VERSION ""

NS_ :

BS_:

BU_: BAU BCU

BO_ 3221225472 VECTOR__INDEPENDENT_SIG_MSG: 0 Vector__XXX
 SG_ VAR_SYS_PRECHRG_VOL : 0|16@1+ (0.1,0) [0|6553.5] "V" Vector__XXX
 SG_ CELL_INFO3 : 0|16@1- (1,0) [-32768|32767] "NAN" Vector__XXX
 SG_ CELL_INFO2 : 0|16@1- (1,0) [-32768|32767] "NAN" Vector__XXX
 SG_ CELL_INFO1 : 0|16@1- (1,0) [-32768|32767] "NAN" Vector__XXX
 SG_ INDEX : 0|10@1+ (1,0) [0|0] "" Vector__XXX
 SG_ SENT_INDEX : 0|2@1+ (1,0) [0|63] "" Vector__XXX
 SG_ SENT_TYPE : 0|4@1+ (1,0) [0|63] "" Vector__XXX
 SG_ VAR_SYS_PRECHRG_EEROR : 0|8@1+ (1,0) [0|255] "NAN" Vector__XXX

BO_ 2449731488 BCU1203EFA0: 64 BCU
 SG_ SINGLE_DISCHARGE_AH : 176|16@1+ (0.1,0) [0|6553.5] "AH" Vector__XXX
 SG_ SINGLE_DISCHARGE_EN : 160|16@1+ (0.1,0) [0|6553.5] "KWH" Vector__XXX
 SG_ SINGLE_CHARGE_AH : 144|16@1+ (0.1,0) [0|6553.5] "AH" Vector__XXX
 SG_ SINGLE_CHARGE_EN : 128|16@1+ (0.1,0) [0|6553.5] "KWH" Vector__XXX
 SG_ DAILY_DISCHARGE_AH : 112|16@1+ (0.1,0) [0|6553.5] "AH" Vector__XXX
 SG_ DAILY_DISCHARGE_EN : 96|16@1+ (0.1,0) [0|6553.5] "KWH" Vector__XXX
 SG_ DAILY_CHARGE_AH : 80|16@1+ (0.1,0) [0|6553.5] "AH" Vector__XXX
 SG_ DAILY_CHARGE_EN : 64|16@1+ (0.1,0) [0|6553.5] "KWH" Vector__XXX
 SG_ BCU_RUN_TIME : 32|32@1+ (1,0) [0|4294967295] "s" Vector__XXX
 SG_ BCU_ACC_RUN_TIME : 0|32@1+ (1,0) [0|4294967295] "min" Vector__XXX

BO_ 2462773152 BCU12CAEFA0: 64 BCU
 SG_ BALANCE_TEMP_ID_033 : 0|16@1- (0.1,0) [-3276.8|3276.7] "degC" Vector__XXX
 SG_ BALANCE_TEMP_ID_034 : 16|16@1- (0.1,0) [-3276.8|3276.7] "degC" Vector__XXX
 SG_ BALANCE_TEMP_ID_035 : 32|16@1- (0.1,0) [-3276.8|3276.7] "degC" Vector__XXX
 SG_ BALANCE_TEMP_ID_036 : 48|16@1- (0.1,0) [-3276.8|3276.7] "degC" Vector__XXX
 SG_ BALANCE_TEMP_ID_037 : 64|16@1- (0.1,0) [-3276.8|3276.7] "degC" Vector__XXX
 SG_ BALANCE_TEMP_ID_038 : 80|16@1- (0.1,0) [-3276.8|3276.7] "degC" Vector__XXX
 SG_ BALANCE_TEMP_ID_039 : 96|16@1- (0.1,0) [-3276.8|3276.7] "degC" Vector__XXX
 SG_ BALANCE_TEMP_ID_040 : 112|16@1- (0.1,0) [-3276.8|3276.7] "degC" Vector__XXX
 SG_ BALANCE_TEMP_ID_041 : 128|16@1- (0.1,0) [-3276.8|3276.7] "degC" Vector__XXX
 SG_ BALANCE_TEMP_ID_042 : 144|16@1- (0.1,0) [-3276.8|3276.7] "degC" Vector__XXX
 SG_ BALANCE_TEMP_ID_043 : 160|16@1- (0.1,0) [-3276.8|3276.7] "degC" Vector__XXX
 SG_ BALANCE_TEMP_ID_044 : 176|16@1- (0.1,0) [-3276.8|3276.7] "degC" Vector__XXX
 SG_ BALANCE_TEMP_ID_045 : 192|16@1- (0.1,0) [-3276.8|3276.7] "degC" Vector__XXX
 SG_ BALANCE_TEMP_ID_046 : 208|16@1- (0.1,0) [-3276.8|3276.7] "degC" Vector__XXX
 SG_ BALANCE_TEMP_ID_047 : 224|16@1- (0.1,0) [-3276.8|3276.7] "degC" Vector__XXX
 SG_ BALANCE_TEMP_ID_048 : 240|16@1- (0.1,0) [-3276.8|3276.7] "degC" Vector__XXX
 SG_ BALANCE_TEMP_ID_049 : 256|16@1- (0.1,0) [-3276.8|3276.7] "degC" Vector__XXX
 SG_ BALANCE_TEMP_ID_050 : 272|16@1- (0.1,0) [-3276.8|3276.7] "degC" Vector__XXX
 SG_ BALANCE_TEMP_ID_051 : 288|16@1- (0.1,0) [-3276.8|3276.7] "degC" Vector__XXX
 SG_ BALANCE_TEMP_ID_052 : 304|16@1- (0.1,0) [-3276.8|3276.7] "degC" Vector__XXX
 SG_ BALANCE_TEMP_ID_053 : 320|16@1- (0.1,0) [-3276.8|3276.7] "degC" Vector__XXX
 SG_ BALANCE_TEMP_ID_054 : 336|16@1- (0.1,0) [-3276.8|3276.7] "degC" Vector__XXX
 SG_ BALANCE_TEMP_ID_055 : 352|16@1- (0.1,0) [-3276.8|3276.7] "degC" Vector__XXX
 SG_ BALANCE_TEMP_ID_056 : 368|16@1- (0.1,0) [-3276.8|3276.7] "degC" Vector__XXX
 SG_ BALANCE_TEMP_ID_057 : 384|16@1- (0.1,0) [-3276.8|3276.7] "degC" Vector__XXX
 SG_ BALANCE_TEMP_ID_058 : 400|16@1- (0.1,0) [-3276.8|3276.7] "degC" Vector__XXX
 SG_ BALANCE_TEMP_ID_059 : 416|16@1- (0.1,0) [-3276.8|3276.7] "degC" Vector__XXX
 SG_ BALANCE_TEMP_ID_060 : 432|16@1- (0.1,0) [-3276.8|3276.7] "degC" Vector__XXX
 SG_ BALANCE_TEMP_ID_061 : 448|16@1- (0.1,0) [-3276.8|3276.7] "degC" Vector__XXX
 SG_ BALANCE_TEMP_ID_062 : 464|16@1- (0.1,0) [-3276.8|3276.7] "degC" Vector__XXX
 SG_ BALANCE_TEMP_ID_063 : 480|16@1- (0.1,0) [-3276.8|3276.7] "degC" Vector__XXX
 SG_ BALANCE_TEMP_ID_064 : 496|16@1- (0.1,0) [-3276.8|3276.7] "degC" Vector__XXX

BO_ 2462707616 BCU12C9EFA0: 64 BCU
 SG_ BALANCE_TEMP_ID_001 : 0|16@1- (0.1,0) [-3276.8|3276.7] "degC" Vector__XXX
 SG_ BALANCE_TEMP_ID_002 : 16|16@1- (0.1,0) [-3276.8|3276.7] "degC" Vector__XXX
 SG_ BALANCE_TEMP_ID_003 : 32|16@1- (0.1,0) [-3276.8|3276.7] "degC" Vector__XXX
 SG_ BALANCE_TEMP_ID_004 : 48|16@1- (0.1,0) [-3276.8|3276.7] "degC" Vector__XXX
 SG_ BALANCE_TEMP_ID_005 : 64|16@1- (0.1,0) [-3276.8|3276.7] "degC" Vector__XXX
 SG_ BALANCE_TEMP_ID_006 : 80|16@1- (0.1,0) [-3276.8|3276.7] "degC" Vector__XXX
 SG_ BALANCE_TEMP_ID_007 : 96|16@1- (0.1,0) [-3276.8|3276.7] "degC" Vector__XXX
 SG_ BALANCE_TEMP_ID_008 : 112|16@1- (0.1,0) [-3276.8|3276.7] "degC" Vector__XXX
 SG_ BALANCE_TEMP_ID_009 : 128|16@1- (0.1,0) [-3276.8|3276.7] "degC" Vector__XXX
 SG_ BALANCE_TEMP_ID_010 : 144|16@1- (0.1,0) [-3276.8|3276.7] "degC" Vector__XXX
 SG_ BALANCE_TEMP_ID_011 : 160|16@1- (0.1,0) [-3276.8|3276.7] "degC" Vector__XXX
 SG_ BALANCE_TEMP_ID_012 : 176|16@1- (0.1,0) [-3276.8|3276.7] "degC" Vector__XXX
 SG_ BALANCE_TEMP_ID_013 : 192|16@1- (0.1,0) [-3276.8|3276.7] "degC" Vector__XXX
 SG_ BALANCE_TEMP_ID_014 : 208|16@1- (0.1,0) [-3276.8|3276.7] "degC" Vector__XXX
 SG_ BALANCE_TEMP_ID_015 : 224|16@1- (0.1,0) [-3276.8|3276.7] "degC" Vector__XXX
 SG_ BALANCE_TEMP_ID_016 : 240|16@1- (0.1,0) [-3276.8|3276.7] "degC" Vector__XXX
 SG_ BALANCE_TEMP_ID_017 : 256|16@1- (0.1,0) [-3276.8|3276.7] "degC" Vector__XXX
 SG_ BALANCE_TEMP_ID_018 : 272|16@1- (0.1,0) [-3276.8|3276.7] "degC" Vector__XXX
 SG_ BALANCE_TEMP_ID_019 : 288|16@1- (0.1,0) [-3276.8|3276.7] "degC" Vector__XXX
 SG_ BALANCE_TEMP_ID_020 : 304|16@1- (0.1,0) [-3276.8|3276.7] "degC" Vector__XXX
 SG_ BALANCE_TEMP_ID_021 : 320|16@1- (0.1,0) [-3276.8|3276.7] "degC" Vector__XXX
 SG_ BALANCE_TEMP_ID_022 : 336|16@1- (0.1,0) [-3276.8|3276.7] "degC" Vector__XXX
 SG_ BALANCE_TEMP_ID_023 : 352|16@1- (0.1,0) [-3276.8|3276.7] "degC" Vector__XXX
 SG_ BALANCE_TEMP_ID_024 : 368|16@1- (0.1,0) [-3276.8|3276.7] "degC" Vector__XXX
 SG_ BALANCE_TEMP_ID_025 : 384|16@1- (0.1,0) [-3276.8|3276.7] "degC" Vector__XXX
 SG_ BALANCE_TEMP_ID_026 : 400|16@1- (0.1,0) [-3276.8|3276.7] "degC" Vector__XXX
 SG_ BALANCE_TEMP_ID_027 : 416|16@1- (0.1,0) [-3276.8|3276.7] "degC" Vector__XXX
 SG_ BALANCE_TEMP_ID_028 : 432|16@1- (0.1,0) [-3276.8|3276.7] "degC" Vector__XXX
 SG_ BALANCE_TEMP_ID_029 : 448|16@1- (0.1,0) [-3276.8|3276.7] "degC" Vector__XXX
 SG_ BALANCE_TEMP_ID_030 : 464|16@1- (0.1,0) [-3276.8|3276.7] "degC" Vector__XXX
 SG_ BALANCE_TEMP_ID_031 : 480|16@1- (0.1,0) [-3276.8|3276.7] "degC" Vector__XXX
 SG_ BALANCE_TEMP_ID_032 : 496|16@1- (0.1,0) [-3276.8|3276.7] "degC" Vector__XXX

BO_ 2462248864 BCU12C2EFA0: 64 BCU
 SG_ BCU_TERMINAL_TEMP_20_2 : 112|16@1- (0.1,0) [-3276.8|3276.7] "℃" Vector__XXX
 SG_ BCU_TERMINAL_TEMP_20_1 : 96|16@1- (0.1,0) [-3276.8|3276.7] "℃" Vector__XXX
 SG_ BCU_TERMINAL_TEMP_19_2 : 80|16@1- (0.1,0) [-3276.8|3276.7] "℃" Vector__XXX
 SG_ BCU_TERMINAL_TEMP_19_1 : 64|16@1- (0.1,0) [-3276.8|3276.7] "℃" Vector__XXX
 SG_ BCU_TERMINAL_TEMP_18_2 : 48|16@1- (0.1,0) [-3276.8|3276.7] "℃" Vector__XXX
 SG_ BCU_TERMINAL_TEMP_18_1 : 32|16@1- (0.1,0) [-3276.8|3276.7] "℃" Vector__XXX
 SG_ BCU_TERMINAL_TEMP_17_2 : 16|16@1- (0.1,0) [-3276.8|3276.7] "℃" Vector__XXX
 SG_ BCU_TERMINAL_TEMP_17_1 : 0|16@1- (0.1,0) [-3276.8|3276.7] "℃" Vector__XXX

BO_ 2462183328 BCU12C1EFA0: 64 BCU
 SG_ BCU_TERMINAL_TEMP_16_2 : 496|16@1- (0.1,0) [-3276.8|3276.7] "℃" Vector__XXX
 SG_ BCU_TERMINAL_TEMP_16_1 : 480|16@1- (0.1,0) [-3276.8|3276.7] "℃" Vector__XXX
 SG_ BCU_TERMINAL_TEMP_15_2 : 464|16@1- (0.1,0) [-3276.8|3276.7] "℃" Vector__XXX
 SG_ BCU_TERMINAL_TEMP_15_1 : 448|16@1- (0.1,0) [-3276.8|3276.7] "℃" Vector__XXX
 SG_ BCU_TERMINAL_TEMP_14_2 : 432|16@1- (0.1,0) [-3276.8|3276.7] "℃" Vector__XXX
 SG_ BCU_TERMINAL_TEMP_14_1 : 416|16@1- (0.1,0) [-3276.8|3276.7] "℃" Vector__XXX
 SG_ BCU_TERMINAL_TEMP_13_2 : 400|16@1- (0.1,0) [-3276.8|3276.7] "℃" Vector__XXX
 SG_ BCU_TERMINAL_TEMP_13_1 : 384|16@1- (0.1,0) [-3276.8|3276.7] "℃" Vector__XXX
 SG_ BCU_TERMINAL_TEMP_12_2 : 368|16@1- (0.1,0) [-3276.8|3276.7] "℃" Vector__XXX
 SG_ BCU_TERMINAL_TEMP_12_1 : 352|16@1- (0.1,0) [-3276.8|3276.7] "℃" Vector__XXX
 SG_ BCU_TERMINAL_TEMP_11_2 : 336|16@1- (0.1,0) [-3276.8|3276.7] "℃" Vector__XXX
 SG_ BCU_TERMINAL_TEMP_11_1 : 320|16@1- (0.1,0) [-3276.8|3276.7] "℃" Vector__XXX
 SG_ BCU_TERMINAL_TEMP_10_2 : 304|16@1- (0.1,0) [-3276.8|3276.7] "℃" Vector__XXX
 SG_ BCU_TERMINAL_TEMP_10_1 : 288|16@1- (0.1,0) [-3276.8|3276.7] "℃" Vector__XXX
 SG_ BCU_TERMINAL_TEMP_09_2 : 272|16@1- (0.1,0) [-3276.8|3276.7] "℃" Vector__XXX
 SG_ BCU_TERMINAL_TEMP_09_1 : 256|16@1- (0.1,0) [-3276.8|3276.7] "℃" Vector__XXX
 SG_ BCU_TERMINAL_TEMP_08_2 : 240|16@1- (0.1,0) [-3276.8|3276.7] "℃" Vector__XXX
 SG_ BCU_TERMINAL_TEMP_08_1 : 224|16@1- (0.1,0) [-3276.8|3276.7] "℃" Vector__XXX
 SG_ BCU_TERMINAL_TEMP_07_2 : 208|16@1- (0.1,0) [-3276.8|3276.7] "℃" Vector__XXX
 SG_ BCU_TERMINAL_TEMP_07_1 : 192|16@1- (0.1,0) [-3276.8|3276.7] "℃" Vector__XXX
 SG_ BCU_TERMINAL_TEMP_06_2 : 176|16@1- (0.1,0) [-3276.8|3276.7] "℃" Vector__XXX
 SG_ BCU_TERMINAL_TEMP_06_1 : 160|16@1- (0.1,0) [-3276.8|3276.7] "℃" Vector__XXX
 SG_ BCU_TERMINAL_TEMP_05_2 : 144|16@1- (0.1,0) [-3276.8|3276.7] "℃" Vector__XXX
 SG_ BCU_TERMINAL_TEMP_05_1 : 128|16@1- (0.1,0) [-3276.8|3276.7] "℃" Vector__XXX
 SG_ BCU_TERMINAL_TEMP_04_2 : 112|16@1- (0.1,0) [-3276.8|3276.7] "℃" Vector__XXX
 SG_ BCU_TERMINAL_TEMP_04_1 : 96|16@1- (0.1,0) [-3276.8|3276.7] "℃" Vector__XXX
 SG_ BCU_TERMINAL_TEMP_03_2 : 80|16@1- (0.1,0) [-3276.8|3276.7] "℃" Vector__XXX
 SG_ BCU_TERMINAL_TEMP_03_1 : 64|16@1- (0.1,0) [-3276.8|3276.7] "℃" Vector__XXX
 SG_ BCU_TERMINAL_TEMP_02_2 : 48|16@1- (0.1,0) [-3276.8|3276.7] "℃" Vector__XXX
 SG_ BCU_TERMINAL_TEMP_02_1 : 32|16@1- (0.1,0) [-3276.8|3276.7] "℃" Vector__XXX
 SG_ BCU_TERMINAL_TEMP_01_2 : 16|16@1- (0.1,0) [-3276.8|3276.7] "℃" Vector__XXX
 SG_ BCU_TERMINAL_TEMP_01_1 : 0|16@1- (0.1,0) [-3276.8|3276.7] "℃" Vector__XXX

BO_ 2462117792 BCU12C0EFA0: 64 BCU
 SG_ CELL_TEMP_ID_481 : 0|16@1- (0.1,0) [-3276.8|3276.7] "℃" Vector__XXX
 SG_ CELL_TEMP_ID_482 : 16|16@1- (0.1,0) [-3276.8|3276.7] "℃" Vector__XXX
 SG_ CELL_TEMP_ID_483 : 32|16@1- (0.1,0) [-3276.8|3276.7] "℃" Vector__XXX
 SG_ CELL_TEMP_ID_484 : 48|16@1- (0.1,0) [-3276.8|3276.7] "℃" Vector__XXX
 SG_ CELL_TEMP_ID_485 : 64|16@1- (0.1,0) [-3276.8|3276.7] "℃" Vector__XXX
 SG_ CELL_TEMP_ID_486 : 80|16@1- (0.1,0) [-3276.8|3276.7] "℃" Vector__XXX
 SG_ CELL_TEMP_ID_487 : 96|16@1- (0.1,0) [-3276.8|3276.7] "℃" Vector__XXX
 SG_ CELL_TEMP_ID_488 : 112|16@1- (0.1,0) [-3276.8|3276.7] "℃" Vector__XXX
 SG_ CELL_TEMP_ID_489 : 128|16@1- (0.1,0) [-3276.8|3276.7] "℃" Vector__XXX
 SG_ CELL_TEMP_ID_490 : 144|16@1- (0.1,0) [-3276.8|3276.7] "℃" Vector__XXX
 SG_ CELL_TEMP_ID_491 : 160|16@1- (0.1,0) [-3276.8|3276.7] "℃" Vector__XXX
 SG_ CELL_TEMP_ID_492 : 176|16@1- (0.1,0) [-3276.8|3276.7] "℃" Vector__XXX
 SG_ CELL_TEMP_ID_493 : 192|16@1- (0.1,0) [-3276.8|3276.7] "℃" Vector__XXX
 SG_ CELL_TEMP_ID_494 : 208|16@1- (0.1,0) [-3276.8|3276.7] "℃" Vector__XXX
 SG_ CELL_TEMP_ID_495 : 224|16@1- (0.1,0) [-3276.8|3276.7] "℃" Vector__XXX
 SG_ CELL_TEMP_ID_496 : 240|16@1- (0.1,0) [-3276.8|3276.7] "℃" Vector__XXX
 SG_ CELL_TEMP_ID_497 : 256|16@1- (0.1,0) [-3276.8|3276.7] "℃" Vector__XXX
 SG_ CELL_TEMP_ID_498 : 272|16@1- (0.1,0) [-3276.8|3276.7] "℃" Vector__XXX
 SG_ CELL_TEMP_ID_499 : 288|16@1- (0.1,0) [-3276.8|3276.7] "℃" Vector__XXX
 SG_ CELL_TEMP_ID_500 : 304|16@1- (0.1,0) [-3276.8|3276.7] "℃" Vector__XXX
 SG_ CELL_TEMP_ID_501 : 320|16@1- (0.1,0) [-3276.8|3276.7] "℃" Vector__XXX
 SG_ CELL_TEMP_ID_502 : 336|16@1- (0.1,0) [-3276.8|3276.7] "℃" Vector__XXX
 SG_ CELL_TEMP_ID_503 : 352|16@1- (0.1,0) [-3276.8|3276.7] "℃" Vector__XXX
 SG_ CELL_TEMP_ID_504 : 368|16@1- (0.1,0) [-3276.8|3276.7] "℃" Vector__XXX
 SG_ CELL_TEMP_ID_505 : 384|16@1- (0.1,0) [-3276.8|3276.7] "℃" Vector__XXX
 SG_ CELL_TEMP_ID_506 : 400|16@1- (0.1,0) [-3276.8|3276.7] "℃" Vector__XXX
 SG_ CELL_TEMP_ID_507 : 416|16@1- (0.1,0) [-3276.8|3276.7] "℃" Vector__XXX
 SG_ CELL_TEMP_ID_508 : 432|16@1- (0.1,0) [-3276.8|3276.7] "℃" Vector__XXX
 SG_ CELL_TEMP_ID_509 : 448|16@1- (0.1,0) [-3276.8|3276.7] "℃" Vector__XXX
 SG_ CELL_TEMP_ID_510 : 464|16@1- (0.1,0) [-3276.8|3276.7] "℃" Vector__XXX
 SG_ CELL_TEMP_ID_511 : 480|16@1- (0.1,0) [-3276.8|3276.7] "℃" Vector__XXX
 SG_ CELL_TEMP_ID_512 : 496|16@1- (0.1,0) [-3276.8|3276.7] "℃" Vector__XXX

BO_ 2462052256 BCU12BFEFA0: 64 BCU
 SG_ CELL_TEMP_ID_449 : 0|16@1- (0.1,0) [-3276.8|3276.7] "℃" Vector__XXX
 SG_ CELL_TEMP_ID_450 : 16|16@1- (0.1,0) [-3276.8|3276.7] "℃" Vector__XXX
 SG_ CELL_TEMP_ID_451 : 32|16@1- (0.1,0) [-3276.8|3276.7] "℃" Vector__XXX
 SG_ CELL_TEMP_ID_452 : 48|16@1- (0.1,0) [-3276.8|3276.7] "℃" Vector__XXX
 SG_ CELL_TEMP_ID_453 : 64|16@1- (0.1,0) [-3276.8|3276.7] "℃" Vector__XXX
 SG_ CELL_TEMP_ID_454 : 80|16@1- (0.1,0) [-3276.8|3276.7] "℃" Vector__XXX
 SG_ CELL_TEMP_ID_455 : 96|16@1- (0.1,0) [-3276.8|3276.7] "℃" Vector__XXX
 SG_ CELL_TEMP_ID_456 : 112|16@1- (0.1,0) [-3276.8|3276.7] "℃" Vector__XXX
 SG_ CELL_TEMP_ID_457 : 128|16@1- (0.1,0) [-3276.8|3276.7] "℃" Vector__XXX
 SG_ CELL_TEMP_ID_458 : 144|16@1- (0.1,0) [-3276.8|3276.7] "℃" Vector__XXX
 SG_ CELL_TEMP_ID_459 : 160|16@1- (0.1,0) [-3276.8|3276.7] "℃" Vector__XXX
 SG_ CELL_TEMP_ID_460 : 176|16@1- (0.1,0) [-3276.8|3276.7] "℃" Vector__XXX
 SG_ CELL_TEMP_ID_461 : 192|16@1- (0.1,0) [-3276.8|3276.7] "℃" Vector__XXX
 SG_ CELL_TEMP_ID_462 : 208|16@1- (0.1,0) [-3276.8|3276.7] "℃" Vector__XXX
 SG_ CELL_TEMP_ID_463 : 224|16@1- (0.1,0) [-3276.8|3276.7] "℃" Vector__XXX
 SG_ CELL_TEMP_ID_464 : 240|16@1- (0.1,0) [-3276.8|3276.7] "℃" Vector__XXX
 SG_ CELL_TEMP_ID_465 : 256|16@1- (0.1,0) [-3276.8|3276.7] "℃" Vector__XXX
 SG_ CELL_TEMP_ID_466 : 272|16@1- (0.1,0) [-3276.8|3276.7] "℃" Vector__XXX
 SG_ CELL_TEMP_ID_467 : 288|16@1- (0.1,0) [-3276.8|3276.7] "℃" Vector__XXX
 SG_ CELL_TEMP_ID_468 : 304|16@1- (0.1,0) [-3276.8|3276.7] "℃" Vector__XXX
 SG_ CELL_TEMP_ID_469 : 320|16@1- (0.1,0) [-3276.8|3276.7] "℃" Vector__XXX
 SG_ CELL_TEMP_ID_470 : 336|16@1- (0.1,0) [-3276.8|3276.7] "℃" Vector__XXX
 SG_ CELL_TEMP_ID_471 : 352|16@1- (0.1,0) [-3276.8|3276.7] "℃" Vector__XXX
 SG_ CELL_TEMP_ID_472 : 368|16@1- (0.1,0) [-3276.8|3276.7] "℃" Vector__XXX
 SG_ CELL_TEMP_ID_473 : 384|16@1- (0.1,0) [-3276.8|3276.7] "℃" Vector__XXX
 SG_ CELL_TEMP_ID_474 : 400|16@1- (0.1,0) [-3276.8|3276.7] "℃" Vector__XXX
 SG_ CELL_TEMP_ID_475 : 416|16@1- (0.1,0) [-3276.8|3276.7] "℃" Vector__XXX
 SG_ CELL_TEMP_ID_476 : 432|16@1- (0.1,0) [-3276.8|3276.7] "℃" Vector__XXX
 SG_ CELL_TEMP_ID_477 : 448|16@1- (0.1,0) [-3276.8|3276.7] "℃" Vector__XXX
 SG_ CELL_TEMP_ID_478 : 464|16@1- (0.1,0) [-3276.8|3276.7] "℃" Vector__XXX
 SG_ CELL_TEMP_ID_479 : 480|16@1- (0.1,0) [-3276.8|3276.7] "℃" Vector__XXX
 SG_ CELL_TEMP_ID_480 : 496|16@1- (0.1,0) [-3276.8|3276.7] "℃" Vector__XXX

BO_ 2461986720 BCU12BEEFA0: 64 BCU
 SG_ CELL_TEMP_ID_417 : 0|16@1- (0.1,0) [-3276.8|3276.7] "℃" Vector__XXX
 SG_ CELL_TEMP_ID_418 : 16|16@1- (0.1,0) [-3276.8|3276.7] "℃" Vector__XXX
 SG_ CELL_TEMP_ID_419 : 32|16@1- (0.1,0) [-3276.8|3276.7] "℃" Vector__XXX
 SG_ CELL_TEMP_ID_420 : 48|16@1- (0.1,0) [-3276.8|3276.7] "℃" Vector__XXX
 SG_ CELL_TEMP_ID_421 : 64|16@1- (0.1,0) [-3276.8|3276.7] "℃" Vector__XXX
 SG_ CELL_TEMP_ID_422 : 80|16@1- (0.1,0) [-3276.8|3276.7] "℃" Vector__XXX
 SG_ CELL_TEMP_ID_423 : 96|16@1- (0.1,0) [-3276.8|3276.7] "℃" Vector__XXX
 SG_ CELL_TEMP_ID_424 : 112|16@1- (0.1,0) [-3276.8|3276.7] "℃" Vector__XXX
 SG_ CELL_TEMP_ID_425 : 128|16@1- (0.1,0) [-3276.8|3276.7] "℃" Vector__XXX
 SG_ CELL_TEMP_ID_426 : 144|16@1- (0.1,0) [-3276.8|3276.7] "℃" Vector__XXX
 SG_ CELL_TEMP_ID_427 : 160|16@1- (0.1,0) [-3276.8|3276.7] "℃" Vector__XXX
 SG_ CELL_TEMP_ID_428 : 176|16@1- (0.1,0) [-3276.8|3276.7] "℃" Vector__XXX
 SG_ CELL_TEMP_ID_429 : 192|16@1- (0.1,0) [-3276.8|3276.7] "℃" Vector__XXX
 SG_ CELL_TEMP_ID_430 : 208|16@1- (0.1,0) [-3276.8|3276.7] "℃" Vector__XXX
 SG_ CELL_TEMP_ID_431 : 224|16@1- (0.1,0) [-3276.8|3276.7] "℃" Vector__XXX
 SG_ CELL_TEMP_ID_432 : 240|16@1- (0.1,0) [-3276.8|3276.7] "℃" Vector__XXX
 SG_ CELL_TEMP_ID_433 : 256|16@1- (0.1,0) [-3276.8|3276.7] "℃" Vector__XXX
 SG_ CELL_TEMP_ID_434 : 272|16@1- (0.1,0) [-3276.8|3276.7] "℃" Vector__XXX
 SG_ CELL_TEMP_ID_435 : 288|16@1- (0.1,0) [-3276.8|3276.7] "℃" Vector__XXX
 SG_ CELL_TEMP_ID_436 : 304|16@1- (0.1,0) [-3276.8|3276.7] "℃" Vector__XXX
 SG_ CELL_TEMP_ID_437 : 320|16@1- (0.1,0) [-3276.8|3276.7] "℃" Vector__XXX
 SG_ CELL_TEMP_ID_438 : 336|16@1- (0.1,0) [-3276.8|3276.7] "℃" Vector__XXX
 SG_ CELL_TEMP_ID_439 : 352|16@1- (0.1,0) [-3276.8|3276.7] "℃" Vector__XXX
 SG_ CELL_TEMP_ID_440 : 368|16@1- (0.1,0) [-3276.8|3276.7] "℃" Vector__XXX
 SG_ CELL_TEMP_ID_441 : 384|16@1- (0.1,0) [-3276.8|3276.7] "℃" Vector__XXX
 SG_ CELL_TEMP_ID_442 : 400|16@1- (0.1,0) [-3276.8|3276.7] "℃" Vector__XXX
 SG_ CELL_TEMP_ID_443 : 416|16@1- (0.1,0) [-3276.8|3276.7] "℃" Vector__XXX
 SG_ CELL_TEMP_ID_444 : 432|16@1- (0.1,0) [-3276.8|3276.7] "℃" Vector__XXX
 SG_ CELL_TEMP_ID_445 : 448|16@1- (0.1,0) [-3276.8|3276.7] "℃" Vector__XXX
 SG_ CELL_TEMP_ID_446 : 464|16@1- (0.1,0) [-3276.8|3276.7] "℃" Vector__XXX
 SG_ CELL_TEMP_ID_447 : 480|16@1- (0.1,0) [-3276.8|3276.7] "℃" Vector__XXX
 SG_ CELL_TEMP_ID_448 : 496|16@1- (0.1,0) [-3276.8|3276.7] "℃" Vector__XXX

BO_ 2461921184 BCU12BDEFA0: 64 BCU
 SG_ CELL_TEMP_ID_385 : 0|16@1- (0.1,0) [-3276.8|3276.7] "℃" Vector__XXX
 SG_ CELL_TEMP_ID_386 : 16|16@1- (0.1,0) [-3276.8|3276.7] "℃" Vector__XXX
 SG_ CELL_TEMP_ID_387 : 32|16@1- (0.1,0) [-3276.8|3276.7] "℃" Vector__XXX
 SG_ CELL_TEMP_ID_388 : 48|16@1- (0.1,0) [-3276.8|3276.7] "℃" Vector__XXX
 SG_ CELL_TEMP_ID_389 : 64|16@1- (0.1,0) [-3276.8|3276.7] "℃" Vector__XXX
 SG_ CELL_TEMP_ID_390 : 80|16@1- (0.1,0) [-3276.8|3276.7] "℃" Vector__XXX
 SG_ CELL_TEMP_ID_391 : 96|16@1- (0.1,0) [-3276.8|3276.7] "℃" Vector__XXX
 SG_ CELL_TEMP_ID_392 : 112|16@1- (0.1,0) [-3276.8|3276.7] "℃" Vector__XXX
 SG_ CELL_TEMP_ID_393 : 128|16@1- (0.1,0) [-3276.8|3276.7] "℃" Vector__XXX
 SG_ CELL_TEMP_ID_394 : 144|16@1- (0.1,0) [-3276.8|3276.7] "℃" Vector__XXX
 SG_ CELL_TEMP_ID_395 : 160|16@1- (0.1,0) [-3276.8|3276.7] "℃" Vector__XXX
 SG_ CELL_TEMP_ID_396 : 176|16@1- (0.1,0) [-3276.8|3276.7] "℃" Vector__XXX
 SG_ CELL_TEMP_ID_397 : 192|16@1- (0.1,0) [-3276.8|3276.7] "℃" Vector__XXX
 SG_ CELL_TEMP_ID_398 : 208|16@1- (0.1,0) [-3276.8|3276.7] "℃" Vector__XXX
 SG_ CELL_TEMP_ID_399 : 224|16@1- (0.1,0) [-3276.8|3276.7] "℃" Vector__XXX
 SG_ CELL_TEMP_ID_400 : 240|16@1- (0.1,0) [-3276.8|3276.7] "℃" Vector__XXX
 SG_ CELL_TEMP_ID_401 : 256|16@1- (0.1,0) [-3276.8|3276.7] "℃" Vector__XXX
 SG_ CELL_TEMP_ID_402 : 272|16@1- (0.1,0) [-3276.8|3276.7] "℃" Vector__XXX
 SG_ CELL_TEMP_ID_403 : 288|16@1- (0.1,0) [-3276.8|3276.7] "℃" Vector__XXX
 SG_ CELL_TEMP_ID_404 : 304|16@1- (0.1,0) [-3276.8|3276.7] "℃" Vector__XXX
 SG_ CELL_TEMP_ID_405 : 320|16@1- (0.1,0) [-3276.8|3276.7] "℃" Vector__XXX
 SG_ CELL_TEMP_ID_406 : 336|16@1- (0.1,0) [-3276.8|3276.7] "℃" Vector__XXX
 SG_ CELL_TEMP_ID_407 : 352|16@1- (0.1,0) [-3276.8|3276.7] "℃" Vector__XXX
 SG_ CELL_TEMP_ID_408 : 368|16@1- (0.1,0) [-3276.8|3276.7] "℃" Vector__XXX
 SG_ CELL_TEMP_ID_409 : 384|16@1- (0.1,0) [-3276.8|3276.7] "℃" Vector__XXX
 SG_ CELL_TEMP_ID_410 : 400|16@1- (0.1,0) [-3276.8|3276.7] "℃" Vector__XXX
 SG_ CELL_TEMP_ID_411 : 416|16@1- (0.1,0) [-3276.8|3276.7] "℃" Vector__XXX
 SG_ CELL_TEMP_ID_412 : 432|16@1- (0.1,0) [-3276.8|3276.7] "℃" Vector__XXX
 SG_ CELL_TEMP_ID_413 : 448|16@1- (0.1,0) [-3276.8|3276.7] "℃" Vector__XXX
 SG_ CELL_TEMP_ID_414 : 464|16@1- (0.1,0) [-3276.8|3276.7] "℃" Vector__XXX
 SG_ CELL_TEMP_ID_415 : 480|16@1- (0.1,0) [-3276.8|3276.7] "℃" Vector__XXX
 SG_ CELL_TEMP_ID_416 : 496|16@1- (0.1,0) [-3276.8|3276.7] "℃" Vector__XXX

BO_ 2461855648 BCU12BCEFA0: 64 BCU
 SG_ CELL_TEMP_ID_353 : 0|16@1- (0.1,0) [-3276.8|3276.7] "℃" Vector__XXX
 SG_ CELL_TEMP_ID_354 : 16|16@1- (0.1,0) [-3276.8|3276.7] "℃" Vector__XXX
 SG_ CELL_TEMP_ID_355 : 32|16@1- (0.1,0) [-3276.8|3276.7] "℃" Vector__XXX
 SG_ CELL_TEMP_ID_356 : 48|16@1- (0.1,0) [-3276.8|3276.7] "℃" Vector__XXX
 SG_ CELL_TEMP_ID_357 : 64|16@1- (0.1,0) [-3276.8|3276.7] "℃" Vector__XXX
 SG_ CELL_TEMP_ID_358 : 80|16@1- (0.1,0) [-3276.8|3276.7] "℃" Vector__XXX
 SG_ CELL_TEMP_ID_359 : 96|16@1- (0.1,0) [-3276.8|3276.7] "℃" Vector__XXX
 SG_ CELL_TEMP_ID_360 : 112|16@1- (0.1,0) [-3276.8|3276.7] "℃" Vector__XXX
 SG_ CELL_TEMP_ID_361 : 128|16@1- (0.1,0) [-3276.8|3276.7] "℃" Vector__XXX
 SG_ CELL_TEMP_ID_362 : 144|16@1- (0.1,0) [-3276.8|3276.7] "℃" Vector__XXX
 SG_ CELL_TEMP_ID_363 : 160|16@1- (0.1,0) [-3276.8|3276.7] "℃" Vector__XXX
 SG_ CELL_TEMP_ID_364 : 176|16@1- (0.1,0) [-3276.8|3276.7] "℃" Vector__XXX
 SG_ CELL_TEMP_ID_365 : 192|16@1- (0.1,0) [-3276.8|3276.7] "℃" Vector__XXX
 SG_ CELL_TEMP_ID_366 : 208|16@1- (0.1,0) [-3276.8|3276.7] "℃" Vector__XXX
 SG_ CELL_TEMP_ID_367 : 224|16@1- (0.1,0) [-3276.8|3276.7] "℃" Vector__XXX
 SG_ CELL_TEMP_ID_368 : 240|16@1- (0.1,0) [-3276.8|3276.7] "℃" Vector__XXX
 SG_ CELL_TEMP_ID_369 : 256|16@1- (0.1,0) [-3276.8|3276.7] "℃" Vector__XXX
 SG_ CELL_TEMP_ID_370 : 272|16@1- (0.1,0) [-3276.8|3276.7] "℃" Vector__XXX
 SG_ CELL_TEMP_ID_371 : 288|16@1- (0.1,0) [-3276.8|3276.7] "℃" Vector__XXX
 SG_ CELL_TEMP_ID_372 : 304|16@1- (0.1,0) [-3276.8|3276.7] "℃" Vector__XXX
 SG_ CELL_TEMP_ID_373 : 320|16@1- (0.1,0) [-3276.8|3276.7] "℃" Vector__XXX
 SG_ CELL_TEMP_ID_374 : 336|16@1- (0.1,0) [-3276.8|3276.7] "℃" Vector__XXX
 SG_ CELL_TEMP_ID_375 : 352|16@1- (0.1,0) [-3276.8|3276.7] "℃" Vector__XXX
 SG_ CELL_TEMP_ID_376 : 368|16@1- (0.1,0) [-3276.8|3276.7] "℃" Vector__XXX
 SG_ CELL_TEMP_ID_377 : 384|16@1- (0.1,0) [-3276.8|3276.7] "℃" Vector__XXX
 SG_ CELL_TEMP_ID_378 : 400|16@1- (0.1,0) [-3276.8|3276.7] "℃" Vector__XXX
 SG_ CELL_TEMP_ID_379 : 416|16@1- (0.1,0) [-3276.8|3276.7] "℃" Vector__XXX
 SG_ CELL_TEMP_ID_380 : 432|16@1- (0.1,0) [-3276.8|3276.7] "℃" Vector__XXX
 SG_ CELL_TEMP_ID_381 : 448|16@1- (0.1,0) [-3276.8|3276.7] "℃" Vector__XXX
 SG_ CELL_TEMP_ID_382 : 464|16@1- (0.1,0) [-3276.8|3276.7] "℃" Vector__XXX
 SG_ CELL_TEMP_ID_383 : 480|16@1- (0.1,0) [-3276.8|3276.7] "℃" Vector__XXX
 SG_ CELL_TEMP_ID_384 : 496|16@1- (0.1,0) [-3276.8|3276.7] "℃" Vector__XXX

BO_ 2461790112 BCU12BBEFA0: 64 BCU
 SG_ CELL_TEMP_ID_321 : 0|16@1- (0.1,0) [-3276.8|3276.7] "℃" Vector__XXX
 SG_ CELL_TEMP_ID_322 : 16|16@1- (0.1,0) [-3276.8|3276.7] "℃" Vector__XXX
 SG_ CELL_TEMP_ID_323 : 32|16@1- (0.1,0) [-3276.8|3276.7] "℃" Vector__XXX
 SG_ CELL_TEMP_ID_324 : 48|16@1- (0.1,0) [-3276.8|3276.7] "℃" Vector__XXX
 SG_ CELL_TEMP_ID_325 : 64|16@1- (0.1,0) [-3276.8|3276.7] "℃" Vector__XXX
 SG_ CELL_TEMP_ID_326 : 80|16@1- (0.1,0) [-3276.8|3276.7] "℃" Vector__XXX
 SG_ CELL_TEMP_ID_327 : 96|16@1- (0.1,0) [-3276.8|3276.7] "℃" Vector__XXX
 SG_ CELL_TEMP_ID_328 : 112|16@1- (0.1,0) [-3276.8|3276.7] "℃" Vector__XXX
 SG_ CELL_TEMP_ID_329 : 128|16@1- (0.1,0) [-3276.8|3276.7] "℃" Vector__XXX
 SG_ CELL_TEMP_ID_330 : 144|16@1- (0.1,0) [-3276.8|3276.7] "℃" Vector__XXX
 SG_ CELL_TEMP_ID_331 : 160|16@1- (0.1,0) [-3276.8|3276.7] "℃" Vector__XXX
 SG_ CELL_TEMP_ID_332 : 176|16@1- (0.1,0) [-3276.8|3276.7] "℃" Vector__XXX
 SG_ CELL_TEMP_ID_333 : 192|16@1- (0.1,0) [-3276.8|3276.7] "℃" Vector__XXX
 SG_ CELL_TEMP_ID_334 : 208|16@1- (0.1,0) [-3276.8|3276.7] "℃" Vector__XXX
 SG_ CELL_TEMP_ID_335 : 224|16@1- (0.1,0) [-3276.8|3276.7] "℃" Vector__XXX
 SG_ CELL_TEMP_ID_336 : 240|16@1- (0.1,0) [-3276.8|3276.7] "℃" Vector__XXX
 SG_ CELL_TEMP_ID_337 : 256|16@1- (0.1,0) [-3276.8|3276.7] "℃" Vector__XXX
 SG_ CELL_TEMP_ID_338 : 272|16@1- (0.1,0) [-3276.8|3276.7] "℃" Vector__XXX
 SG_ CELL_TEMP_ID_339 : 288|16@1- (0.1,0) [-3276.8|3276.7] "℃" Vector__XXX
 SG_ CELL_TEMP_ID_340 : 304|16@1- (0.1,0) [-3276.8|3276.7] "℃" Vector__XXX
 SG_ CELL_TEMP_ID_341 : 320|16@1- (0.1,0) [-3276.8|3276.7] "℃" Vector__XXX
 SG_ CELL_TEMP_ID_342 : 336|16@1- (0.1,0) [-3276.8|3276.7] "℃" Vector__XXX
 SG_ CELL_TEMP_ID_343 : 352|16@1- (0.1,0) [-3276.8|3276.7] "℃" Vector__XXX
 SG_ CELL_TEMP_ID_344 : 368|16@1- (0.1,0) [-3276.8|3276.7] "℃" Vector__XXX
 SG_ CELL_TEMP_ID_345 : 384|16@1- (0.1,0) [-3276.8|3276.7] "℃" Vector__XXX
 SG_ CELL_TEMP_ID_346 : 400|16@1- (0.1,0) [-3276.8|3276.7] "℃" Vector__XXX
 SG_ CELL_TEMP_ID_347 : 416|16@1- (0.1,0) [-3276.8|3276.7] "℃" Vector__XXX
 SG_ CELL_TEMP_ID_348 : 432|16@1- (0.1,0) [-3276.8|3276.7] "℃" Vector__XXX
 SG_ CELL_TEMP_ID_349 : 448|16@1- (0.1,0) [-3276.8|3276.7] "℃" Vector__XXX
 SG_ CELL_TEMP_ID_350 : 464|16@1- (0.1,0) [-3276.8|3276.7] "℃" Vector__XXX
 SG_ CELL_TEMP_ID_351 : 480|16@1- (0.1,0) [-3276.8|3276.7] "℃" Vector__XXX
 SG_ CELL_TEMP_ID_352 : 496|16@1- (0.1,0) [-3276.8|3276.7] "℃" Vector__XXX

BO_ 2461724576 BCU12BAEFA0: 64 BCU
 SG_ CELL_TEMP_ID_289 : 0|16@1- (0.1,0) [-3276.8|3276.7] "℃" Vector__XXX
 SG_ CELL_TEMP_ID_290 : 16|16@1- (0.1,0) [-3276.8|3276.7] "℃" Vector__XXX
 SG_ CELL_TEMP_ID_291 : 32|16@1- (0.1,0) [-3276.8|3276.7] "℃" Vector__XXX
 SG_ CELL_TEMP_ID_292 : 48|16@1- (0.1,0) [-3276.8|3276.7] "℃" Vector__XXX
 SG_ CELL_TEMP_ID_293 : 64|16@1- (0.1,0) [-3276.8|3276.7] "℃" Vector__XXX
 SG_ CELL_TEMP_ID_294 : 80|16@1- (0.1,0) [-3276.8|3276.7] "℃" Vector__XXX
 SG_ CELL_TEMP_ID_295 : 96|16@1- (0.1,0) [-3276.8|3276.7] "℃" Vector__XXX
 SG_ CELL_TEMP_ID_296 : 112|16@1- (0.1,0) [-3276.8|3276.7] "℃" Vector__XXX
 SG_ CELL_TEMP_ID_297 : 128|16@1- (0.1,0) [-3276.8|3276.7] "℃" Vector__XXX
 SG_ CELL_TEMP_ID_298 : 144|16@1- (0.1,0) [-3276.8|3276.7] "℃" Vector__XXX
 SG_ CELL_TEMP_ID_299 : 160|16@1- (0.1,0) [-3276.8|3276.7] "℃" Vector__XXX
 SG_ CELL_TEMP_ID_300 : 176|16@1- (0.1,0) [-3276.8|3276.7] "℃" Vector__XXX
 SG_ CELL_TEMP_ID_301 : 192|16@1- (0.1,0) [-3276.8|3276.7] "℃" Vector__XXX
 SG_ CELL_TEMP_ID_302 : 208|16@1- (0.1,0) [-3276.8|3276.7] "℃" Vector__XXX
 SG_ CELL_TEMP_ID_303 : 224|16@1- (0.1,0) [-3276.8|3276.7] "℃" Vector__XXX
 SG_ CELL_TEMP_ID_304 : 240|16@1- (0.1,0) [-3276.8|3276.7] "℃" Vector__XXX
 SG_ CELL_TEMP_ID_305 : 256|16@1- (0.1,0) [-3276.8|3276.7] "℃" Vector__XXX
 SG_ CELL_TEMP_ID_306 : 272|16@1- (0.1,0) [-3276.8|3276.7] "℃" Vector__XXX
 SG_ CELL_TEMP_ID_307 : 288|16@1- (0.1,0) [-3276.8|3276.7] "℃" Vector__XXX
 SG_ CELL_TEMP_ID_308 : 304|16@1- (0.1,0) [-3276.8|3276.7] "℃" Vector__XXX
 SG_ CELL_TEMP_ID_309 : 320|16@1- (0.1,0) [-3276.8|3276.7] "℃" Vector__XXX
 SG_ CELL_TEMP_ID_310 : 336|16@1- (0.1,0) [-3276.8|3276.7] "℃" Vector__XXX
 SG_ CELL_TEMP_ID_311 : 352|16@1- (0.1,0) [-3276.8|3276.7] "℃" Vector__XXX
 SG_ CELL_TEMP_ID_312 : 368|16@1- (0.1,0) [-3276.8|3276.7] "℃" Vector__XXX
 SG_ CELL_TEMP_ID_313 : 384|16@1- (0.1,0) [-3276.8|3276.7] "℃" Vector__XXX
 SG_ CELL_TEMP_ID_314 : 400|16@1- (0.1,0) [-3276.8|3276.7] "℃" Vector__XXX
 SG_ CELL_TEMP_ID_315 : 416|16@1- (0.1,0) [-3276.8|3276.7] "℃" Vector__XXX
 SG_ CELL_TEMP_ID_316 : 432|16@1- (0.1,0) [-3276.8|3276.7] "℃" Vector__XXX
 SG_ CELL_TEMP_ID_317 : 448|16@1- (0.1,0) [-3276.8|3276.7] "℃" Vector__XXX
 SG_ CELL_TEMP_ID_318 : 464|16@1- (0.1,0) [-3276.8|3276.7] "℃" Vector__XXX
 SG_ CELL_TEMP_ID_319 : 480|16@1- (0.1,0) [-3276.8|3276.7] "℃" Vector__XXX
 SG_ CELL_TEMP_ID_320 : 496|16@1- (0.1,0) [-3276.8|3276.7] "℃" Vector__XXX

BO_ 2461659040 BCU12B9EFA0: 64 BCU
 SG_ CELL_TEMP_ID_257 : 0|16@1- (0.1,0) [-3276.8|3276.7] "℃" Vector__XXX
 SG_ CELL_TEMP_ID_258 : 16|16@1- (0.1,0) [-3276.8|3276.7] "℃" Vector__XXX
 SG_ CELL_TEMP_ID_259 : 32|16@1- (0.1,0) [-3276.8|3276.7] "℃" Vector__XXX
 SG_ CELL_TEMP_ID_260 : 48|16@1- (0.1,0) [-3276.8|3276.7] "℃" Vector__XXX
 SG_ CELL_TEMP_ID_261 : 64|16@1- (0.1,0) [-3276.8|3276.7] "℃" Vector__XXX
 SG_ CELL_TEMP_ID_262 : 80|16@1- (0.1,0) [-3276.8|3276.7] "℃" Vector__XXX
 SG_ CELL_TEMP_ID_263 : 96|16@1- (0.1,0) [-3276.8|3276.7] "℃" Vector__XXX
 SG_ CELL_TEMP_ID_264 : 112|16@1- (0.1,0) [-3276.8|3276.7] "℃" Vector__XXX
 SG_ CELL_TEMP_ID_265 : 128|16@1- (0.1,0) [-3276.8|3276.7] "℃" Vector__XXX
 SG_ CELL_TEMP_ID_266 : 144|16@1- (0.1,0) [-3276.8|3276.7] "℃" Vector__XXX
 SG_ CELL_TEMP_ID_267 : 160|16@1- (0.1,0) [-3276.8|3276.7] "℃" Vector__XXX
 SG_ CELL_TEMP_ID_268 : 176|16@1- (0.1,0) [-3276.8|3276.7] "℃" Vector__XXX
 SG_ CELL_TEMP_ID_269 : 192|16@1- (0.1,0) [-3276.8|3276.7] "℃" Vector__XXX
 SG_ CELL_TEMP_ID_270 : 208|16@1- (0.1,0) [-3276.8|3276.7] "℃" Vector__XXX
 SG_ CELL_TEMP_ID_271 : 224|16@1- (0.1,0) [-3276.8|3276.7] "℃" Vector__XXX
 SG_ CELL_TEMP_ID_272 : 240|16@1- (0.1,0) [-3276.8|3276.7] "℃" Vector__XXX
 SG_ CELL_TEMP_ID_273 : 256|16@1- (0.1,0) [-3276.8|3276.7] "℃" Vector__XXX
 SG_ CELL_TEMP_ID_274 : 272|16@1- (0.1,0) [-3276.8|3276.7] "℃" Vector__XXX
 SG_ CELL_TEMP_ID_275 : 288|16@1- (0.1,0) [-3276.8|3276.7] "℃" Vector__XXX
 SG_ CELL_TEMP_ID_276 : 304|16@1- (0.1,0) [-3276.8|3276.7] "℃" Vector__XXX
 SG_ CELL_TEMP_ID_277 : 320|16@1- (0.1,0) [-3276.8|3276.7] "℃" Vector__XXX
 SG_ CELL_TEMP_ID_278 : 336|16@1- (0.1,0) [-3276.8|3276.7] "℃" Vector__XXX
 SG_ CELL_TEMP_ID_279 : 352|16@1- (0.1,0) [-3276.8|3276.7] "℃" Vector__XXX
 SG_ CELL_TEMP_ID_280 : 368|16@1- (0.1,0) [-3276.8|3276.7] "℃" Vector__XXX
 SG_ CELL_TEMP_ID_281 : 384|16@1- (0.1,0) [-3276.8|3276.7] "℃" Vector__XXX
 SG_ CELL_TEMP_ID_282 : 400|16@1- (0.1,0) [-3276.8|3276.7] "℃" Vector__XXX
 SG_ CELL_TEMP_ID_283 : 416|16@1- (0.1,0) [-3276.8|3276.7] "℃" Vector__XXX
 SG_ CELL_TEMP_ID_284 : 432|16@1- (0.1,0) [-3276.8|3276.7] "℃" Vector__XXX
 SG_ CELL_TEMP_ID_285 : 448|16@1- (0.1,0) [-3276.8|3276.7] "℃" Vector__XXX
 SG_ CELL_TEMP_ID_286 : 464|16@1- (0.1,0) [-3276.8|3276.7] "℃" Vector__XXX
 SG_ CELL_TEMP_ID_287 : 480|16@1- (0.1,0) [-3276.8|3276.7] "℃" Vector__XXX
 SG_ CELL_TEMP_ID_288 : 496|16@1- (0.1,0) [-3276.8|3276.7] "℃" Vector__XXX

BO_ 2461593504 BCU12B8EFA0: 64 BCU
 SG_ CELL_TEMP_ID_225 : 0|16@1- (0.1,0) [-3276.8|3276.7] "℃" Vector__XXX
 SG_ CELL_TEMP_ID_226 : 16|16@1- (0.1,0) [-3276.8|3276.7] "℃" Vector__XXX
 SG_ CELL_TEMP_ID_227 : 32|16@1- (0.1,0) [-3276.8|3276.7] "℃" Vector__XXX
 SG_ CELL_TEMP_ID_228 : 48|16@1- (0.1,0) [-3276.8|3276.7] "℃" Vector__XXX
 SG_ CELL_TEMP_ID_229 : 64|16@1- (0.1,0) [-3276.8|3276.7] "℃" Vector__XXX
 SG_ CELL_TEMP_ID_230 : 80|16@1- (0.1,0) [-3276.8|3276.7] "℃" Vector__XXX
 SG_ CELL_TEMP_ID_231 : 96|16@1- (0.1,0) [-3276.8|3276.7] "℃" Vector__XXX
 SG_ CELL_TEMP_ID_232 : 112|16@1- (0.1,0) [-3276.8|3276.7] "℃" Vector__XXX
 SG_ CELL_TEMP_ID_233 : 128|16@1- (0.1,0) [-3276.8|3276.7] "℃" Vector__XXX
 SG_ CELL_TEMP_ID_234 : 144|16@1- (0.1,0) [-3276.8|3276.7] "℃" Vector__XXX
 SG_ CELL_TEMP_ID_235 : 160|16@1- (0.1,0) [-3276.8|3276.7] "℃" Vector__XXX
 SG_ CELL_TEMP_ID_236 : 176|16@1- (0.1,0) [-3276.8|3276.7] "℃" Vector__XXX
 SG_ CELL_TEMP_ID_237 : 192|16@1- (0.1,0) [-3276.8|3276.7] "℃" Vector__XXX
 SG_ CELL_TEMP_ID_238 : 208|16@1- (0.1,0) [-3276.8|3276.7] "℃" Vector__XXX
 SG_ CELL_TEMP_ID_239 : 224|16@1- (0.1,0) [-3276.8|3276.7] "℃" Vector__XXX
 SG_ CELL_TEMP_ID_240 : 240|16@1- (0.1,0) [-3276.8|3276.7] "℃" Vector__XXX
 SG_ CELL_TEMP_ID_241 : 256|16@1- (0.1,0) [-3276.8|3276.7] "℃" Vector__XXX
 SG_ CELL_TEMP_ID_242 : 272|16@1- (0.1,0) [-3276.8|3276.7] "℃" Vector__XXX
 SG_ CELL_TEMP_ID_243 : 288|16@1- (0.1,0) [-3276.8|3276.7] "℃" Vector__XXX
 SG_ CELL_TEMP_ID_244 : 304|16@1- (0.1,0) [-3276.8|3276.7] "℃" Vector__XXX
 SG_ CELL_TEMP_ID_245 : 320|16@1- (0.1,0) [-3276.8|3276.7] "℃" Vector__XXX
 SG_ CELL_TEMP_ID_246 : 336|16@1- (0.1,0) [-3276.8|3276.7] "℃" Vector__XXX
 SG_ CELL_TEMP_ID_247 : 352|16@1- (0.1,0) [-3276.8|3276.7] "℃" Vector__XXX
 SG_ CELL_TEMP_ID_248 : 368|16@1- (0.1,0) [-3276.8|3276.7] "℃" Vector__XXX
 SG_ CELL_TEMP_ID_249 : 384|16@1- (0.1,0) [-3276.8|3276.7] "℃" Vector__XXX
 SG_ CELL_TEMP_ID_250 : 400|16@1- (0.1,0) [-3276.8|3276.7] "℃" Vector__XXX
 SG_ CELL_TEMP_ID_251 : 416|16@1- (0.1,0) [-3276.8|3276.7] "℃" Vector__XXX
 SG_ CELL_TEMP_ID_252 : 432|16@1- (0.1,0) [-3276.8|3276.7] "℃" Vector__XXX
 SG_ CELL_TEMP_ID_253 : 448|16@1- (0.1,0) [-3276.8|3276.7] "℃" Vector__XXX
 SG_ CELL_TEMP_ID_254 : 464|16@1- (0.1,0) [-3276.8|3276.7] "℃" Vector__XXX
 SG_ CELL_TEMP_ID_255 : 480|16@1- (0.1,0) [-3276.8|3276.7] "℃" Vector__XXX
 SG_ CELL_TEMP_ID_256 : 496|16@1- (0.1,0) [-3276.8|3276.7] "℃" Vector__XXX

BO_ 2461527968 BCU12B7EFA0: 64 BCU
 SG_ CELL_TEMP_ID_193 : 0|16@1- (0.1,0) [-3276.8|3276.7] "℃" Vector__XXX
 SG_ CELL_TEMP_ID_194 : 16|16@1- (0.1,0) [-3276.8|3276.7] "℃" Vector__XXX
 SG_ CELL_TEMP_ID_195 : 32|16@1- (0.1,0) [-3276.8|3276.7] "℃" Vector__XXX
 SG_ CELL_TEMP_ID_196 : 48|16@1- (0.1,0) [-3276.8|3276.7] "℃" Vector__XXX
 SG_ CELL_TEMP_ID_197 : 64|16@1- (0.1,0) [-3276.8|3276.7] "℃" Vector__XXX
 SG_ CELL_TEMP_ID_198 : 80|16@1- (0.1,0) [-3276.8|3276.7] "℃" Vector__XXX
 SG_ CELL_TEMP_ID_199 : 96|16@1- (0.1,0) [-3276.8|3276.7] "℃" Vector__XXX
 SG_ CELL_TEMP_ID_200 : 112|16@1- (0.1,0) [-3276.8|3276.7] "℃" Vector__XXX
 SG_ CELL_TEMP_ID_201 : 128|16@1- (0.1,0) [-3276.8|3276.7] "℃" Vector__XXX
 SG_ CELL_TEMP_ID_202 : 144|16@1- (0.1,0) [-3276.8|3276.7] "℃" Vector__XXX
 SG_ CELL_TEMP_ID_203 : 160|16@1- (0.1,0) [-3276.8|3276.7] "℃" Vector__XXX
 SG_ CELL_TEMP_ID_204 : 176|16@1- (0.1,0) [-3276.8|3276.7] "℃" Vector__XXX
 SG_ CELL_TEMP_ID_205 : 192|16@1- (0.1,0) [-3276.8|3276.7] "℃" Vector__XXX
 SG_ CELL_TEMP_ID_206 : 208|16@1- (0.1,0) [-3276.8|3276.7] "℃" Vector__XXX
 SG_ CELL_TEMP_ID_207 : 224|16@1- (0.1,0) [-3276.8|3276.7] "℃" Vector__XXX
 SG_ CELL_TEMP_ID_208 : 240|16@1- (0.1,0) [-3276.8|3276.7] "℃" Vector__XXX
 SG_ CELL_TEMP_ID_209 : 256|16@1- (0.1,0) [-3276.8|3276.7] "℃" Vector__XXX
 SG_ CELL_TEMP_ID_210 : 272|16@1- (0.1,0) [-3276.8|3276.7] "℃" Vector__XXX
 SG_ CELL_TEMP_ID_211 : 288|16@1- (0.1,0) [-3276.8|3276.7] "℃" Vector__XXX
 SG_ CELL_TEMP_ID_212 : 304|16@1- (0.1,0) [-3276.8|3276.7] "℃" Vector__XXX
 SG_ CELL_TEMP_ID_213 : 320|16@1- (0.1,0) [-3276.8|3276.7] "℃" Vector__XXX
 SG_ CELL_TEMP_ID_214 : 336|16@1- (0.1,0) [-3276.8|3276.7] "℃" Vector__XXX
 SG_ CELL_TEMP_ID_215 : 352|16@1- (0.1,0) [-3276.8|3276.7] "℃" Vector__XXX
 SG_ CELL_TEMP_ID_216 : 368|16@1- (0.1,0) [-3276.8|3276.7] "℃" Vector__XXX
 SG_ CELL_TEMP_ID_217 : 384|16@1- (0.1,0) [-3276.8|3276.7] "℃" Vector__XXX
 SG_ CELL_TEMP_ID_218 : 400|16@1- (0.1,0) [-3276.8|3276.7] "℃" Vector__XXX
 SG_ CELL_TEMP_ID_219 : 416|16@1- (0.1,0) [-3276.8|3276.7] "℃" Vector__XXX
 SG_ CELL_TEMP_ID_220 : 432|16@1- (0.1,0) [-3276.8|3276.7] "℃" Vector__XXX
 SG_ CELL_TEMP_ID_221 : 448|16@1- (0.1,0) [-3276.8|3276.7] "℃" Vector__XXX
 SG_ CELL_TEMP_ID_222 : 464|16@1- (0.1,0) [-3276.8|3276.7] "℃" Vector__XXX
 SG_ CELL_TEMP_ID_223 : 480|16@1- (0.1,0) [-3276.8|3276.7] "℃" Vector__XXX
 SG_ CELL_TEMP_ID_224 : 496|16@1- (0.1,0) [-3276.8|3276.7] "℃" Vector__XXX

BO_ 2461462432 BCU12B6EFA0: 64 BCU
 SG_ CELL_TEMP_ID_161 : 0|16@1- (0.1,0) [-3276.8|3276.7] "℃" Vector__XXX
 SG_ CELL_TEMP_ID_162 : 16|16@1- (0.1,0) [-3276.8|3276.7] "℃" Vector__XXX
 SG_ CELL_TEMP_ID_163 : 32|16@1- (0.1,0) [-3276.8|3276.7] "℃" Vector__XXX
 SG_ CELL_TEMP_ID_164 : 48|16@1- (0.1,0) [-3276.8|3276.7] "℃" Vector__XXX
 SG_ CELL_TEMP_ID_165 : 64|16@1- (0.1,0) [-3276.8|3276.7] "℃" Vector__XXX
 SG_ CELL_TEMP_ID_166 : 80|16@1- (0.1,0) [-3276.8|3276.7] "℃" Vector__XXX
 SG_ CELL_TEMP_ID_167 : 96|16@1- (0.1,0) [-3276.8|3276.7] "℃" Vector__XXX
 SG_ CELL_TEMP_ID_168 : 112|16@1- (0.1,0) [-3276.8|3276.7] "℃" Vector__XXX
 SG_ CELL_TEMP_ID_169 : 128|16@1- (0.1,0) [-3276.8|3276.7] "℃" Vector__XXX
 SG_ CELL_TEMP_ID_170 : 144|16@1- (0.1,0) [-3276.8|3276.7] "℃" Vector__XXX
 SG_ CELL_TEMP_ID_171 : 160|16@1- (0.1,0) [-3276.8|3276.7] "℃" Vector__XXX
 SG_ CELL_TEMP_ID_172 : 176|16@1- (0.1,0) [-3276.8|3276.7] "℃" Vector__XXX
 SG_ CELL_TEMP_ID_173 : 192|16@1- (0.1,0) [-3276.8|3276.7] "℃" Vector__XXX
 SG_ CELL_TEMP_ID_174 : 208|16@1- (0.1,0) [-3276.8|3276.7] "℃" Vector__XXX
 SG_ CELL_TEMP_ID_175 : 224|16@1- (0.1,0) [-3276.8|3276.7] "℃" Vector__XXX
 SG_ CELL_TEMP_ID_176 : 240|16@1- (0.1,0) [-3276.8|3276.7] "℃" Vector__XXX
 SG_ CELL_TEMP_ID_177 : 256|16@1- (0.1,0) [-3276.8|3276.7] "℃" Vector__XXX
 SG_ CELL_TEMP_ID_178 : 272|16@1- (0.1,0) [-3276.8|3276.7] "℃" Vector__XXX
 SG_ CELL_TEMP_ID_179 : 288|16@1- (0.1,0) [-3276.8|3276.7] "℃" Vector__XXX
 SG_ CELL_TEMP_ID_180 : 304|16@1- (0.1,0) [-3276.8|3276.7] "℃" Vector__XXX
 SG_ CELL_TEMP_ID_181 : 320|16@1- (0.1,0) [-3276.8|3276.7] "℃" Vector__XXX
 SG_ CELL_TEMP_ID_182 : 336|16@1- (0.1,0) [-3276.8|3276.7] "℃" Vector__XXX
 SG_ CELL_TEMP_ID_183 : 352|16@1- (0.1,0) [-3276.8|3276.7] "℃" Vector__XXX
 SG_ CELL_TEMP_ID_184 : 368|16@1- (0.1,0) [-3276.8|3276.7] "℃" Vector__XXX
 SG_ CELL_TEMP_ID_185 : 384|16@1- (0.1,0) [-3276.8|3276.7] "℃" Vector__XXX
 SG_ CELL_TEMP_ID_186 : 400|16@1- (0.1,0) [-3276.8|3276.7] "℃" Vector__XXX
 SG_ CELL_TEMP_ID_187 : 416|16@1- (0.1,0) [-3276.8|3276.7] "℃" Vector__XXX
 SG_ CELL_TEMP_ID_188 : 432|16@1- (0.1,0) [-3276.8|3276.7] "℃" Vector__XXX
 SG_ CELL_TEMP_ID_189 : 448|16@1- (0.1,0) [-3276.8|3276.7] "℃" Vector__XXX
 SG_ CELL_TEMP_ID_190 : 464|16@1- (0.1,0) [-3276.8|3276.7] "℃" Vector__XXX
 SG_ CELL_TEMP_ID_191 : 480|16@1- (0.1,0) [-3276.8|3276.7] "℃" Vector__XXX
 SG_ CELL_TEMP_ID_192 : 496|16@1- (0.1,0) [-3276.8|3276.7] "℃" Vector__XXX

BO_ 2461396896 BCU12B5EFA0: 64 BCU
 SG_ CELL_TEMP_ID_129 : 0|16@1- (0.1,0) [-3276.8|3276.7] "℃" Vector__XXX
 SG_ CELL_TEMP_ID_130 : 16|16@1- (0.1,0) [-3276.8|3276.7] "℃" Vector__XXX
 SG_ CELL_TEMP_ID_131 : 32|16@1- (0.1,0) [-3276.8|3276.7] "℃" Vector__XXX
 SG_ CELL_TEMP_ID_132 : 48|16@1- (0.1,0) [-3276.8|3276.7] "℃" Vector__XXX
 SG_ CELL_TEMP_ID_133 : 64|16@1- (0.1,0) [-3276.8|3276.7] "℃" Vector__XXX
 SG_ CELL_TEMP_ID_134 : 80|16@1- (0.1,0) [-3276.8|3276.7] "℃" Vector__XXX
 SG_ CELL_TEMP_ID_135 : 96|16@1- (0.1,0) [-3276.8|3276.7] "℃" Vector__XXX
 SG_ CELL_TEMP_ID_136 : 112|16@1- (0.1,0) [-3276.8|3276.7] "℃" Vector__XXX
 SG_ CELL_TEMP_ID_137 : 128|16@1- (0.1,0) [-3276.8|3276.7] "℃" Vector__XXX
 SG_ CELL_TEMP_ID_138 : 144|16@1- (0.1,0) [-3276.8|3276.7] "℃" Vector__XXX
 SG_ CELL_TEMP_ID_139 : 160|16@1- (0.1,0) [-3276.8|3276.7] "℃" Vector__XXX
 SG_ CELL_TEMP_ID_140 : 176|16@1- (0.1,0) [-3276.8|3276.7] "℃" Vector__XXX
 SG_ CELL_TEMP_ID_141 : 192|16@1- (0.1,0) [-3276.8|3276.7] "℃" Vector__XXX
 SG_ CELL_TEMP_ID_142 : 208|16@1- (0.1,0) [-3276.8|3276.7] "℃" Vector__XXX
 SG_ CELL_TEMP_ID_143 : 224|16@1- (0.1,0) [-3276.8|3276.7] "℃" Vector__XXX
 SG_ CELL_TEMP_ID_144 : 240|16@1- (0.1,0) [-3276.8|3276.7] "℃" Vector__XXX
 SG_ CELL_TEMP_ID_145 : 256|16@1- (0.1,0) [-3276.8|3276.7] "℃" Vector__XXX
 SG_ CELL_TEMP_ID_146 : 272|16@1- (0.1,0) [-3276.8|3276.7] "℃" Vector__XXX
 SG_ CELL_TEMP_ID_147 : 288|16@1- (0.1,0) [-3276.8|3276.7] "℃" Vector__XXX
 SG_ CELL_TEMP_ID_148 : 304|16@1- (0.1,0) [-3276.8|3276.7] "℃" Vector__XXX
 SG_ CELL_TEMP_ID_149 : 320|16@1- (0.1,0) [-3276.8|3276.7] "℃" Vector__XXX
 SG_ CELL_TEMP_ID_150 : 336|16@1- (0.1,0) [-3276.8|3276.7] "℃" Vector__XXX
 SG_ CELL_TEMP_ID_151 : 352|16@1- (0.1,0) [-3276.8|3276.7] "℃" Vector__XXX
 SG_ CELL_TEMP_ID_152 : 368|16@1- (0.1,0) [-3276.8|3276.7] "℃" Vector__XXX
 SG_ CELL_TEMP_ID_153 : 384|16@1- (0.1,0) [-3276.8|3276.7] "℃" Vector__XXX
 SG_ CELL_TEMP_ID_154 : 400|16@1- (0.1,0) [-3276.8|3276.7] "℃" Vector__XXX
 SG_ CELL_TEMP_ID_155 : 416|16@1- (0.1,0) [-3276.8|3276.7] "℃" Vector__XXX
 SG_ CELL_TEMP_ID_156 : 432|16@1- (0.1,0) [-3276.8|3276.7] "℃" Vector__XXX
 SG_ CELL_TEMP_ID_157 : 448|16@1- (0.1,0) [-3276.8|3276.7] "℃" Vector__XXX
 SG_ CELL_TEMP_ID_158 : 464|16@1- (0.1,0) [-3276.8|3276.7] "℃" Vector__XXX
 SG_ CELL_TEMP_ID_159 : 480|16@1- (0.1,0) [-3276.8|3276.7] "℃" Vector__XXX
 SG_ CELL_TEMP_ID_160 : 496|16@1- (0.1,0) [-3276.8|3276.7] "℃" Vector__XXX

BO_ 2461331360 BCU12B4EFA0: 64 BCU
 SG_ CELL_TEMP_ID_097 : 0|16@1- (0.1,0) [-3276.8|3276.7] "℃" Vector__XXX
 SG_ CELL_TEMP_ID_098 : 16|16@1- (0.1,0) [-3276.8|3276.7] "℃" Vector__XXX
 SG_ CELL_TEMP_ID_099 : 32|16@1- (0.1,0) [-3276.8|3276.7] "℃" Vector__XXX
 SG_ CELL_TEMP_ID_100 : 48|16@1- (0.1,0) [-3276.8|3276.7] "℃" Vector__XXX
 SG_ CELL_TEMP_ID_101 : 64|16@1- (0.1,0) [-3276.8|3276.7] "℃" Vector__XXX
 SG_ CELL_TEMP_ID_102 : 80|16@1- (0.1,0) [-3276.8|3276.7] "℃" Vector__XXX
 SG_ CELL_TEMP_ID_103 : 96|16@1- (0.1,0) [-3276.8|3276.7] "℃" Vector__XXX
 SG_ CELL_TEMP_ID_104 : 112|16@1- (0.1,0) [-3276.8|3276.7] "℃" Vector__XXX
 SG_ CELL_TEMP_ID_105 : 128|16@1- (0.1,0) [-3276.8|3276.7] "℃" Vector__XXX
 SG_ CELL_TEMP_ID_106 : 144|16@1- (0.1,0) [-3276.8|3276.7] "℃" Vector__XXX
 SG_ CELL_TEMP_ID_107 : 160|16@1- (0.1,0) [-3276.8|3276.7] "℃" Vector__XXX
 SG_ CELL_TEMP_ID_108 : 176|16@1- (0.1,0) [-3276.8|3276.7] "℃" Vector__XXX
 SG_ CELL_TEMP_ID_109 : 192|16@1- (0.1,0) [-3276.8|3276.7] "℃" Vector__XXX
 SG_ CELL_TEMP_ID_110 : 208|16@1- (0.1,0) [-3276.8|3276.7] "℃" Vector__XXX
 SG_ CELL_TEMP_ID_111 : 224|16@1- (0.1,0) [-3276.8|3276.7] "℃" Vector__XXX
 SG_ CELL_TEMP_ID_112 : 240|16@1- (0.1,0) [-3276.8|3276.7] "℃" Vector__XXX
 SG_ CELL_TEMP_ID_113 : 256|16@1- (0.1,0) [-3276.8|3276.7] "℃" Vector__XXX
 SG_ CELL_TEMP_ID_114 : 272|16@1- (0.1,0) [-3276.8|3276.7] "℃" Vector__XXX
 SG_ CELL_TEMP_ID_115 : 288|16@1- (0.1,0) [-3276.8|3276.7] "℃" Vector__XXX
 SG_ CELL_TEMP_ID_116 : 304|16@1- (0.1,0) [-3276.8|3276.7] "℃" Vector__XXX
 SG_ CELL_TEMP_ID_117 : 320|16@1- (0.1,0) [-3276.8|3276.7] "℃" Vector__XXX
 SG_ CELL_TEMP_ID_118 : 336|16@1- (0.1,0) [-3276.8|3276.7] "℃" Vector__XXX
 SG_ CELL_TEMP_ID_119 : 352|16@1- (0.1,0) [-3276.8|3276.7] "℃" Vector__XXX
 SG_ CELL_TEMP_ID_120 : 368|16@1- (0.1,0) [-3276.8|3276.7] "℃" Vector__XXX
 SG_ CELL_TEMP_ID_121 : 384|16@1- (0.1,0) [-3276.8|3276.7] "℃" Vector__XXX
 SG_ CELL_TEMP_ID_122 : 400|16@1- (0.1,0) [-3276.8|3276.7] "℃" Vector__XXX
 SG_ CELL_TEMP_ID_123 : 416|16@1- (0.1,0) [-3276.8|3276.7] "℃" Vector__XXX
 SG_ CELL_TEMP_ID_124 : 432|16@1- (0.1,0) [-3276.8|3276.7] "℃" Vector__XXX
 SG_ CELL_TEMP_ID_125 : 448|16@1- (0.1,0) [-3276.8|3276.7] "℃" Vector__XXX
 SG_ CELL_TEMP_ID_126 : 464|16@1- (0.1,0) [-3276.8|3276.7] "℃" Vector__XXX
 SG_ CELL_TEMP_ID_127 : 480|16@1- (0.1,0) [-3276.8|3276.7] "℃" Vector__XXX
 SG_ CELL_TEMP_ID_128 : 496|16@1- (0.1,0) [-3276.8|3276.7] "℃" Vector__XXX

BO_ 2461265824 BCU12B3EFA0: 64 BCU
 SG_ CELL_TEMP_ID_065 : 0|16@1- (0.1,0) [-3276.8|3276.7] "℃" Vector__XXX
 SG_ CELL_TEMP_ID_066 : 16|16@1- (0.1,0) [-3276.8|3276.7] "℃" Vector__XXX
 SG_ CELL_TEMP_ID_067 : 32|16@1- (0.1,0) [-3276.8|3276.7] "℃" Vector__XXX
 SG_ CELL_TEMP_ID_068 : 48|16@1- (0.1,0) [-3276.8|3276.7] "℃" Vector__XXX
 SG_ CELL_TEMP_ID_069 : 64|16@1- (0.1,0) [-3276.8|3276.7] "℃" Vector__XXX
 SG_ CELL_TEMP_ID_070 : 80|16@1- (0.1,0) [-3276.8|3276.7] "℃" Vector__XXX
 SG_ CELL_TEMP_ID_071 : 96|16@1- (0.1,0) [-3276.8|3276.7] "℃" Vector__XXX
 SG_ CELL_TEMP_ID_072 : 112|16@1- (0.1,0) [-3276.8|3276.7] "℃" Vector__XXX
 SG_ CELL_TEMP_ID_073 : 128|16@1- (0.1,0) [-3276.8|3276.7] "℃" Vector__XXX
 SG_ CELL_TEMP_ID_074 : 144|16@1- (0.1,0) [-3276.8|3276.7] "℃" Vector__XXX
 SG_ CELL_TEMP_ID_075 : 160|16@1- (0.1,0) [-3276.8|3276.7] "℃" Vector__XXX
 SG_ CELL_TEMP_ID_076 : 176|16@1- (0.1,0) [-3276.8|3276.7] "℃" Vector__XXX
 SG_ CELL_TEMP_ID_077 : 192|16@1- (0.1,0) [-3276.8|3276.7] "℃" Vector__XXX
 SG_ CELL_TEMP_ID_078 : 208|16@1- (0.1,0) [-3276.8|3276.7] "℃" Vector__XXX
 SG_ CELL_TEMP_ID_079 : 224|16@1- (0.1,0) [-3276.8|3276.7] "℃" Vector__XXX
 SG_ CELL_TEMP_ID_080 : 240|16@1- (0.1,0) [-3276.8|3276.7] "℃" Vector__XXX
 SG_ CELL_TEMP_ID_081 : 256|16@1- (0.1,0) [-3276.8|3276.7] "℃" Vector__XXX
 SG_ CELL_TEMP_ID_082 : 272|16@1- (0.1,0) [-3276.8|3276.7] "℃" Vector__XXX
 SG_ CELL_TEMP_ID_083 : 288|16@1- (0.1,0) [-3276.8|3276.7] "℃" Vector__XXX
 SG_ CELL_TEMP_ID_084 : 304|16@1- (0.1,0) [-3276.8|3276.7] "℃" Vector__XXX
 SG_ CELL_TEMP_ID_085 : 320|16@1- (0.1,0) [-3276.8|3276.7] "℃" Vector__XXX
 SG_ CELL_TEMP_ID_086 : 336|16@1- (0.1,0) [-3276.8|3276.7] "℃" Vector__XXX
 SG_ CELL_TEMP_ID_087 : 352|16@1- (0.1,0) [-3276.8|3276.7] "℃" Vector__XXX
 SG_ CELL_TEMP_ID_088 : 368|16@1- (0.1,0) [-3276.8|3276.7] "℃" Vector__XXX
 SG_ CELL_TEMP_ID_089 : 384|16@1- (0.1,0) [-3276.8|3276.7] "℃" Vector__XXX
 SG_ CELL_TEMP_ID_090 : 400|16@1- (0.1,0) [-3276.8|3276.7] "℃" Vector__XXX
 SG_ CELL_TEMP_ID_091 : 416|16@1- (0.1,0) [-3276.8|3276.7] "℃" Vector__XXX
 SG_ CELL_TEMP_ID_092 : 432|16@1- (0.1,0) [-3276.8|3276.7] "℃" Vector__XXX
 SG_ CELL_TEMP_ID_093 : 448|16@1- (0.1,0) [-3276.8|3276.7] "℃" Vector__XXX
 SG_ CELL_TEMP_ID_094 : 464|16@1- (0.1,0) [-3276.8|3276.7] "℃" Vector__XXX
 SG_ CELL_TEMP_ID_095 : 480|16@1- (0.1,0) [-3276.8|3276.7] "℃" Vector__XXX
 SG_ CELL_TEMP_ID_096 : 496|16@1- (0.1,0) [-3276.8|3276.7] "℃" Vector__XXX

BO_ 2461200288 BCU12B2EFA0: 64 BCU
 SG_ CELL_TEMP_ID_033 : 0|16@1- (0.1,0) [-3276.8|3276.7] "℃" Vector__XXX
 SG_ CELL_TEMP_ID_034 : 16|16@1- (0.1,0) [-3276.8|3276.7] "℃" Vector__XXX
 SG_ CELL_TEMP_ID_035 : 32|16@1- (0.1,0) [-3276.8|3276.7] "℃" Vector__XXX
 SG_ CELL_TEMP_ID_036 : 48|16@1- (0.1,0) [-3276.8|3276.7] "℃" Vector__XXX
 SG_ CELL_TEMP_ID_037 : 64|16@1- (0.1,0) [-3276.8|3276.7] "℃" Vector__XXX
 SG_ CELL_TEMP_ID_038 : 80|16@1- (0.1,0) [-3276.8|3276.7] "℃" Vector__XXX
 SG_ CELL_TEMP_ID_039 : 96|16@1- (0.1,0) [-3276.8|3276.7] "℃" Vector__XXX
 SG_ CELL_TEMP_ID_040 : 112|16@1- (0.1,0) [-3276.8|3276.7] "℃" Vector__XXX
 SG_ CELL_TEMP_ID_041 : 128|16@1- (0.1,0) [-3276.8|3276.7] "℃" Vector__XXX
 SG_ CELL_TEMP_ID_042 : 144|16@1- (0.1,0) [-3276.8|3276.7] "℃" Vector__XXX
 SG_ CELL_TEMP_ID_043 : 160|16@1- (0.1,0) [-3276.8|3276.7] "℃" Vector__XXX
 SG_ CELL_TEMP_ID_044 : 176|16@1- (0.1,0) [-3276.8|3276.7] "℃" Vector__XXX
 SG_ CELL_TEMP_ID_045 : 192|16@1- (0.1,0) [-3276.8|3276.7] "℃" Vector__XXX
 SG_ CELL_TEMP_ID_046 : 208|16@1- (0.1,0) [-3276.8|3276.7] "℃" Vector__XXX
 SG_ CELL_TEMP_ID_047 : 224|16@1- (0.1,0) [-3276.8|3276.7] "℃" Vector__XXX
 SG_ CELL_TEMP_ID_048 : 240|16@1- (0.1,0) [-3276.8|3276.7] "℃" Vector__XXX
 SG_ CELL_TEMP_ID_049 : 256|16@1- (0.1,0) [-3276.8|3276.7] "℃" Vector__XXX
 SG_ CELL_TEMP_ID_050 : 272|16@1- (0.1,0) [-3276.8|3276.7] "℃" Vector__XXX
 SG_ CELL_TEMP_ID_051 : 288|16@1- (0.1,0) [-3276.8|3276.7] "℃" Vector__XXX
 SG_ CELL_TEMP_ID_052 : 304|16@1- (0.1,0) [-3276.8|3276.7] "℃" Vector__XXX
 SG_ CELL_TEMP_ID_053 : 320|16@1- (0.1,0) [-3276.8|3276.7] "℃" Vector__XXX
 SG_ CELL_TEMP_ID_054 : 336|16@1- (0.1,0) [-3276.8|3276.7] "℃" Vector__XXX
 SG_ CELL_TEMP_ID_055 : 352|16@1- (0.1,0) [-3276.8|3276.7] "℃" Vector__XXX
 SG_ CELL_TEMP_ID_056 : 368|16@1- (0.1,0) [-3276.8|3276.7] "℃" Vector__XXX
 SG_ CELL_TEMP_ID_057 : 384|16@1- (0.1,0) [-3276.8|3276.7] "℃" Vector__XXX
 SG_ CELL_TEMP_ID_058 : 400|16@1- (0.1,0) [-3276.8|3276.7] "℃" Vector__XXX
 SG_ CELL_TEMP_ID_059 : 416|16@1- (0.1,0) [-3276.8|3276.7] "℃" Vector__XXX
 SG_ CELL_TEMP_ID_060 : 432|16@1- (0.1,0) [-3276.8|3276.7] "℃" Vector__XXX
 SG_ CELL_TEMP_ID_061 : 448|16@1- (0.1,0) [-3276.8|3276.7] "℃" Vector__XXX
 SG_ CELL_TEMP_ID_062 : 464|16@1- (0.1,0) [-3276.8|3276.7] "℃" Vector__XXX
 SG_ CELL_TEMP_ID_063 : 480|16@1- (0.1,0) [-3276.8|3276.7] "℃" Vector__XXX
 SG_ CELL_TEMP_ID_064 : 496|16@1- (0.1,0) [-3276.8|3276.7] "℃" Vector__XXX

BO_ 2461134752 BCU12B1EFA0: 64 BCU
 SG_ CELL_TEMP_ID_001 : 0|16@1- (0.1,0) [-3276.8|3276.7] "℃" Vector__XXX
 SG_ CELL_TEMP_ID_002 : 16|16@1- (0.1,0) [-3276.8|3276.7] "℃" Vector__XXX
 SG_ CELL_TEMP_ID_003 : 32|16@1- (0.1,0) [-3276.8|3276.7] "℃" Vector__XXX
 SG_ CELL_TEMP_ID_004 : 48|16@1- (0.1,0) [-3276.8|3276.7] "℃" Vector__XXX
 SG_ CELL_TEMP_ID_005 : 64|16@1- (0.1,0) [-3276.8|3276.7] "℃" Vector__XXX
 SG_ CELL_TEMP_ID_006 : 80|16@1- (0.1,0) [-3276.8|3276.7] "℃" Vector__XXX
 SG_ CELL_TEMP_ID_007 : 96|16@1- (0.1,0) [-3276.8|3276.7] "℃" Vector__XXX
 SG_ CELL_TEMP_ID_008 : 112|16@1- (0.1,0) [-3276.8|3276.7] "℃" Vector__XXX
 SG_ CELL_TEMP_ID_009 : 128|16@1- (0.1,0) [-3276.8|3276.7] "℃" Vector__XXX
 SG_ CELL_TEMP_ID_010 : 144|16@1- (0.1,0) [-3276.8|3276.7] "℃" Vector__XXX
 SG_ CELL_TEMP_ID_011 : 160|16@1- (0.1,0) [-3276.8|3276.7] "℃" Vector__XXX
 SG_ CELL_TEMP_ID_012 : 176|16@1- (0.1,0) [-3276.8|3276.7] "℃" Vector__XXX
 SG_ CELL_TEMP_ID_013 : 192|16@1- (0.1,0) [-3276.8|3276.7] "℃" Vector__XXX
 SG_ CELL_TEMP_ID_014 : 208|16@1- (0.1,0) [-3276.8|3276.7] "℃" Vector__XXX
 SG_ CELL_TEMP_ID_015 : 224|16@1- (0.1,0) [-3276.8|3276.7] "℃" Vector__XXX
 SG_ CELL_TEMP_ID_016 : 240|16@1- (0.1,0) [-3276.8|3276.7] "℃" Vector__XXX
 SG_ CELL_TEMP_ID_017 : 256|16@1- (0.1,0) [-3276.8|3276.7] "℃" Vector__XXX
 SG_ CELL_TEMP_ID_018 : 272|16@1- (0.1,0) [-3276.8|3276.7] "℃" Vector__XXX
 SG_ CELL_TEMP_ID_019 : 288|16@1- (0.1,0) [-3276.8|3276.7] "℃" Vector__XXX
 SG_ CELL_TEMP_ID_020 : 304|16@1- (0.1,0) [-3276.8|3276.7] "℃" Vector__XXX
 SG_ CELL_TEMP_ID_021 : 320|16@1- (0.1,0) [-3276.8|3276.7] "℃" Vector__XXX
 SG_ CELL_TEMP_ID_022 : 336|16@1- (0.1,0) [-3276.8|3276.7] "℃" Vector__XXX
 SG_ CELL_TEMP_ID_023 : 352|16@1- (0.1,0) [-3276.8|3276.7] "℃" Vector__XXX
 SG_ CELL_TEMP_ID_024 : 368|16@1- (0.1,0) [-3276.8|3276.7] "℃" Vector__XXX
 SG_ CELL_TEMP_ID_025 : 384|16@1- (0.1,0) [-3276.8|3276.7] "℃" Vector__XXX
 SG_ CELL_TEMP_ID_026 : 400|16@1- (0.1,0) [-3276.8|3276.7] "℃" Vector__XXX
 SG_ CELL_TEMP_ID_027 : 416|16@1- (0.1,0) [-3276.8|3276.7] "℃" Vector__XXX
 SG_ CELL_TEMP_ID_028 : 432|16@1- (0.1,0) [-3276.8|3276.7] "℃" Vector__XXX
 SG_ CELL_TEMP_ID_029 : 448|16@1- (0.1,0) [-3276.8|3276.7] "℃" Vector__XXX
 SG_ CELL_TEMP_ID_030 : 464|16@1- (0.1,0) [-3276.8|3276.7] "℃" Vector__XXX
 SG_ CELL_TEMP_ID_031 : 480|16@1- (0.1,0) [-3276.8|3276.7] "℃" Vector__XXX
 SG_ CELL_TEMP_ID_032 : 496|16@1- (0.1,0) [-3276.8|3276.7] "℃" Vector__XXX

BO_ 2461069216 BCU12B0EFA0: 64 BCU
 SG_ CELL_VOL_ID_512 : 496|16@1+ (1,0) [0|65535] "mV" Vector__XXX
 SG_ CELL_VOL_ID_511 : 480|16@1+ (1,0) [0|65535] "mV" Vector__XXX
 SG_ CELL_VOL_ID_510 : 464|16@1+ (1,0) [0|65535] "mV" Vector__XXX
 SG_ CELL_VOL_ID_509 : 448|16@1+ (1,0) [0|65535] "mV" Vector__XXX
 SG_ CELL_VOL_ID_508 : 432|16@1+ (1,0) [0|65535] "mV" Vector__XXX
 SG_ CELL_VOL_ID_507 : 416|16@1+ (1,0) [0|65535] "mV" Vector__XXX
 SG_ CELL_VOL_ID_506 : 400|16@1+ (1,0) [0|65535] "mV" Vector__XXX
 SG_ CELL_VOL_ID_505 : 384|16@1+ (1,0) [0|65535] "mV" Vector__XXX
 SG_ CELL_VOL_ID_504 : 368|16@1+ (1,0) [0|65535] "mV" Vector__XXX
 SG_ CELL_VOL_ID_503 : 352|16@1+ (1,0) [0|65535] "mV" Vector__XXX
 SG_ CELL_VOL_ID_502 : 336|16@1+ (1,0) [0|65535] "mV" Vector__XXX
 SG_ CELL_VOL_ID_501 : 320|16@1+ (1,0) [0|65535] "mV" Vector__XXX
 SG_ CELL_VOL_ID_500 : 304|16@1+ (1,0) [0|65535] "mV" Vector__XXX
 SG_ CELL_VOL_ID_499 : 288|16@1+ (1,0) [0|65535] "mV" Vector__XXX
 SG_ CELL_VOL_ID_498 : 272|16@1+ (1,0) [0|65535] "mV" Vector__XXX
 SG_ CELL_VOL_ID_497 : 256|16@1+ (1,0) [0|65535] "mV" Vector__XXX
 SG_ CELL_VOL_ID_496 : 240|16@1+ (1,0) [0|65535] "mV" Vector__XXX
 SG_ CELL_VOL_ID_495 : 224|16@1+ (1,0) [0|65535] "mV" Vector__XXX
 SG_ CELL_VOL_ID_494 : 208|16@1+ (1,0) [0|65535] "mV" Vector__XXX
 SG_ CELL_VOL_ID_493 : 192|16@1+ (1,0) [0|65535] "mV" Vector__XXX
 SG_ CELL_VOL_ID_492 : 176|16@1+ (1,0) [0|65535] "mV" Vector__XXX
 SG_ CELL_VOL_ID_491 : 160|16@1+ (1,0) [0|65535] "mV" Vector__XXX
 SG_ CELL_VOL_ID_490 : 144|16@1+ (1,0) [0|65535] "mV" Vector__XXX
 SG_ CELL_VOL_ID_489 : 128|16@1+ (1,0) [0|65535] "mV" Vector__XXX
 SG_ CELL_VOL_ID_488 : 112|16@1+ (1,0) [0|65535] "mV" Vector__XXX
 SG_ CELL_VOL_ID_487 : 96|16@1+ (1,0) [0|65535] "mV" Vector__XXX
 SG_ CELL_VOL_ID_486 : 80|16@1+ (1,0) [0|65535] "mV" Vector__XXX
 SG_ CELL_VOL_ID_485 : 64|16@1+ (1,0) [0|65535] "mV" Vector__XXX
 SG_ CELL_VOL_ID_484 : 48|16@1+ (1,0) [0|65535] "mV" Vector__XXX
 SG_ CELL_VOL_ID_483 : 32|16@1+ (1,0) [0|65535] "mV" Vector__XXX
 SG_ CELL_VOL_ID_482 : 16|16@1+ (1,0) [0|65535] "mV" Vector__XXX
 SG_ CELL_VOL_ID_481 : 0|16@1+ (1,0) [0|65535] "mV" Vector__XXX

BO_ 2461003680 BCU12AFEFA0: 64 BCU
 SG_ CELL_VOL_ID_480 : 496|16@1+ (1,0) [0|65535] "mV" Vector__XXX
 SG_ CELL_VOL_ID_479 : 480|16@1+ (1,0) [0|65535] "mV" Vector__XXX
 SG_ CELL_VOL_ID_478 : 464|16@1+ (1,0) [0|65535] "mV" Vector__XXX
 SG_ CELL_VOL_ID_477 : 448|16@1+ (1,0) [0|65535] "mV" Vector__XXX
 SG_ CELL_VOL_ID_476 : 432|16@1+ (1,0) [0|65535] "mV" Vector__XXX
 SG_ CELL_VOL_ID_475 : 416|16@1+ (1,0) [0|65535] "mV" Vector__XXX
 SG_ CELL_VOL_ID_474 : 400|16@1+ (1,0) [0|65535] "mV" Vector__XXX
 SG_ CELL_VOL_ID_473 : 384|16@1+ (1,0) [0|65535] "mV" Vector__XXX
 SG_ CELL_VOL_ID_472 : 368|16@1+ (1,0) [0|65535] "mV" Vector__XXX
 SG_ CELL_VOL_ID_471 : 352|16@1+ (1,0) [0|65535] "mV" Vector__XXX
 SG_ CELL_VOL_ID_470 : 336|16@1+ (1,0) [0|65535] "mV" Vector__XXX
 SG_ CELL_VOL_ID_469 : 320|16@1+ (1,0) [0|65535] "mV" Vector__XXX
 SG_ CELL_VOL_ID_468 : 304|16@1+ (1,0) [0|65535] "mV" Vector__XXX
 SG_ CELL_VOL_ID_467 : 288|16@1+ (1,0) [0|65535] "mV" Vector__XXX
 SG_ CELL_VOL_ID_466 : 272|16@1+ (1,0) [0|65535] "mV" Vector__XXX
 SG_ CELL_VOL_ID_465 : 256|16@1+ (1,0) [0|65535] "mV" Vector__XXX
 SG_ CELL_VOL_ID_464 : 240|16@1+ (1,0) [0|65535] "mV" Vector__XXX
 SG_ CELL_VOL_ID_463 : 224|16@1+ (1,0) [0|65535] "mV" Vector__XXX
 SG_ CELL_VOL_ID_462 : 208|16@1+ (1,0) [0|65535] "mV" Vector__XXX
 SG_ CELL_VOL_ID_461 : 192|16@1+ (1,0) [0|65535] "mV" Vector__XXX
 SG_ CELL_VOL_ID_460 : 176|16@1+ (1,0) [0|65535] "mV" Vector__XXX
 SG_ CELL_VOL_ID_459 : 160|16@1+ (1,0) [0|65535] "mV" Vector__XXX
 SG_ CELL_VOL_ID_458 : 144|16@1+ (1,0) [0|65535] "mV" Vector__XXX
 SG_ CELL_VOL_ID_457 : 128|16@1+ (1,0) [0|65535] "mV" Vector__XXX
 SG_ CELL_VOL_ID_456 : 112|16@1+ (1,0) [0|65535] "mV" Vector__XXX
 SG_ CELL_VOL_ID_455 : 96|16@1+ (1,0) [0|65535] "mV" Vector__XXX
 SG_ CELL_VOL_ID_454 : 80|16@1+ (1,0) [0|65535] "mV" Vector__XXX
 SG_ CELL_VOL_ID_453 : 64|16@1+ (1,0) [0|65535] "mV" Vector__XXX
 SG_ CELL_VOL_ID_452 : 48|16@1+ (1,0) [0|65535] "mV" Vector__XXX
 SG_ CELL_VOL_ID_451 : 32|16@1+ (1,0) [0|65535] "mV" Vector__XXX
 SG_ CELL_VOL_ID_450 : 16|16@1+ (1,0) [0|65535] "mV" Vector__XXX
 SG_ CELL_VOL_ID_449 : 0|16@1+ (1,0) [0|65535] "mV" Vector__XXX

BO_ 2460938144 BCU12AEEFA0: 64 BCU
 SG_ CELL_VOL_ID_448 : 496|16@1+ (1,0) [0|65535] "mV" Vector__XXX
 SG_ CELL_VOL_ID_447 : 480|16@1+ (1,0) [0|65535] "mV" Vector__XXX
 SG_ CELL_VOL_ID_446 : 464|16@1+ (1,0) [0|65535] "mV" Vector__XXX
 SG_ CELL_VOL_ID_445 : 448|16@1+ (1,0) [0|65535] "mV" Vector__XXX
 SG_ CELL_VOL_ID_444 : 432|16@1+ (1,0) [0|65535] "mV" Vector__XXX
 SG_ CELL_VOL_ID_443 : 416|16@1+ (1,0) [0|65535] "mV" Vector__XXX
 SG_ CELL_VOL_ID_442 : 400|16@1+ (1,0) [0|65535] "mV" Vector__XXX
 SG_ CELL_VOL_ID_441 : 384|16@1+ (1,0) [0|65535] "mV" Vector__XXX
 SG_ CELL_VOL_ID_440 : 368|16@1+ (1,0) [0|65535] "mV" Vector__XXX
 SG_ CELL_VOL_ID_439 : 352|16@1+ (1,0) [0|65535] "mV" Vector__XXX
 SG_ CELL_VOL_ID_438 : 336|16@1+ (1,0) [0|65535] "mV" Vector__XXX
 SG_ CELL_VOL_ID_437 : 320|16@1+ (1,0) [0|65535] "mV" Vector__XXX
 SG_ CELL_VOL_ID_436 : 304|16@1+ (1,0) [0|65535] "mV" Vector__XXX
 SG_ CELL_VOL_ID_435 : 288|16@1+ (1,0) [0|65535] "mV" Vector__XXX
 SG_ CELL_VOL_ID_434 : 272|16@1+ (1,0) [0|65535] "mV" Vector__XXX
 SG_ CELL_VOL_ID_433 : 256|16@1+ (1,0) [0|65535] "mV" Vector__XXX
 SG_ CELL_VOL_ID_432 : 240|16@1+ (1,0) [0|65535] "mV" Vector__XXX
 SG_ CELL_VOL_ID_431 : 224|16@1+ (1,0) [0|65535] "mV" Vector__XXX
 SG_ CELL_VOL_ID_430 : 208|16@1+ (1,0) [0|65535] "mV" Vector__XXX
 SG_ CELL_VOL_ID_429 : 192|16@1+ (1,0) [0|65535] "mV" Vector__XXX
 SG_ CELL_VOL_ID_428 : 176|16@1+ (1,0) [0|65535] "mV" Vector__XXX
 SG_ CELL_VOL_ID_427 : 160|16@1+ (1,0) [0|65535] "mV" Vector__XXX
 SG_ CELL_VOL_ID_426 : 144|16@1+ (1,0) [0|65535] "mV" Vector__XXX
 SG_ CELL_VOL_ID_425 : 128|16@1+ (1,0) [0|65535] "mV" Vector__XXX
 SG_ CELL_VOL_ID_424 : 112|16@1+ (1,0) [0|65535] "mV" Vector__XXX
 SG_ CELL_VOL_ID_423 : 96|16@1+ (1,0) [0|65535] "mV" Vector__XXX
 SG_ CELL_VOL_ID_422 : 80|16@1+ (1,0) [0|65535] "mV" Vector__XXX
 SG_ CELL_VOL_ID_421 : 64|16@1+ (1,0) [0|65535] "mV" Vector__XXX
 SG_ CELL_VOL_ID_420 : 48|16@1+ (1,0) [0|65535] "mV" Vector__XXX
 SG_ CELL_VOL_ID_419 : 32|16@1+ (1,0) [0|65535] "mV" Vector__XXX
 SG_ CELL_VOL_ID_418 : 16|16@1+ (1,0) [0|65535] "mV" Vector__XXX
 SG_ CELL_VOL_ID_417 : 0|16@1+ (1,0) [0|65535] "mV" Vector__XXX

BO_ 2460872608 BCU12ADEFA0: 64 BCU
 SG_ CELL_VOL_ID_416 : 496|16@1+ (1,0) [0|65535] "mV" Vector__XXX
 SG_ CELL_VOL_ID_415 : 480|16@1+ (1,0) [0|65535] "mV" Vector__XXX
 SG_ CELL_VOL_ID_414 : 464|16@1+ (1,0) [0|65535] "mV" Vector__XXX
 SG_ CELL_VOL_ID_413 : 448|16@1+ (1,0) [0|65535] "mV" Vector__XXX
 SG_ CELL_VOL_ID_412 : 432|16@1+ (1,0) [0|65535] "mV" Vector__XXX
 SG_ CELL_VOL_ID_411 : 416|16@1+ (1,0) [0|65535] "mV" Vector__XXX
 SG_ CELL_VOL_ID_410 : 400|16@1+ (1,0) [0|65535] "mV" Vector__XXX
 SG_ CELL_VOL_ID_409 : 384|16@1+ (1,0) [0|65535] "mV" Vector__XXX
 SG_ CELL_VOL_ID_408 : 368|16@1+ (1,0) [0|65535] "mV" Vector__XXX
 SG_ CELL_VOL_ID_407 : 352|16@1+ (1,0) [0|65535] "mV" Vector__XXX
 SG_ CELL_VOL_ID_406 : 336|16@1+ (1,0) [0|65535] "mV" Vector__XXX
 SG_ CELL_VOL_ID_405 : 320|16@1+ (1,0) [0|65535] "mV" Vector__XXX
 SG_ CELL_VOL_ID_404 : 304|16@1+ (1,0) [0|65535] "mV" Vector__XXX
 SG_ CELL_VOL_ID_403 : 288|16@1+ (1,0) [0|65535] "mV" Vector__XXX
 SG_ CELL_VOL_ID_402 : 272|16@1+ (1,0) [0|65535] "mV" Vector__XXX
 SG_ CELL_VOL_ID_401 : 256|16@1+ (1,0) [0|65535] "mV" Vector__XXX
 SG_ CELL_VOL_ID_400 : 240|16@1+ (1,0) [0|65535] "mV" Vector__XXX
 SG_ CELL_VOL_ID_399 : 224|16@1+ (1,0) [0|65535] "mV" Vector__XXX
 SG_ CELL_VOL_ID_398 : 208|16@1+ (1,0) [0|65535] "mV" Vector__XXX
 SG_ CELL_VOL_ID_397 : 192|16@1+ (1,0) [0|65535] "mV" Vector__XXX
 SG_ CELL_VOL_ID_396 : 176|16@1+ (1,0) [0|65535] "mV" Vector__XXX
 SG_ CELL_VOL_ID_395 : 160|16@1+ (1,0) [0|65535] "mV" Vector__XXX
 SG_ CELL_VOL_ID_394 : 144|16@1+ (1,0) [0|65535] "mV" Vector__XXX
 SG_ CELL_VOL_ID_393 : 128|16@1+ (1,0) [0|65535] "mV" Vector__XXX
 SG_ CELL_VOL_ID_392 : 112|16@1+ (1,0) [0|65535] "mV" Vector__XXX
 SG_ CELL_VOL_ID_391 : 96|16@1+ (1,0) [0|65535] "mV" Vector__XXX
 SG_ CELL_VOL_ID_390 : 80|16@1+ (1,0) [0|65535] "mV" Vector__XXX
 SG_ CELL_VOL_ID_389 : 64|16@1+ (1,0) [0|65535] "mV" Vector__XXX
 SG_ CELL_VOL_ID_388 : 48|16@1+ (1,0) [0|65535] "mV" Vector__XXX
 SG_ CELL_VOL_ID_387 : 32|16@1+ (1,0) [0|65535] "mV" Vector__XXX
 SG_ CELL_VOL_ID_386 : 16|16@1+ (1,0) [0|65535] "mV" Vector__XXX
 SG_ CELL_VOL_ID_385 : 0|16@1+ (1,0) [0|65535] "mV" Vector__XXX

BO_ 2460807072 BCU12ACEFA0: 64 BCU
 SG_ CELL_VOL_ID_384 : 496|16@1+ (1,0) [0|65535] "mV" Vector__XXX
 SG_ CELL_VOL_ID_383 : 480|16@1+ (1,0) [0|65535] "mV" Vector__XXX
 SG_ CELL_VOL_ID_382 : 464|16@1+ (1,0) [0|65535] "mV" Vector__XXX
 SG_ CELL_VOL_ID_381 : 448|16@1+ (1,0) [0|65535] "mV" Vector__XXX
 SG_ CELL_VOL_ID_380 : 432|16@1+ (1,0) [0|65535] "mV" Vector__XXX
 SG_ CELL_VOL_ID_379 : 416|16@1+ (1,0) [0|65535] "mV" Vector__XXX
 SG_ CELL_VOL_ID_378 : 400|16@1+ (1,0) [0|65535] "mV" Vector__XXX
 SG_ CELL_VOL_ID_377 : 384|16@1+ (1,0) [0|65535] "mV" Vector__XXX
 SG_ CELL_VOL_ID_376 : 368|16@1+ (1,0) [0|65535] "mV" Vector__XXX
 SG_ CELL_VOL_ID_375 : 352|16@1+ (1,0) [0|65535] "mV" Vector__XXX
 SG_ CELL_VOL_ID_374 : 336|16@1+ (1,0) [0|65535] "mV" Vector__XXX
 SG_ CELL_VOL_ID_373 : 320|16@1+ (1,0) [0|65535] "mV" Vector__XXX
 SG_ CELL_VOL_ID_372 : 304|16@1+ (1,0) [0|65535] "mV" Vector__XXX
 SG_ CELL_VOL_ID_371 : 288|16@1+ (1,0) [0|65535] "mV" Vector__XXX
 SG_ CELL_VOL_ID_370 : 272|16@1+ (1,0) [0|65535] "mV" Vector__XXX
 SG_ CELL_VOL_ID_369 : 256|16@1+ (1,0) [0|65535] "mV" Vector__XXX
 SG_ CELL_VOL_ID_368 : 240|16@1+ (1,0) [0|65535] "mV" Vector__XXX
 SG_ CELL_VOL_ID_367 : 224|16@1+ (1,0) [0|65535] "mV" Vector__XXX
 SG_ CELL_VOL_ID_366 : 208|16@1+ (1,0) [0|65535] "mV" Vector__XXX
 SG_ CELL_VOL_ID_365 : 192|16@1+ (1,0) [0|65535] "mV" Vector__XXX
 SG_ CELL_VOL_ID_364 : 176|16@1+ (1,0) [0|65535] "mV" Vector__XXX
 SG_ CELL_VOL_ID_363 : 160|16@1+ (1,0) [0|65535] "mV" Vector__XXX
 SG_ CELL_VOL_ID_362 : 144|16@1+ (1,0) [0|65535] "mV" Vector__XXX
 SG_ CELL_VOL_ID_361 : 128|16@1+ (1,0) [0|65535] "mV" Vector__XXX
 SG_ CELL_VOL_ID_360 : 112|16@1+ (1,0) [0|65535] "mV" Vector__XXX
 SG_ CELL_VOL_ID_359 : 96|16@1+ (1,0) [0|65535] "mV" Vector__XXX
 SG_ CELL_VOL_ID_358 : 80|16@1+ (1,0) [0|65535] "mV" Vector__XXX
 SG_ CELL_VOL_ID_357 : 64|16@1+ (1,0) [0|65535] "mV" Vector__XXX
 SG_ CELL_VOL_ID_356 : 48|16@1+ (1,0) [0|65535] "mV" Vector__XXX
 SG_ CELL_VOL_ID_355 : 32|16@1+ (1,0) [0|65535] "mV" Vector__XXX
 SG_ CELL_VOL_ID_354 : 16|16@1+ (1,0) [0|65535] "mV" Vector__XXX
 SG_ CELL_VOL_ID_353 : 0|16@1+ (1,0) [0|65535] "mV" Vector__XXX

BO_ 2460741536 BCU12ABEFA0: 64 BCU
 SG_ CELL_VOL_ID_352 : 496|16@1+ (1,0) [0|65535] "mV" Vector__XXX
 SG_ CELL_VOL_ID_351 : 480|16@1+ (1,0) [0|65535] "mV" Vector__XXX
 SG_ CELL_VOL_ID_350 : 464|16@1+ (1,0) [0|65535] "mV" Vector__XXX
 SG_ CELL_VOL_ID_349 : 448|16@1+ (1,0) [0|65535] "mV" Vector__XXX
 SG_ CELL_VOL_ID_348 : 432|16@1+ (1,0) [0|65535] "mV" Vector__XXX
 SG_ CELL_VOL_ID_347 : 416|16@1+ (1,0) [0|65535] "mV" Vector__XXX
 SG_ CELL_VOL_ID_346 : 400|16@1+ (1,0) [0|65535] "mV" Vector__XXX
 SG_ CELL_VOL_ID_345 : 384|16@1+ (1,0) [0|65535] "mV" Vector__XXX
 SG_ CELL_VOL_ID_344 : 368|16@1+ (1,0) [0|65535] "mV" Vector__XXX
 SG_ CELL_VOL_ID_343 : 352|16@1+ (1,0) [0|65535] "mV" Vector__XXX
 SG_ CELL_VOL_ID_342 : 336|16@1+ (1,0) [0|65535] "mV" Vector__XXX
 SG_ CELL_VOL_ID_341 : 320|16@1+ (1,0) [0|65535] "mV" Vector__XXX
 SG_ CELL_VOL_ID_340 : 304|16@1+ (1,0) [0|65535] "mV" Vector__XXX
 SG_ CELL_VOL_ID_339 : 288|16@1+ (1,0) [0|65535] "mV" Vector__XXX
 SG_ CELL_VOL_ID_338 : 272|16@1+ (1,0) [0|65535] "mV" Vector__XXX
 SG_ CELL_VOL_ID_337 : 256|16@1+ (1,0) [0|65535] "mV" Vector__XXX
 SG_ CELL_VOL_ID_336 : 240|16@1+ (1,0) [0|65535] "mV" Vector__XXX
 SG_ CELL_VOL_ID_335 : 224|16@1+ (1,0) [0|65535] "mV" Vector__XXX
 SG_ CELL_VOL_ID_334 : 208|16@1+ (1,0) [0|65535] "mV" Vector__XXX
 SG_ CELL_VOL_ID_333 : 192|16@1+ (1,0) [0|65535] "mV" Vector__XXX
 SG_ CELL_VOL_ID_332 : 176|16@1+ (1,0) [0|65535] "mV" Vector__XXX
 SG_ CELL_VOL_ID_331 : 160|16@1+ (1,0) [0|65535] "mV" Vector__XXX
 SG_ CELL_VOL_ID_330 : 144|16@1+ (1,0) [0|65535] "mV" Vector__XXX
 SG_ CELL_VOL_ID_329 : 128|16@1+ (1,0) [0|65535] "mV" Vector__XXX
 SG_ CELL_VOL_ID_328 : 112|16@1+ (1,0) [0|65535] "mV" Vector__XXX
 SG_ CELL_VOL_ID_327 : 96|16@1+ (1,0) [0|65535] "mV" Vector__XXX
 SG_ CELL_VOL_ID_326 : 80|16@1+ (1,0) [0|65535] "mV" Vector__XXX
 SG_ CELL_VOL_ID_325 : 64|16@1+ (1,0) [0|65535] "mV" Vector__XXX
 SG_ CELL_VOL_ID_324 : 48|16@1+ (1,0) [0|65535] "mV" Vector__XXX
 SG_ CELL_VOL_ID_323 : 32|16@1+ (1,0) [0|65535] "mV" Vector__XXX
 SG_ CELL_VOL_ID_322 : 16|16@1+ (1,0) [0|65535] "mV" Vector__XXX
 SG_ CELL_VOL_ID_321 : 0|16@1+ (1,0) [0|65535] "mV" Vector__XXX

BO_ 2460676000 BCU12AAEFA0: 64 BCU
 SG_ CELL_VOL_ID_320 : 496|16@1+ (1,0) [0|65535] "mV" Vector__XXX
 SG_ CELL_VOL_ID_319 : 480|16@1+ (1,0) [0|65535] "mV" Vector__XXX
 SG_ CELL_VOL_ID_318 : 464|16@1+ (1,0) [0|65535] "mV" Vector__XXX
 SG_ CELL_VOL_ID_317 : 448|16@1+ (1,0) [0|65535] "mV" Vector__XXX
 SG_ CELL_VOL_ID_316 : 432|16@1+ (1,0) [0|65535] "mV" Vector__XXX
 SG_ CELL_VOL_ID_315 : 416|16@1+ (1,0) [0|65535] "mV" Vector__XXX
 SG_ CELL_VOL_ID_314 : 400|16@1+ (1,0) [0|65535] "mV" Vector__XXX
 SG_ CELL_VOL_ID_313 : 384|16@1+ (1,0) [0|65535] "mV" Vector__XXX
 SG_ CELL_VOL_ID_312 : 368|16@1+ (1,0) [0|65535] "mV" Vector__XXX
 SG_ CELL_VOL_ID_311 : 352|16@1+ (1,0) [0|65535] "mV" Vector__XXX
 SG_ CELL_VOL_ID_310 : 336|16@1+ (1,0) [0|65535] "mV" Vector__XXX
 SG_ CELL_VOL_ID_309 : 320|16@1+ (1,0) [0|65535] "mV" Vector__XXX
 SG_ CELL_VOL_ID_308 : 304|16@1+ (1,0) [0|65535] "mV" Vector__XXX
 SG_ CELL_VOL_ID_307 : 288|16@1+ (1,0) [0|65535] "mV" Vector__XXX
 SG_ CELL_VOL_ID_306 : 272|16@1+ (1,0) [0|65535] "mV" Vector__XXX
 SG_ CELL_VOL_ID_305 : 256|16@1+ (1,0) [0|65535] "mV" Vector__XXX
 SG_ CELL_VOL_ID_304 : 240|16@1+ (1,0) [0|65535] "mV" Vector__XXX
 SG_ CELL_VOL_ID_303 : 224|16@1+ (1,0) [0|65535] "mV" Vector__XXX
 SG_ CELL_VOL_ID_302 : 208|16@1+ (1,0) [0|65535] "mV" Vector__XXX
 SG_ CELL_VOL_ID_301 : 192|16@1+ (1,0) [0|65535] "mV" Vector__XXX
 SG_ CELL_VOL_ID_300 : 176|16@1+ (1,0) [0|65535] "mV" Vector__XXX
 SG_ CELL_VOL_ID_299 : 160|16@1+ (1,0) [0|65535] "mV" Vector__XXX
 SG_ CELL_VOL_ID_298 : 144|16@1+ (1,0) [0|65535] "mV" Vector__XXX
 SG_ CELL_VOL_ID_297 : 128|16@1+ (1,0) [0|65535] "mV" Vector__XXX
 SG_ CELL_VOL_ID_296 : 112|16@1+ (1,0) [0|65535] "mV" Vector__XXX
 SG_ CELL_VOL_ID_295 : 96|16@1+ (1,0) [0|65535] "mV" Vector__XXX
 SG_ CELL_VOL_ID_294 : 80|16@1+ (1,0) [0|65535] "mV" Vector__XXX
 SG_ CELL_VOL_ID_293 : 64|16@1+ (1,0) [0|65535] "mV" Vector__XXX
 SG_ CELL_VOL_ID_292 : 48|16@1+ (1,0) [0|65535] "mV" Vector__XXX
 SG_ CELL_VOL_ID_291 : 32|16@1+ (1,0) [0|65535] "mV" Vector__XXX
 SG_ CELL_VOL_ID_290 : 16|16@1+ (1,0) [0|65535] "mV" Vector__XXX
 SG_ CELL_VOL_ID_289 : 0|16@1+ (1,0) [0|65535] "mV" Vector__XXX

BO_ 2460610464 BCU12A9EFA0: 64 BCU
 SG_ CELL_VOL_ID_288 : 496|16@1+ (1,0) [0|65535] "mV" Vector__XXX
 SG_ CELL_VOL_ID_287 : 480|16@1+ (1,0) [0|65535] "mV" Vector__XXX
 SG_ CELL_VOL_ID_286 : 464|16@1+ (1,0) [0|65535] "mV" Vector__XXX
 SG_ CELL_VOL_ID_285 : 448|16@1+ (1,0) [0|65535] "mV" Vector__XXX
 SG_ CELL_VOL_ID_284 : 432|16@1+ (1,0) [0|65535] "mV" Vector__XXX
 SG_ CELL_VOL_ID_283 : 416|16@1+ (1,0) [0|65535] "mV" Vector__XXX
 SG_ CELL_VOL_ID_282 : 400|16@1+ (1,0) [0|65535] "mV" Vector__XXX
 SG_ CELL_VOL_ID_281 : 384|16@1+ (1,0) [0|65535] "mV" Vector__XXX
 SG_ CELL_VOL_ID_280 : 368|16@1+ (1,0) [0|65535] "mV" Vector__XXX
 SG_ CELL_VOL_ID_279 : 352|16@1+ (1,0) [0|65535] "mV" Vector__XXX
 SG_ CELL_VOL_ID_278 : 336|16@1+ (1,0) [0|65535] "mV" Vector__XXX
 SG_ CELL_VOL_ID_277 : 320|16@1+ (1,0) [0|65535] "mV" Vector__XXX
 SG_ CELL_VOL_ID_276 : 304|16@1+ (1,0) [0|65535] "mV" Vector__XXX
 SG_ CELL_VOL_ID_275 : 288|16@1+ (1,0) [0|65535] "mV" Vector__XXX
 SG_ CELL_VOL_ID_274 : 272|16@1+ (1,0) [0|65535] "mV" Vector__XXX
 SG_ CELL_VOL_ID_273 : 256|16@1+ (1,0) [0|65535] "mV" Vector__XXX
 SG_ CELL_VOL_ID_272 : 240|16@1+ (1,0) [0|65535] "mV" Vector__XXX
 SG_ CELL_VOL_ID_271 : 224|16@1+ (1,0) [0|65535] "mV" Vector__XXX
 SG_ CELL_VOL_ID_270 : 208|16@1+ (1,0) [0|65535] "mV" Vector__XXX
 SG_ CELL_VOL_ID_269 : 192|16@1+ (1,0) [0|65535] "mV" Vector__XXX
 SG_ CELL_VOL_ID_268 : 176|16@1+ (1,0) [0|65535] "mV" Vector__XXX
 SG_ CELL_VOL_ID_267 : 160|16@1+ (1,0) [0|65535] "mV" Vector__XXX
 SG_ CELL_VOL_ID_266 : 144|16@1+ (1,0) [0|65535] "mV" Vector__XXX
 SG_ CELL_VOL_ID_265 : 128|16@1+ (1,0) [0|65535] "mV" Vector__XXX
 SG_ CELL_VOL_ID_264 : 112|16@1+ (1,0) [0|65535] "mV" Vector__XXX
 SG_ CELL_VOL_ID_263 : 96|16@1+ (1,0) [0|65535] "mV" Vector__XXX
 SG_ CELL_VOL_ID_262 : 80|16@1+ (1,0) [0|65535] "mV" Vector__XXX
 SG_ CELL_VOL_ID_261 : 64|16@1+ (1,0) [0|65535] "mV" Vector__XXX
 SG_ CELL_VOL_ID_260 : 48|16@1+ (1,0) [0|65535] "mV" Vector__XXX
 SG_ CELL_VOL_ID_259 : 32|16@1+ (1,0) [0|65535] "mV" Vector__XXX
 SG_ CELL_VOL_ID_258 : 16|16@1+ (1,0) [0|65535] "mV" Vector__XXX
 SG_ CELL_VOL_ID_257 : 0|16@1+ (1,0) [0|65535] "mV" Vector__XXX

BO_ 2460544928 BCU12A8EFA0: 64 BCU
 SG_ CELL_VOL_ID_256 : 496|16@1+ (1,0) [0|65535] "mV" Vector__XXX
 SG_ CELL_VOL_ID_255 : 480|16@1+ (1,0) [0|65535] "mV" Vector__XXX
 SG_ CELL_VOL_ID_254 : 464|16@1+ (1,0) [0|65535] "mV" Vector__XXX
 SG_ CELL_VOL_ID_253 : 448|16@1+ (1,0) [0|65535] "mV" Vector__XXX
 SG_ CELL_VOL_ID_252 : 432|16@1+ (1,0) [0|65535] "mV" Vector__XXX
 SG_ CELL_VOL_ID_251 : 416|16@1+ (1,0) [0|65535] "mV" Vector__XXX
 SG_ CELL_VOL_ID_250 : 400|16@1+ (1,0) [0|65535] "mV" Vector__XXX
 SG_ CELL_VOL_ID_249 : 384|16@1+ (1,0) [0|65535] "mV" Vector__XXX
 SG_ CELL_VOL_ID_248 : 368|16@1+ (1,0) [0|65535] "mV" Vector__XXX
 SG_ CELL_VOL_ID_247 : 352|16@1+ (1,0) [0|65535] "mV" Vector__XXX
 SG_ CELL_VOL_ID_246 : 336|16@1+ (1,0) [0|65535] "mV" Vector__XXX
 SG_ CELL_VOL_ID_245 : 320|16@1+ (1,0) [0|65535] "mV" Vector__XXX
 SG_ CELL_VOL_ID_244 : 304|16@1+ (1,0) [0|65535] "mV" Vector__XXX
 SG_ CELL_VOL_ID_243 : 288|16@1+ (1,0) [0|65535] "mV" Vector__XXX
 SG_ CELL_VOL_ID_242 : 272|16@1+ (1,0) [0|65535] "mV" Vector__XXX
 SG_ CELL_VOL_ID_241 : 256|16@1+ (1,0) [0|65535] "mV" Vector__XXX
 SG_ CELL_VOL_ID_240 : 240|16@1+ (1,0) [0|65535] "mV" Vector__XXX
 SG_ CELL_VOL_ID_239 : 224|16@1+ (1,0) [0|65535] "mV" Vector__XXX
 SG_ CELL_VOL_ID_238 : 208|16@1+ (1,0) [0|65535] "mV" Vector__XXX
 SG_ CELL_VOL_ID_237 : 192|16@1+ (1,0) [0|65535] "mV" Vector__XXX
 SG_ CELL_VOL_ID_236 : 176|16@1+ (1,0) [0|65535] "mV" Vector__XXX
 SG_ CELL_VOL_ID_235 : 160|16@1+ (1,0) [0|65535] "mV" Vector__XXX
 SG_ CELL_VOL_ID_234 : 144|16@1+ (1,0) [0|65535] "mV" Vector__XXX
 SG_ CELL_VOL_ID_233 : 128|16@1+ (1,0) [0|65535] "mV" Vector__XXX
 SG_ CELL_VOL_ID_232 : 112|16@1+ (1,0) [0|65535] "mV" Vector__XXX
 SG_ CELL_VOL_ID_231 : 96|16@1+ (1,0) [0|65535] "mV" Vector__XXX
 SG_ CELL_VOL_ID_230 : 80|16@1+ (1,0) [0|65535] "mV" Vector__XXX
 SG_ CELL_VOL_ID_229 : 64|16@1+ (1,0) [0|65535] "mV" Vector__XXX
 SG_ CELL_VOL_ID_228 : 48|16@1+ (1,0) [0|65535] "mV" Vector__XXX
 SG_ CELL_VOL_ID_227 : 32|16@1+ (1,0) [0|65535] "mV" Vector__XXX
 SG_ CELL_VOL_ID_226 : 16|16@1+ (1,0) [0|65535] "mV" Vector__XXX
 SG_ CELL_VOL_ID_225 : 0|16@1+ (1,0) [0|65535] "mV" Vector__XXX

BO_ 2460479392 BCU12A7EFA0: 64 BCU
 SG_ CELL_VOL_ID_224 : 496|16@1+ (1,0) [0|65535] "mV" Vector__XXX
 SG_ CELL_VOL_ID_223 : 480|16@1+ (1,0) [0|65535] "mV" Vector__XXX
 SG_ CELL_VOL_ID_222 : 464|16@1+ (1,0) [0|65535] "mV" Vector__XXX
 SG_ CELL_VOL_ID_221 : 448|16@1+ (1,0) [0|65535] "mV" Vector__XXX
 SG_ CELL_VOL_ID_220 : 432|16@1+ (1,0) [0|65535] "mV" Vector__XXX
 SG_ CELL_VOL_ID_219 : 416|16@1+ (1,0) [0|65535] "mV" Vector__XXX
 SG_ CELL_VOL_ID_218 : 400|16@1+ (1,0) [0|65535] "mV" Vector__XXX
 SG_ CELL_VOL_ID_217 : 384|16@1+ (1,0) [0|65535] "mV" Vector__XXX
 SG_ CELL_VOL_ID_216 : 368|16@1+ (1,0) [0|65535] "mV" Vector__XXX
 SG_ CELL_VOL_ID_215 : 352|16@1+ (1,0) [0|65535] "mV" Vector__XXX
 SG_ CELL_VOL_ID_214 : 336|16@1+ (1,0) [0|65535] "mV" Vector__XXX
 SG_ CELL_VOL_ID_213 : 320|16@1+ (1,0) [0|65535] "mV" Vector__XXX
 SG_ CELL_VOL_ID_212 : 304|16@1+ (1,0) [0|65535] "mV" Vector__XXX
 SG_ CELL_VOL_ID_211 : 288|16@1+ (1,0) [0|65535] "mV" Vector__XXX
 SG_ CELL_VOL_ID_210 : 272|16@1+ (1,0) [0|65535] "mV" Vector__XXX
 SG_ CELL_VOL_ID_209 : 256|16@1+ (1,0) [0|65535] "mV" Vector__XXX
 SG_ CELL_VOL_ID_208 : 240|16@1+ (1,0) [0|65535] "mV" Vector__XXX
 SG_ CELL_VOL_ID_207 : 224|16@1+ (1,0) [0|65535] "mV" Vector__XXX
 SG_ CELL_VOL_ID_206 : 208|16@1+ (1,0) [0|65535] "mV" Vector__XXX
 SG_ CELL_VOL_ID_205 : 192|16@1+ (1,0) [0|65535] "mV" Vector__XXX
 SG_ CELL_VOL_ID_204 : 176|16@1+ (1,0) [0|65535] "mV" Vector__XXX
 SG_ CELL_VOL_ID_203 : 160|16@1+ (1,0) [0|65535] "mV" Vector__XXX
 SG_ CELL_VOL_ID_202 : 144|16@1+ (1,0) [0|65535] "mV" Vector__XXX
 SG_ CELL_VOL_ID_201 : 128|16@1+ (1,0) [0|65535] "mV" Vector__XXX
 SG_ CELL_VOL_ID_200 : 112|16@1+ (1,0) [0|65535] "mV" Vector__XXX
 SG_ CELL_VOL_ID_199 : 96|16@1+ (1,0) [0|65535] "mV" Vector__XXX
 SG_ CELL_VOL_ID_198 : 80|16@1+ (1,0) [0|65535] "mV" Vector__XXX
 SG_ CELL_VOL_ID_197 : 64|16@1+ (1,0) [0|65535] "mV" Vector__XXX
 SG_ CELL_VOL_ID_196 : 48|16@1+ (1,0) [0|65535] "mV" Vector__XXX
 SG_ CELL_VOL_ID_195 : 32|16@1+ (1,0) [0|65535] "mV" Vector__XXX
 SG_ CELL_VOL_ID_194 : 16|16@1+ (1,0) [0|65535] "mV" Vector__XXX
 SG_ CELL_VOL_ID_193 : 0|16@1+ (1,0) [0|65535] "mV" Vector__XXX

BO_ 2460413856 BCU12A6EFA0: 64 BCU
 SG_ CELL_VOL_ID_192 : 496|16@1+ (1,0) [0|65535] "mV" Vector__XXX
 SG_ CELL_VOL_ID_191 : 480|16@1+ (1,0) [0|65535] "mV" Vector__XXX
 SG_ CELL_VOL_ID_190 : 464|16@1+ (1,0) [0|65535] "mV" Vector__XXX
 SG_ CELL_VOL_ID_189 : 448|16@1+ (1,0) [0|65535] "mV" Vector__XXX
 SG_ CELL_VOL_ID_188 : 432|16@1+ (1,0) [0|65535] "mV" Vector__XXX
 SG_ CELL_VOL_ID_187 : 416|16@1+ (1,0) [0|65535] "mV" Vector__XXX
 SG_ CELL_VOL_ID_186 : 400|16@1+ (1,0) [0|65535] "mV" Vector__XXX
 SG_ CELL_VOL_ID_185 : 384|16@1+ (1,0) [0|65535] "mV" Vector__XXX
 SG_ CELL_VOL_ID_184 : 368|16@1+ (1,0) [0|65535] "mV" Vector__XXX
 SG_ CELL_VOL_ID_183 : 352|16@1+ (1,0) [0|65535] "mV" Vector__XXX
 SG_ CELL_VOL_ID_182 : 336|16@1+ (1,0) [0|65535] "mV" Vector__XXX
 SG_ CELL_VOL_ID_181 : 320|16@1+ (1,0) [0|65535] "mV" Vector__XXX
 SG_ CELL_VOL_ID_180 : 304|16@1+ (1,0) [0|65535] "mV" Vector__XXX
 SG_ CELL_VOL_ID_179 : 288|16@1+ (1,0) [0|65535] "mV" Vector__XXX
 SG_ CELL_VOL_ID_178 : 272|16@1+ (1,0) [0|65535] "mV" Vector__XXX
 SG_ CELL_VOL_ID_177 : 256|16@1+ (1,0) [0|65535] "mV" Vector__XXX
 SG_ CELL_VOL_ID_176 : 240|16@1+ (1,0) [0|65535] "mV" Vector__XXX
 SG_ CELL_VOL_ID_175 : 224|16@1+ (1,0) [0|65535] "mV" Vector__XXX
 SG_ CELL_VOL_ID_174 : 208|16@1+ (1,0) [0|65535] "mV" Vector__XXX
 SG_ CELL_VOL_ID_173 : 192|16@1+ (1,0) [0|65535] "mV" Vector__XXX
 SG_ CELL_VOL_ID_172 : 176|16@1+ (1,0) [0|65535] "mV" Vector__XXX
 SG_ CELL_VOL_ID_171 : 160|16@1+ (1,0) [0|65535] "mV" Vector__XXX
 SG_ CELL_VOL_ID_170 : 144|16@1+ (1,0) [0|65535] "mV" Vector__XXX
 SG_ CELL_VOL_ID_169 : 128|16@1+ (1,0) [0|65535] "mV" Vector__XXX
 SG_ CELL_VOL_ID_168 : 112|16@1+ (1,0) [0|65535] "mV" Vector__XXX
 SG_ CELL_VOL_ID_167 : 96|16@1+ (1,0) [0|65535] "mV" Vector__XXX
 SG_ CELL_VOL_ID_166 : 80|16@1+ (1,0) [0|65535] "mV" Vector__XXX
 SG_ CELL_VOL_ID_165 : 64|16@1+ (1,0) [0|65535] "mV" Vector__XXX
 SG_ CELL_VOL_ID_164 : 48|16@1+ (1,0) [0|65535] "mV" Vector__XXX
 SG_ CELL_VOL_ID_163 : 32|16@1+ (1,0) [0|65535] "mV" Vector__XXX
 SG_ CELL_VOL_ID_162 : 16|16@1+ (1,0) [0|65535] "mV" Vector__XXX
 SG_ CELL_VOL_ID_161 : 0|16@1+ (1,0) [0|65535] "mV" Vector__XXX

BO_ 2460348320 BCU12A5EFA0: 64 BCU
 SG_ CELL_VOL_ID_160 : 496|16@1+ (1,0) [0|65535] "mV" Vector__XXX
 SG_ CELL_VOL_ID_159 : 480|16@1+ (1,0) [0|65535] "mV" Vector__XXX
 SG_ CELL_VOL_ID_158 : 464|16@1+ (1,0) [0|65535] "mV" Vector__XXX
 SG_ CELL_VOL_ID_157 : 448|16@1+ (1,0) [0|65535] "mV" Vector__XXX
 SG_ CELL_VOL_ID_156 : 432|16@1+ (1,0) [0|65535] "mV" Vector__XXX
 SG_ CELL_VOL_ID_155 : 416|16@1+ (1,0) [0|65535] "mV" Vector__XXX
 SG_ CELL_VOL_ID_154 : 400|16@1+ (1,0) [0|65535] "mV" Vector__XXX
 SG_ CELL_VOL_ID_153 : 384|16@1+ (1,0) [0|65535] "mV" Vector__XXX
 SG_ CELL_VOL_ID_152 : 368|16@1+ (1,0) [0|65535] "mV" Vector__XXX
 SG_ CELL_VOL_ID_151 : 352|16@1+ (1,0) [0|65535] "mV" Vector__XXX
 SG_ CELL_VOL_ID_150 : 336|16@1+ (1,0) [0|65535] "mV" Vector__XXX
 SG_ CELL_VOL_ID_149 : 320|16@1+ (1,0) [0|65535] "mV" Vector__XXX
 SG_ CELL_VOL_ID_148 : 304|16@1+ (1,0) [0|65535] "mV" Vector__XXX
 SG_ CELL_VOL_ID_147 : 288|16@1+ (1,0) [0|65535] "mV" Vector__XXX
 SG_ CELL_VOL_ID_146 : 272|16@1+ (1,0) [0|65535] "mV" Vector__XXX
 SG_ CELL_VOL_ID_145 : 256|16@1+ (1,0) [0|65535] "mV" Vector__XXX
 SG_ CELL_VOL_ID_144 : 240|16@1+ (1,0) [0|65535] "mV" Vector__XXX
 SG_ CELL_VOL_ID_143 : 224|16@1+ (1,0) [0|65535] "mV" Vector__XXX
 SG_ CELL_VOL_ID_142 : 208|16@1+ (1,0) [0|65535] "mV" Vector__XXX
 SG_ CELL_VOL_ID_141 : 192|16@1+ (1,0) [0|65535] "mV" Vector__XXX
 SG_ CELL_VOL_ID_140 : 176|16@1+ (1,0) [0|65535] "mV" Vector__XXX
 SG_ CELL_VOL_ID_139 : 160|16@1+ (1,0) [0|65535] "mV" Vector__XXX
 SG_ CELL_VOL_ID_138 : 144|16@1+ (1,0) [0|65535] "mV" Vector__XXX
 SG_ CELL_VOL_ID_137 : 128|16@1+ (1,0) [0|65535] "mV" Vector__XXX
 SG_ CELL_VOL_ID_136 : 112|16@1+ (1,0) [0|65535] "mV" Vector__XXX
 SG_ CELL_VOL_ID_135 : 96|16@1+ (1,0) [0|65535] "mV" Vector__XXX
 SG_ CELL_VOL_ID_134 : 80|16@1+ (1,0) [0|65535] "mV" Vector__XXX
 SG_ CELL_VOL_ID_133 : 64|16@1+ (1,0) [0|65535] "mV" Vector__XXX
 SG_ CELL_VOL_ID_132 : 48|16@1+ (1,0) [0|65535] "mV" Vector__XXX
 SG_ CELL_VOL_ID_131 : 32|16@1+ (1,0) [0|65535] "mV" Vector__XXX
 SG_ CELL_VOL_ID_130 : 16|16@1+ (1,0) [0|65535] "mV" Vector__XXX
 SG_ CELL_VOL_ID_129 : 0|16@1+ (1,0) [0|65535] "mV" Vector__XXX

BO_ 2460282784 BCU12A4EFA0: 64 BCU
 SG_ CELL_VOL_ID_128 : 496|16@1+ (1,0) [0|65535] "mV" Vector__XXX
 SG_ CELL_VOL_ID_127 : 480|16@1+ (1,0) [0|65535] "mV" Vector__XXX
 SG_ CELL_VOL_ID_126 : 464|16@1+ (1,0) [0|65535] "mV" Vector__XXX
 SG_ CELL_VOL_ID_125 : 448|16@1+ (1,0) [0|65535] "mV" Vector__XXX
 SG_ CELL_VOL_ID_124 : 432|16@1+ (1,0) [0|65535] "mV" Vector__XXX
 SG_ CELL_VOL_ID_123 : 416|16@1+ (1,0) [0|65535] "mV" Vector__XXX
 SG_ CELL_VOL_ID_122 : 400|16@1+ (1,0) [0|65535] "mV" Vector__XXX
 SG_ CELL_VOL_ID_121 : 384|16@1+ (1,0) [0|65535] "mV" Vector__XXX
 SG_ CELL_VOL_ID_120 : 368|16@1+ (1,0) [0|65535] "mV" Vector__XXX
 SG_ CELL_VOL_ID_119 : 352|16@1+ (1,0) [0|65535] "mV" Vector__XXX
 SG_ CELL_VOL_ID_118 : 336|16@1+ (1,0) [0|65535] "mV" Vector__XXX
 SG_ CELL_VOL_ID_117 : 320|16@1+ (1,0) [0|65535] "mV" Vector__XXX
 SG_ CELL_VOL_ID_116 : 304|16@1+ (1,0) [0|65535] "mV" Vector__XXX
 SG_ CELL_VOL_ID_115 : 288|16@1+ (1,0) [0|65535] "mV" Vector__XXX
 SG_ CELL_VOL_ID_114 : 272|16@1+ (1,0) [0|65535] "mV" Vector__XXX
 SG_ CELL_VOL_ID_113 : 256|16@1+ (1,0) [0|65535] "mV" Vector__XXX
 SG_ CELL_VOL_ID_112 : 240|16@1+ (1,0) [0|65535] "mV" Vector__XXX
 SG_ CELL_VOL_ID_111 : 224|16@1+ (1,0) [0|65535] "mV" Vector__XXX
 SG_ CELL_VOL_ID_110 : 208|16@1+ (1,0) [0|65535] "mV" Vector__XXX
 SG_ CELL_VOL_ID_109 : 192|16@1+ (1,0) [0|65535] "mV" Vector__XXX
 SG_ CELL_VOL_ID_108 : 176|16@1+ (1,0) [0|65535] "mV" Vector__XXX
 SG_ CELL_VOL_ID_107 : 160|16@1+ (1,0) [0|65535] "mV" Vector__XXX
 SG_ CELL_VOL_ID_106 : 144|16@1+ (1,0) [0|65535] "mV" Vector__XXX
 SG_ CELL_VOL_ID_105 : 128|16@1+ (1,0) [0|65535] "mV" Vector__XXX
 SG_ CELL_VOL_ID_104 : 112|16@1+ (1,0) [0|65535] "mV" Vector__XXX
 SG_ CELL_VOL_ID_103 : 96|16@1+ (1,0) [0|65535] "mV" Vector__XXX
 SG_ CELL_VOL_ID_102 : 80|16@1+ (1,0) [0|65535] "mV" Vector__XXX
 SG_ CELL_VOL_ID_101 : 64|16@1+ (1,0) [0|65535] "mV" Vector__XXX
 SG_ CELL_VOL_ID_100 : 48|16@1+ (1,0) [0|65535] "mV" Vector__XXX
 SG_ CELL_VOL_ID_099 : 32|16@1+ (1,0) [0|65535] "mV" Vector__XXX
 SG_ CELL_VOL_ID_098 : 16|16@1+ (1,0) [0|65535] "mV" Vector__XXX
 SG_ CELL_VOL_ID_097 : 0|16@1+ (1,0) [0|65535] "mV" Vector__XXX

BO_ 2460217248 BCU12A3EFA0: 64 BCU
 SG_ CELL_VOL_ID_096 : 496|16@1+ (1,0) [0|65535] "mV" Vector__XXX
 SG_ CELL_VOL_ID_095 : 480|16@1+ (1,0) [0|65535] "mV" Vector__XXX
 SG_ CELL_VOL_ID_094 : 464|16@1+ (1,0) [0|65535] "mV" Vector__XXX
 SG_ CELL_VOL_ID_093 : 448|16@1+ (1,0) [0|65535] "mV" Vector__XXX
 SG_ CELL_VOL_ID_092 : 432|16@1+ (1,0) [0|65535] "mV" Vector__XXX
 SG_ CELL_VOL_ID_091 : 416|16@1+ (1,0) [0|65535] "mV" Vector__XXX
 SG_ CELL_VOL_ID_090 : 400|16@1+ (1,0) [0|65535] "mV" Vector__XXX
 SG_ CELL_VOL_ID_089 : 384|16@1+ (1,0) [0|65535] "mV" Vector__XXX
 SG_ CELL_VOL_ID_088 : 368|16@1+ (1,0) [0|65535] "mV" Vector__XXX
 SG_ CELL_VOL_ID_087 : 352|16@1+ (1,0) [0|65535] "mV" Vector__XXX
 SG_ CELL_VOL_ID_086 : 336|16@1+ (1,0) [0|65535] "mV" Vector__XXX
 SG_ CELL_VOL_ID_085 : 320|16@1+ (1,0) [0|65535] "mV" Vector__XXX
 SG_ CELL_VOL_ID_084 : 304|16@1+ (1,0) [0|65535] "mV" Vector__XXX
 SG_ CELL_VOL_ID_083 : 288|16@1+ (1,0) [0|65535] "mV" Vector__XXX
 SG_ CELL_VOL_ID_082 : 272|16@1+ (1,0) [0|65535] "mV" Vector__XXX
 SG_ CELL_VOL_ID_081 : 256|16@1+ (1,0) [0|65535] "mV" Vector__XXX
 SG_ CELL_VOL_ID_080 : 240|16@1+ (1,0) [0|65535] "mV" Vector__XXX
 SG_ CELL_VOL_ID_079 : 224|16@1+ (1,0) [0|65535] "mV" Vector__XXX
 SG_ CELL_VOL_ID_078 : 208|16@1+ (1,0) [0|65535] "mV" Vector__XXX
 SG_ CELL_VOL_ID_077 : 192|16@1+ (1,0) [0|65535] "mV" Vector__XXX
 SG_ CELL_VOL_ID_076 : 176|16@1+ (1,0) [0|65535] "mV" Vector__XXX
 SG_ CELL_VOL_ID_075 : 160|16@1+ (1,0) [0|65535] "mV" Vector__XXX
 SG_ CELL_VOL_ID_074 : 144|16@1+ (1,0) [0|65535] "mV" Vector__XXX
 SG_ CELL_VOL_ID_073 : 128|16@1+ (1,0) [0|65535] "mV" Vector__XXX
 SG_ CELL_VOL_ID_072 : 112|16@1+ (1,0) [0|65535] "mV" Vector__XXX
 SG_ CELL_VOL_ID_071 : 96|16@1+ (1,0) [0|65535] "mV" Vector__XXX
 SG_ CELL_VOL_ID_070 : 80|16@1+ (1,0) [0|65535] "mV" Vector__XXX
 SG_ CELL_VOL_ID_069 : 64|16@1+ (1,0) [0|65535] "mV" Vector__XXX
 SG_ CELL_VOL_ID_068 : 48|16@1+ (1,0) [0|65535] "mV" Vector__XXX
 SG_ CELL_VOL_ID_067 : 32|16@1+ (1,0) [0|65535] "mV" Vector__XXX
 SG_ CELL_VOL_ID_066 : 16|16@1+ (1,0) [0|65535] "mV" Vector__XXX
 SG_ CELL_VOL_ID_065 : 0|16@1+ (1,0) [0|65535] "mV" Vector__XXX

BO_ 2460151712 BCU12A2EFA0: 64 BCU
 SG_ CELL_VOL_ID_044 : 176|16@1+ (1,0) [0|65535] "mV" Vector__XXX
 SG_ CELL_VOL_ID_064 : 496|16@1+ (1,0) [0|65535] "mV" Vector__XXX
 SG_ CELL_VOL_ID_063 : 480|16@1+ (1,0) [0|65535] "mV" Vector__XXX
 SG_ CELL_VOL_ID_062 : 464|16@1+ (1,0) [0|65535] "mV" Vector__XXX
 SG_ CELL_VOL_ID_061 : 448|16@1+ (1,0) [0|65535] "mV" Vector__XXX
 SG_ CELL_VOL_ID_060 : 432|16@1+ (1,0) [0|65535] "mV" Vector__XXX
 SG_ CELL_VOL_ID_059 : 416|16@1+ (1,0) [0|65535] "mV" Vector__XXX
 SG_ CELL_VOL_ID_058 : 400|16@1+ (1,0) [0|65535] "mV" Vector__XXX
 SG_ CELL_VOL_ID_057 : 384|16@1+ (1,0) [0|65535] "mV" Vector__XXX
 SG_ CELL_VOL_ID_056 : 368|16@1+ (1,0) [0|65535] "mV" Vector__XXX
 SG_ CELL_VOL_ID_055 : 352|16@1+ (1,0) [0|65535] "mV" Vector__XXX
 SG_ CELL_VOL_ID_054 : 336|16@1+ (1,0) [0|65535] "mV" Vector__XXX
 SG_ CELL_VOL_ID_053 : 320|16@1+ (1,0) [0|65535] "mV" Vector__XXX
 SG_ CELL_VOL_ID_052 : 304|16@1+ (1,0) [0|65535] "mV" Vector__XXX
 SG_ CELL_VOL_ID_051 : 288|16@1+ (1,0) [0|65535] "mV" Vector__XXX
 SG_ CELL_VOL_ID_050 : 272|16@1+ (1,0) [0|65535] "mV" Vector__XXX
 SG_ CELL_VOL_ID_049 : 256|16@1+ (1,0) [0|65535] "mV" Vector__XXX
 SG_ CELL_VOL_ID_048 : 240|16@1+ (1,0) [0|65535] "mV" Vector__XXX
 SG_ CELL_VOL_ID_047 : 224|16@1+ (1,0) [0|65535] "mV" Vector__XXX
 SG_ CELL_VOL_ID_046 : 208|16@1+ (1,0) [0|65535] "mV" Vector__XXX
 SG_ CELL_VOL_ID_045 : 192|16@1+ (1,0) [0|65535] "mV" Vector__XXX
 SG_ CELL_VOL_ID_043 : 160|16@1+ (1,0) [0|65535] "mV" Vector__XXX
 SG_ CELL_VOL_ID_042 : 144|16@1+ (1,0) [0|65535] "mV" Vector__XXX
 SG_ CELL_VOL_ID_041 : 128|16@1+ (1,0) [0|65535] "mV" Vector__XXX
 SG_ CELL_VOL_ID_040 : 112|16@1+ (1,0) [0|65535] "mV" Vector__XXX
 SG_ CELL_VOL_ID_039 : 96|16@1+ (1,0) [0|65535] "mV" Vector__XXX
 SG_ CELL_VOL_ID_038 : 80|16@1+ (1,0) [0|65535] "mV" Vector__XXX
 SG_ CELL_VOL_ID_037 : 64|16@1+ (1,0) [0|65535] "mV" Vector__XXX
 SG_ CELL_VOL_ID_036 : 48|16@1+ (1,0) [0|65535] "mV" Vector__XXX
 SG_ CELL_VOL_ID_035 : 32|16@1+ (1,0) [0|65535] "mV" Vector__XXX
 SG_ CELL_VOL_ID_034 : 16|16@1+ (1,0) [0|65535] "mV" Vector__XXX
 SG_ CELL_VOL_ID_033 : 0|16@1+ (1,0) [0|65535] "mV" Vector__XXX

BO_ 2460086176 BCU12A1EFA0: 64 BCU
 SG_ CELL_VOL_ID_001 : 0|16@1+ (1,0) [0|65535] "mV" Vector__XXX
 SG_ CELL_VOL_ID_002 : 16|16@1+ (1,0) [0|65535] "mV" Vector__XXX
 SG_ CELL_VOL_ID_003 : 32|16@1+ (1,0) [0|65535] "mV" Vector__XXX
 SG_ CELL_VOL_ID_004 : 48|16@1+ (1,0) [0|65535] "mV" Vector__XXX
 SG_ CELL_VOL_ID_005 : 64|16@1+ (1,0) [0|65535] "mV" Vector__XXX
 SG_ CELL_VOL_ID_006 : 80|16@1+ (1,0) [0|65535] "mV" Vector__XXX
 SG_ CELL_VOL_ID_007 : 96|16@1+ (1,0) [0|65535] "mV" Vector__XXX
 SG_ CELL_VOL_ID_008 : 112|16@1+ (1,0) [0|65535] "mV" Vector__XXX
 SG_ CELL_VOL_ID_009 : 128|16@1+ (1,0) [0|65535] "mV" Vector__XXX
 SG_ CELL_VOL_ID_010 : 144|16@1+ (1,0) [0|65535] "mV" Vector__XXX
 SG_ CELL_VOL_ID_011 : 160|16@1+ (1,0) [0|65535] "mV" Vector__XXX
 SG_ CELL_VOL_ID_012 : 176|16@1+ (1,0) [0|65535] "mV" Vector__XXX
 SG_ CELL_VOL_ID_013 : 192|16@1+ (1,0) [0|65535] "mV" Vector__XXX
 SG_ CELL_VOL_ID_014 : 208|16@1+ (1,0) [0|65535] "mV" Vector__XXX
 SG_ CELL_VOL_ID_015 : 224|16@1+ (1,0) [0|65535] "mV" Vector__XXX
 SG_ CELL_VOL_ID_016 : 240|16@1+ (1,0) [0|65535] "mV" Vector__XXX
 SG_ CELL_VOL_ID_017 : 256|16@1+ (1,0) [0|65535] "mV" Vector__XXX
 SG_ CELL_VOL_ID_018 : 272|16@1+ (1,0) [0|65535] "mV" Vector__XXX
 SG_ CELL_VOL_ID_019 : 288|16@1+ (1,0) [0|65535] "mV" Vector__XXX
 SG_ CELL_VOL_ID_020 : 304|16@1+ (1,0) [0|65535] "mV" Vector__XXX
 SG_ CELL_VOL_ID_021 : 320|16@1+ (1,0) [0|65535] "mV" Vector__XXX
 SG_ CELL_VOL_ID_022 : 336|16@1+ (1,0) [0|65535] "mV" Vector__XXX
 SG_ CELL_VOL_ID_023 : 352|16@1+ (1,0) [0|65535] "mV" Vector__XXX
 SG_ CELL_VOL_ID_024 : 368|16@1+ (1,0) [0|65535] "mV" Vector__XXX
 SG_ CELL_VOL_ID_025 : 384|16@1+ (1,0) [0|65535] "mV" Vector__XXX
 SG_ CELL_VOL_ID_026 : 400|16@1+ (1,0) [0|65535] "mV" Vector__XXX
 SG_ CELL_VOL_ID_027 : 416|16@1+ (1,0) [0|65535] "mV" Vector__XXX
 SG_ CELL_VOL_ID_028 : 432|16@1+ (1,0) [0|65535] "mV" Vector__XXX
 SG_ CELL_VOL_ID_029 : 448|16@1+ (1,0) [0|65535] "mV" Vector__XXX
 SG_ CELL_VOL_ID_030 : 464|16@1+ (1,0) [0|65535] "mV" Vector__XXX
 SG_ CELL_VOL_ID_031 : 480|16@1+ (1,0) [0|65535] "mV" Vector__XXX
 SG_ CELL_VOL_ID_032 : 496|16@1+ (1,0) [0|65535] "mV" Vector__XXX

BO_ 2449797024 BCU1204EFA0: 64 BCU
 SG_ ALARM_STATE_ID_128 : 508|4@1+ (1,0) [0|0] "NAN" Vector__XXX
 SG_ ALARM_STATE_ID_127 : 504|4@1+ (1,0) [0|0] "NAN" Vector__XXX
 SG_ ALARM_STATE_ID_126 : 500|4@1+ (1,0) [0|0] "NAN" Vector__XXX
 SG_ ALARM_STATE_ID_125 : 496|4@1+ (1,0) [0|0] "NAN" Vector__XXX
 SG_ ALARM_STATE_ID_124 : 492|4@1+ (1,0) [0|0] "NAN" Vector__XXX
 SG_ ALARM_STATE_ID_123 : 488|4@1+ (1,0) [0|0] "NAN" Vector__XXX
 SG_ ALARM_STATE_ID_122 : 484|4@1+ (1,0) [0|0] "NAN" Vector__XXX
 SG_ ALARM_STATE_ID_121 : 480|4@1+ (1,0) [0|0] "NAN" Vector__XXX
 SG_ ALARM_STATE_ID_120 : 476|4@1+ (1,0) [0|0] "NAN" Vector__XXX
 SG_ ALARM_STATE_ID_119 : 472|4@1+ (1,0) [0|0] "NAN" Vector__XXX
 SG_ ALARM_STATE_ID_118 : 468|4@1+ (1,0) [0|0] "NAN" Vector__XXX
 SG_ ALARM_STATE_ID_117 : 464|4@1+ (1,0) [0|0] "NAN" Vector__XXX
 SG_ ALARM_STATE_ID_116 : 460|4@1+ (1,0) [0|0] "NAN" Vector__XXX
 SG_ ALARM_STATE_ID_115 : 456|4@1+ (1,0) [0|0] "NAN" Vector__XXX
 SG_ ALARM_STATE_ID_114 : 452|4@1+ (1,0) [0|0] "NAN" Vector__XXX
 SG_ ALARM_STATE_ID_113 : 448|4@1+ (1,0) [0|0] "NAN" Vector__XXX
 SG_ ALARM_STATE_ID_112 : 444|4@1+ (1,0) [0|0] "NAN" Vector__XXX
 SG_ ALARM_STATE_ID_111 : 440|4@1+ (1,0) [0|0] "NAN" Vector__XXX
 SG_ ALARM_STATE_ID_110 : 436|4@1+ (1,0) [0|0] "NAN" Vector__XXX
 SG_ ALARM_STATE_ID_109 : 432|4@1+ (1,0) [0|0] "NAN" Vector__XXX
 SG_ ALARM_STATE_ID_108 : 428|4@1+ (1,0) [0|0] "NAN" Vector__XXX
 SG_ ALARM_STATE_ID_107 : 424|4@1+ (1,0) [0|0] "NAN" Vector__XXX
 SG_ ALARM_STATE_ID_106 : 420|4@1+ (1,0) [0|0] "NAN" Vector__XXX
 SG_ ALARM_STATE_ID_105 : 416|4@1+ (1,0) [0|0] "NAN" Vector__XXX
 SG_ ALARM_STATE_ID_104 : 412|4@1+ (1,0) [0|0] "NAN" Vector__XXX
 SG_ ALARM_STATE_ID_103 : 408|4@1+ (1,0) [0|0] "NAN" Vector__XXX
 SG_ ALARM_STATE_ID_102 : 404|4@1+ (1,0) [0|0] "NAN" Vector__XXX
 SG_ ALARM_STATE_ID_101 : 400|4@1+ (1,0) [0|0] "NAN" Vector__XXX
 SG_ ALARM_STATE_ID_100 : 396|4@1+ (1,0) [0|0] "NAN" Vector__XXX
 SG_ ALARM_STATE_ID_099 : 392|4@1+ (1,0) [0|0] "NAN" Vector__XXX
 SG_ ALARM_STATE_ID_098 : 388|4@1+ (1,0) [0|0] "NAN" Vector__XXX
 SG_ ALARM_STATE_ID_097 : 384|4@1+ (1,0) [0|0] "NAN" Vector__XXX
 SG_ ALARM_STATE_ID_096 : 380|4@1+ (1,0) [0|0] "NAN" Vector__XXX
 SG_ ALARM_STATE_ID_095 : 376|4@1+ (1,0) [0|0] "NAN" Vector__XXX
 SG_ ALARM_STATE_ID_094 : 372|4@1+ (1,0) [0|0] "NAN" Vector__XXX
 SG_ ALARM_STATE_ID_093 : 368|4@1+ (1,0) [0|0] "NAN" Vector__XXX
 SG_ ALARM_STATE_ID_092 : 364|4@1+ (1,0) [0|0] "NAN" Vector__XXX
 SG_ ALARM_STATE_ID_091 : 360|4@1+ (1,0) [0|0] "NAN" Vector__XXX
 SG_ ALARM_STATE_ID_090 : 356|4@1+ (1,0) [0|0] "NAN" Vector__XXX
 SG_ ALARM_STATE_ID_089 : 352|4@1+ (1,0) [0|0] "NAN" Vector__XXX
 SG_ ALARM_STATE_ID_088 : 348|4@1+ (1,0) [0|0] "NAN" Vector__XXX
 SG_ ALARM_STATE_ID_087 : 344|4@1+ (1,0) [0|0] "NAN" Vector__XXX
 SG_ ALARM_STATE_ID_086 : 340|4@1+ (1,0) [0|0] "NAN" Vector__XXX
 SG_ ALARM_STATE_ID_085 : 336|4@1+ (1,0) [0|0] "NAN" Vector__XXX
 SG_ ALARM_STATE_ID_084 : 332|4@1+ (1,0) [0|0] "NAN" Vector__XXX
 SG_ ALARM_STATE_ID_083 : 328|4@1+ (1,0) [0|0] "NAN" Vector__XXX
 SG_ ALARM_STATE_ID_082 : 324|4@1+ (1,0) [0|0] "NAN" Vector__XXX
 SG_ ALARM_STATE_ID_081 : 320|4@1+ (1,0) [0|0] "NAN" Vector__XXX
 SG_ ALARM_STATE_ID_080 : 316|4@1+ (1,0) [0|0] "NAN" Vector__XXX
 SG_ ALARM_STATE_ID_079 : 312|4@1+ (1,0) [0|0] "NAN" Vector__XXX
 SG_ ALARM_STATE_ID_078 : 308|4@1+ (1,0) [0|0] "NAN" Vector__XXX
 SG_ ALARM_STATE_ID_077 : 304|4@1+ (1,0) [0|0] "NAN" Vector__XXX
 SG_ ALARM_STATE_ID_076 : 300|4@1+ (1,0) [0|0] "NAN" Vector__XXX
 SG_ ALARM_STATE_ID_075 : 296|4@1+ (1,0) [0|0] "NAN" Vector__XXX
 SG_ ALARM_STATE_ID_074 : 292|4@1+ (1,0) [0|0] "NAN" Vector__XXX
 SG_ ALARM_STATE_ID_073 : 288|4@1+ (1,0) [0|0] "NAN" Vector__XXX
 SG_ ALARM_STATE_ID_072 : 284|4@1+ (1,0) [0|0] "NAN" Vector__XXX
 SG_ ALARM_STATE_ID_071 : 280|4@1+ (1,0) [0|0] "NAN" Vector__XXX
 SG_ ALARM_STATE_ID_070 : 276|4@1+ (1,0) [0|0] "NAN" Vector__XXX
 SG_ ALARM_STATE_ID_069 : 272|4@1+ (1,0) [0|0] "NAN" Vector__XXX
 SG_ ALARM_STATE_ID_068 : 268|4@1+ (1,0) [0|0] "NAN" Vector__XXX
 SG_ ALARM_STATE_ID_067 : 264|4@1+ (1,0) [0|0] "NAN" Vector__XXX
 SG_ ALARM_STATE_ID_066 : 260|4@1+ (1,0) [0|0] "NAN" Vector__XXX
 SG_ ALARM_STATE_ID_065 : 256|4@1+ (1,0) [0|0] "NAN" Vector__XXX
 SG_ ALARM_STATE_ID_064 : 252|4@1+ (1,0) [0|0] "NAN" Vector__XXX
 SG_ ALARM_STATE_ID_063 : 248|4@1+ (1,0) [0|0] "NAN" Vector__XXX
 SG_ ALARM_STATE_ID_062 : 244|4@1+ (1,0) [0|0] "NAN" Vector__XXX
 SG_ ALARM_STATE_ID_061 : 240|4@1+ (1,0) [0|0] "NAN" Vector__XXX
 SG_ ALARM_STATE_ID_060 : 236|4@1+ (1,0) [0|0] "NAN" Vector__XXX
 SG_ ALARM_STATE_ID_059 : 232|4@1+ (1,0) [0|0] "NAN" Vector__XXX
 SG_ ALARM_STATE_ID_058 : 228|4@1+ (1,0) [0|0] "NAN" Vector__XXX
 SG_ ALARM_STATE_ID_057 : 224|4@1+ (1,0) [0|0] "NAN" Vector__XXX
 SG_ ALARM_STATE_ID_056 : 220|4@1+ (1,0) [0|0] "NAN" Vector__XXX
 SG_ ALARM_STATE_ID_055 : 216|4@1+ (1,0) [0|0] "NAN" Vector__XXX
 SG_ ALARM_STATE_ID_054 : 212|4@1+ (1,0) [0|0] "NAN" Vector__XXX
 SG_ ALARM_STATE_ID_053 : 208|4@1+ (1,0) [0|0] "NAN" Vector__XXX
 SG_ ALARM_STATE_ID_052 : 204|4@1+ (1,0) [0|0] "NAN" Vector__XXX
 SG_ ALARM_STATE_ID_051 : 200|4@1+ (1,0) [0|0] "NAN" Vector__XXX
 SG_ ALARM_STATE_ID_050 : 196|4@1+ (1,0) [0|0] "NAN" Vector__XXX
 SG_ ALARM_STATE_ID_049 : 192|4@1+ (1,0) [0|0] "NAN" Vector__XXX
 SG_ ALARM_STATE_ID_048 : 188|4@1+ (1,0) [0|0] "NAN" Vector__XXX
 SG_ ALARM_STATE_ID_047 : 184|4@1+ (1,0) [0|0] "NAN" Vector__XXX
 SG_ ALARM_STATE_ID_046 : 180|4@1+ (1,0) [0|0] "NAN" Vector__XXX
 SG_ ALARM_STATE_ID_045 : 176|4@1+ (1,0) [0|0] "NAN" Vector__XXX
 SG_ ALARM_STATE_ID_044 : 172|4@1+ (1,0) [0|0] "NAN" Vector__XXX
 SG_ ALARM_STATE_ID_043 : 168|4@1+ (1,0) [0|0] "NAN" Vector__XXX
 SG_ ALARM_STATE_ID_042 : 164|4@1+ (1,0) [0|0] "NAN" Vector__XXX
 SG_ ALARM_STATE_ID_041 : 160|4@1+ (1,0) [0|0] "NAN" Vector__XXX
 SG_ ALARM_STATE_ID_040 : 156|4@1+ (1,0) [0|0] "NAN" Vector__XXX
 SG_ ALARM_STATE_ID_039 : 152|4@1+ (1,0) [0|0] "NAN" Vector__XXX
 SG_ ALARM_STATE_ID_038 : 148|4@1+ (1,0) [0|0] "NAN" Vector__XXX
 SG_ ALARM_STATE_ID_037 : 144|4@1+ (1,0) [0|0] "NAN" Vector__XXX
 SG_ ALARM_STATE_ID_036 : 140|4@1+ (1,0) [0|0] "NAN" Vector__XXX
 SG_ ALARM_STATE_ID_035 : 136|4@1+ (1,0) [0|0] "NAN" Vector__XXX
 SG_ ALARM_STATE_ID_034 : 132|4@1+ (1,0) [0|0] "NAN" Vector__XXX
 SG_ ALARM_STATE_ID_033 : 128|4@1+ (1,0) [0|0] "NAN" Vector__XXX
 SG_ ALARM_STATE_ID_032 : 124|4@1+ (1,0) [0|0] "NAN" Vector__XXX
 SG_ ALARM_STATE_ID_031 : 120|4@1+ (1,0) [0|0] "NAN" Vector__XXX
 SG_ ALARM_STATE_ID_030 : 116|4@1+ (1,0) [0|0] "NAN" Vector__XXX
 SG_ ALARM_STATE_ID_029 : 112|4@1+ (1,0) [0|0] "NAN" Vector__XXX
 SG_ ALARM_STATE_ID_028 : 108|4@1+ (1,0) [0|0] "NAN" Vector__XXX
 SG_ ALARM_STATE_ID_027 : 104|4@1+ (1,0) [0|0] "NAN" Vector__XXX
 SG_ ALARM_STATE_ID_026 : 100|4@1+ (1,0) [0|0] "NAN" Vector__XXX
 SG_ ALARM_STATE_ID_025 : 96|4@1+ (1,0) [0|0] "NAN" Vector__XXX
 SG_ ALARM_STATE_ID_024 : 92|4@1+ (1,0) [0|0] "NAN" Vector__XXX
 SG_ ALARM_STATE_ID_023 : 88|4@1+ (1,0) [0|0] "NAN" Vector__XXX
 SG_ ALARM_STATE_ID_022 : 84|4@1+ (1,0) [0|0] "NAN" Vector__XXX
 SG_ ALARM_STATE_ID_021 : 80|4@1+ (1,0) [0|0] "NAN" Vector__XXX
 SG_ ALARM_STATE_ID_020 : 76|4@1+ (1,0) [0|0] "NAN" Vector__XXX
 SG_ ALARM_STATE_ID_019 : 72|4@1+ (1,0) [0|0] "NAN" Vector__XXX
 SG_ ALARM_STATE_ID_018 : 68|4@1+ (1,0) [0|0] "NAN" Vector__XXX
 SG_ ALARM_STATE_ID_017 : 64|4@1+ (1,0) [0|0] "NAN" Vector__XXX
 SG_ ALARM_STATE_ID_016 : 60|4@1+ (1,0) [0|0] "NAN" Vector__XXX
 SG_ ALARM_STATE_ID_015 : 56|4@1+ (1,0) [0|0] "NAN" Vector__XXX
 SG_ ALARM_STATE_ID_014 : 52|4@1+ (1,0) [0|0] "NAN" Vector__XXX
 SG_ ALARM_STATE_ID_013 : 48|4@1+ (1,0) [0|0] "NAN" Vector__XXX
 SG_ ALARM_STATE_ID_012 : 44|4@1+ (1,0) [0|0] "NAN" Vector__XXX
 SG_ ALARM_STATE_ID_011 : 40|4@1+ (1,0) [0|0] "NAN" Vector__XXX
 SG_ ALARM_STATE_ID_010 : 36|4@1+ (1,0) [0|0] "NAN" Vector__XXX
 SG_ ALARM_STATE_ID_009 : 32|4@1+ (1,0) [0|0] "NAN" Vector__XXX
 SG_ ALARM_STATE_ID_008 : 28|4@1+ (1,0) [0|0] "NAN" Vector__XXX
 SG_ ALARM_STATE_ID_007 : 24|4@1+ (1,0) [0|0] "NAN" Vector__XXX
 SG_ ALARM_STATE_ID_006 : 20|4@1+ (1,0) [0|0] "NAN" Vector__XXX
 SG_ ALARM_STATE_ID_005 : 16|4@1+ (1,0) [0|0] "NAN" Vector__XXX
 SG_ ALARM_STATE_ID_004 : 12|4@1+ (1,0) [0|0] "NAN" Vector__XXX
 SG_ ALARM_STATE_ID_003 : 8|4@1+ (1,0) [0|0] "NAN" Vector__XXX
 SG_ ALARM_STATE_ID_002 : 4|4@1+ (1,0) [0|0] "NAN" Vector__XXX
 SG_ ALARM_STATE_ID_001 : 0|4@1+ (1,0) [0|0] "NAN" Vector__XXX

BO_ 2449665952 BCU1202EFA0: 64 BCU
 SG_ BCU_TERMINAL_TEMP_MIN_POSI : 432|16@1+ (1,0) [0|65535] "N AN" Vector__XXX
 SG_ BCU_TERMINAL_TEMP_MIN : 416|16@1- (0.1,0) [-3276.8|3276.7] "℃" Vector__XXX
 SG_ VAR_SYS_ANALOG_PBUS_RES : 464|16@1+ (1,0) [0|65535] "KΩ" Vector__XXX
 SG_ VAR_SYS_ANALOG_NBUS_RES : 448|16@1+ (1,0) [0|65535] "KΩ" Vector__XXX
 SG_ TOTAL_DSCH_AH : 320|32@1+ (0.1,0) [0|429496729.5] "AH" Vector__XXX
 SG_ TOTAL_CHRG_AH : 288|32@1+ (0.1,0) [0|429496729.5] "AH" Vector__XXX
 SG_ BCU_TERMINAL_TEMP_MAX_POSI : 400|16@1+ (1,0) [0|65535] "N AN" Vector__XXX
 SG_ BCU_TERMINAL_TEMP_MAX : 384|16@1- (0.1,0) [-3276.8|3276.7] "℃" Vector__XXX
 SG_ VAR_SYS_SOE_RADE : 368|16@1+ (0.1,0) [0|655.35] "KWH" Vector__XXX
 SG_ VAR_SYS_SOE_ACE : 352|16@1+ (0.1,0) [0|655.35] "KWH" Vector__XXX
 SG_ TOTAL_DSCH_KWH : 256|32@1+ (0.1,0) [0|42949672.95] "KWH" Vector__XXX
 SG_ TOTAL_CHRG_KWH : 224|32@1+ (0.1,0) [0|42949672.95] "KWH" Vector__XXX
 SG_ VAR_SYS_MINT_POSI : 48|16@1+ (1,0) [0|65535] "NAN" Vector__XXX
 SG_ VAR_SYS_CELL_MIN_SOC_TEMP : 208|16@1+ (0.1,0) [0|6553.5] "%" Vector__XXX
 SG_ VAR_SYS_CELL_MIN_SOC : 192|16@1+ (0.1,0) [0|6553.5] "%" Vector__XXX
 SG_ VAR_SYS_CELL_MAX_SOC_TEMP : 176|16@1+ (0.1,0) [0|6553.5] "%" Vector__XXX
 SG_ VAR_SYS_CELL_MAX_SOC : 160|16@1+ (0.1,0) [0|6553.5] "%" Vector__XXX
 SG_ VAR_SYS_MINV_POSI : 112|16@1+ (1,0) [0|65535] "NAN" Vector__XXX
 SG_ VAR_SYS_MAXV_POSI : 96|16@1+ (1,0) [0|65535] "NAN" Vector__XXX
 SG_ CELL_VOLT_MIN : 80|16@1+ (1,0) [0|65535] "mV" Vector__XXX
 SG_ CELL_VOLT_MAX : 64|16@1+ (1,0) [0|65535] "mV" Vector__XXX
 SG_ CELL_TEMP_MIN : 16|16@1- (0.1,0) [-3276.8|3276.7] "℃" Vector__XXX
 SG_ CELL_TEMP_MAX : 0|16@1- (0.1,0) [-3276.8|3276.7] "℃" Vector__XXX
 SG_ CELL_AVG_TEMP : 144|16@1- (0.1,0) [-3276.8|3276.7] "℃" Vector__XXX
 SG_ CELL_AVG_VOLT : 128|16@1+ (1,0) [0|65535] "mV" Vector__XXX
 SG_ VAR_SYS_MAXT_POSI : 32|16@1+ (1,0) [0|65535] "NAN" Vector__XXX

BO_ 2465267872 BCU12F100A1: 8 BCU
 SG_ BCU_CALI_ADDR_STATE : 0|8@1+ (1,0) [0|255] "NAN" Vector__XXX

BO_ 2465267951 BAU12F100EF: 8 BAU
 SG_ CALI_BCU_ADDR_STATE : 8|8@1+ (1,0) [0|255] "" Vector__XXX
 SG_ CALI_BCU_ADDR : 0|8@1+ (1,0) [0|255] "" Vector__XXX

BO_ 2453709039 BAU1240A0EF: 8 BAU
 SG_ SET_TIME_NOW : 0|64@1+ (1,0) [0|1.84467440737096E+19] "NAN" Vector__XXX

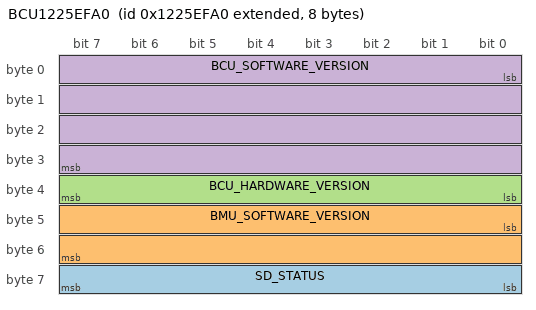
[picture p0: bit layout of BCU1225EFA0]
BO_ 2451959712 BCU1225EFA0: 8 BCU
 SG_ SD_STATUS : 56|8@1+ (1,0) [0|255] "NAN" Vector__XXX
 SG_ BMU_SOFTWARE_VERSION : 40|16@1+ (1,0) [0|0] "NAN" Vector__XXX
 SG_ BCU_HARDWARE_VERSION : 32|8@1+ (1,0) [0|0] "NAN" Vector__XXX
 SG_ BCU_SOFTWARE_VERSION : 0|32@1+ (1,0) [0|0] "NAN" Vector__XXX

BO_ 2454757615 BAU1250A0EF: 64 BAU
 SG_ REV_BAU_SOC_MIN : 16|16@1+ (0.1,0) [0|6553.5] "%" Vector__XXX
 SG_ REV_BAU_SOC_MAX : 0|16@1+ (0.1,0) [0|6553.5] "%" Vector__XXX

BO_ 2450911136 BCU1215EFA0: 64 BCU
 SG_ ALARM_TIME : 72|32@1- (1,0) [0|0] "" Vector__XXX
 SG_ ALARM_AlmLvValue : 56|16@1- (1,0) [-32768|32767] "" Vector__XXX
 SG_ ALARM_RealValue : 40|16@1- (1,0) [-32768|32767] "" Vector__XXX
 SG_ ALARM_INFO1 : 8|32@1+ (1,0) [0|0] "" Vector__XXX
 SG_ ALARM_ADD_REMOVE_FLAG : 0|1@1+ (1,0) [0|0] "NAN" Vector__XXX

BO_ 2452221856 BCU1229EFA0: 8 BCU

BO_ 2465333487 BAU12F200EF: 8 BAU
 SG_ BAU_CTRL_REQ : 32|16@1+ (1,0) [0|65535] "" Vector__XXX
 SG_ BCU_ADDR : 0|8@1+ (1,0) [0|255] "NAN" Vector__XXX

BO_ 2449600416 BCU1201EFA0: 64 BCU
 SG_ VAR_SYS_MOST_SEVERE_LEVEL : 384|16@1+ (1,0) [0|65535] "NAN" Vector__XXX
 SG_ SYS_FULL_CHRG_DCHG : 104|8@1+ (1,0) [0|0] "NAN" Vector__XXX
 SG_ SYS_ACC_VOL : 32|16@1+ (0.1,0) [0|6553.5] "V" Vector__XXX
 SG_ BCU_HV_BOX_TEMP_BP : 352|16@1- (0.1,0) [-3276.8|3276.7] "℃" Vector__XXX
 SG_ BCU_HV_BOX_TEMP_BN : 336|16@1- (0.1,0) [-3276.8|3276.7] "℃" Vector__XXX
 SG_ BCU_HV_BOX_TEMP_PP : 320|16@1- (0.1,0) [-3276.8|3276.7] "℃" Vector__XXX
 SG_ BCU_HV_BOX_TEMP_PN : 304|16@1- (0.1,0) [-3276.8|3276.7] "℃" Vector__XXX
 SG_ DI_STATUS : 288|16@1+ (1,0) [0|65535] "NAN" Vector__XXX
 SG_ RELAY_STATUS : 272|16@1+ (1,0) [0|65535] "NAN" Vector__XXX
 SG_ VAR_SYS_ACTV_ALM_NUM : 256|16@1+ (1,0) [0|65535] "" Vector__XXX
 SG_ ALLOW_DSCH_60S_POWER : 240|16@1+ (10,0) [0|6553.5] "W" Vector__XXX
 SG_ ALLOW_DSCH_60S_CURR : 224|16@1+ (0.1,0) [0|6553.5] "A" Vector__XXX
 SG_ ALLOW_CHRG_60S_POWER : 208|16@1+ (10,0) [0|655350] "W" Vector__XXX
 SG_ ALLOW_CHRG_60S_CURR : 192|16@1+ (0.1,0) [0|6553.5] "A" Vector__XXX
 SG_ VAR_SYS_SOE_RADE : 176|16@1+ (0.1,0) [0|655.35] "KWH" Vector__XXX
 SG_ VAR_SYS_SOE_ACE : 160|16@1+ (0.1,0) [0|655.35] "KWH" Vector__XXX
 SG_ VAR_SYS_SOH_LT : 144|16@1+ (0.1,0) [0|6553.5] "%" Vector__XXX
 SG_ VAR_SYS_DIS_SOC : 128|16@1+ (0.1,0) [0|6553.5] "%" Vector__XXX
 SG_ VAR_SYS_SOC : 112|16@1+ (0.1,0) [0|6553.5] "%" Vector__XXX
 SG_ VAR_SYS_RUN_STATUS : 96|8@1+ (1,0) [0|255] "NAN" Vector__XXX
 SG_ SAMP_CurrIntgSum : 64|32@1- (0.001,0) [-2147483.648|2147483.647] "AS" Vector__XXX
 SG_ HV_ON_REQ : 368|16@1+ (1,0) [0|0] "" Vector__XXX
 SG_ VAR_SYS_CURR : 48|16@1- (0.1,0) [-3276.8|3276.7] "A" Vector__XXX
 SG_ VAR_SYS_PACK_VOLT : 16|16@1+ (0.1,0) [0|6553.5] "V" Vector__XXX
 SG_ VAR_SYS_BAT_VOLT : 0|16@1+ (0.1,0) [0|6553.5] "V" Vector__XXX

CM_ BO_ 3221225472 "This is a message for not used signals, created by Vector CANdb++ DBC OLE DB Provider.";
CM_ SG_ 3221225472 VAR_SYS_PRECHRG_VOL "预充时，预充接触器总压";
CM_ SG_ 3221225472 CELL_INFO3 "单体类数据";
CM_ SG_ 3221225472 CELL_INFO2 "单体类数据";
CM_ SG_ 3221225472 CELL_INFO1 "单体类数据";
CM_ SG_ 3221225472 INDEX "单体类数据编号";
CM_ SG_ 3221225472 SENT_INDEX "发送单体数据索引";
CM_ SG_ 3221225472 SENT_TYPE "发送数据标识符0-单体电压，1-单体温度，5-极柱温度，6-高压箱温度";
CM_ SG_ 3221225472 VAR_SYS_PRECHRG_EEROR "预充错误";
CM_ BO_ 2449731488 "综合信息3";
CM_ SG_ 2449731488 SINGLE_DISCHARGE_AH "单次放电容量";
CM_ SG_ 2449731488 SINGLE_DISCHARGE_EN "单次放电电量";
CM_ SG_ 2449731488 SINGLE_CHARGE_AH "单次充电容量";
CM_ SG_ 2449731488 SINGLE_CHARGE_EN "单次充电电量";
CM_ SG_ 2449731488 DAILY_DISCHARGE_AH "日累计放电容量";
CM_ SG_ 2449731488 DAILY_DISCHARGE_EN "日累计放电电量";
CM_ SG_ 2449731488 DAILY_CHARGE_AH "日累计充电容量";
CM_ SG_ 2449731488 DAILY_CHARGE_EN "日累计充电电量";
CM_ SG_ 2449731488 BCU_RUN_TIME "BCU本次上电运行时间";
CM_ SG_ 2449731488 BCU_ACC_RUN_TIME "BCU累计运行时间";
CM_ BO_ 2462773152 "Balance temperature 33-64";
CM_ BO_ 2462707616 "Balance temperature 1-32";
CM_ BO_ 2462248864 "极柱温度";
CM_ BO_ 2462183328 "极柱温度";
CM_ BO_ 2462117792 "单体温度";
CM_ BO_ 2462052256 "单体温度";
CM_ BO_ 2461986720 "单体温度";
CM_ BO_ 2461921184 "单体温度";
CM_ BO_ 2461855648 "单体温度";
CM_ BO_ 2461790112 "单体温度";
CM_ BO_ 2461724576 "单体温度";
CM_ BO_ 2461659040 "单体温度";
CM_ BO_ 2461593504 "单体温度";
CM_ BO_ 2461527968 "单体温度";
CM_ BO_ 2461462432 "单体温度";
CM_ BO_ 2461396896 "单体温度";
CM_ BO_ 2461331360 "单体温度";
CM_ BO_ 2461265824 "单体温度";
CM_ BO_ 2461200288 "单体温度";
CM_ BO_ 2461134752 "单体温度";
CM_ SG_ 2461134752 CELL_TEMP_ID_001 "单体温度001";
CM_ BO_ 2461069216 "单体电压";
CM_ BO_ 2461003680 "单体电压";
CM_ BO_ 2460938144 "单体电压";
CM_ BO_ 2460872608 "单体电压";
CM_ BO_ 2460807072 "单体电压";
CM_ BO_ 2460741536 "单体电压";
CM_ BO_ 2460676000 "单体电压";
CM_ BO_ 2460610464 "单体电压";
CM_ BO_ 2460544928 "单体电压";
CM_ BO_ 2460479392 "单体电压";
CM_ BO_ 2460413856 "单体电压";
CM_ BO_ 2460348320 "单体电压";
CM_ BO_ 2460282784 "单体电压";
CM_ BO_ 2460217248 "单体电压";
CM_ BO_ 2460151712 "单体电压";
CM_ BO_ 2460086176 "单体电压";
CM_ SG_ 2460086176 CELL_VOL_ID_001 "单体电压001";
CM_ BO_ 2449797024 "综合信息4";
CM_ SG_ 2449797024 ALARM_STATE_ID_128 "告警状态 0_无告警 1_1级告警 2_2级告警 3_三级告警";
CM_ SG_ 2449797024 ALARM_STATE_ID_127 "告警状态 0_无告警 1_1级告警 2_2级告警 3_三级告警";
CM_ SG_ 2449797024 ALARM_STATE_ID_126 "告警状态 0_无告警 1_1级告警 2_2级告警 3_三级告警";
CM_ SG_ 2449797024 ALARM_STATE_ID_125 "告警状态 0_无告警 1_1级告警 2_2级告警 3_三级告警";
CM_ SG_ 2449797024 ALARM_STATE_ID_124 "告警状态 0_无告警 1_1级告警 2_2级告警 3_三级告警";
CM_ SG_ 2449797024 ALARM_STATE_ID_123 "告警状态 0_无告警 1_1级告警 2_2级告警 3_三级告警";
CM_ SG_ 2449797024 ALARM_STATE_ID_122 "告警状态 0_无告警 1_1级告警 2_2级告警 3_三级告警";
CM_ SG_ 2449797024 ALARM_STATE_ID_121 "告警状态 0_无告警 1_1级告警 2_2级告警 3_三级告警";
CM_ SG_ 2449797024 ALARM_STATE_ID_120 "告警状态 0_无告警 1_1级告警 2_2级告警 3_三级告警";
CM_ SG_ 2449797024 ALARM_STATE_ID_119 "告警状态 0_无告警 1_1级告警 2_2级告警 3_三级告警";
CM_ SG_ 2449797024 ALARM_STATE_ID_118 "告警状态 0_无告警 1_1级告警 2_2级告警 3_三级告警";
CM_ SG_ 2449797024 ALARM_STATE_ID_117 "告警状态 0_无告警 1_1级告警 2_2级告警 3_三级告警";
CM_ SG_ 2449797024 ALARM_STATE_ID_116 "告警状态 0_无告警 1_1级告警 2_2级告警 3_三级告警";
CM_ SG_ 2449797024 ALARM_STATE_ID_115 "告警状态 0_无告警 1_1级告警 2_2级告警 3_三级告警";
CM_ SG_ 2449797024 ALARM_STATE_ID_114 "告警状态 0_无告警 1_1级告警 2_2级告警 3_三级告警";
CM_ SG_ 2449797024 ALARM_STATE_ID_113 "告警状态 0_无告警 1_1级告警 2_2级告警 3_三级告警";
CM_ SG_ 2449797024 ALARM_STATE_ID_112 "告警状态 0_无告警 1_1级告警 2_2级告警 3_三级告警";
CM_ SG_ 2449797024 ALARM_STATE_ID_111 "告警状态 0_无告警 1_1级告警 2_2级告警 3_三级告警";
CM_ SG_ 2449797024 ALARM_STATE_ID_110 "告警状态 0_无告警 1_1级告警 2_2级告警 3_三级告警";
CM_ SG_ 2449797024 ALARM_STATE_ID_109 "告警状态 0_无告警 1_1级告警 2_2级告警 3_三级告警";
CM_ SG_ 2449797024 ALARM_STATE_ID_108 "告警状态 0_无告警 1_1级告警 2_2级告警 3_三级告警";
CM_ SG_ 2449797024 ALARM_STATE_ID_107 "告警状态 0_无告警 1_1级告警 2_2级告警 3_三级告警";
CM_ SG_ 2449797024 ALARM_STATE_ID_106 "告警状态 0_无告警 1_1级告警 2_2级告警 3_三级告警";
CM_ SG_ 2449797024 ALARM_STATE_ID_105 "告警状态 0_无告警 1_1级告警 2_2级告警 3_三级告警";
CM_ SG_ 2449797024 ALARM_STATE_ID_104 "告警状态 0_无告警 1_1级告警 2_2级告警 3_三级告警";
CM_ SG_ 2449797024 ALARM_STATE_ID_103 "告警状态 0_无告警 1_1级告警 2_2级告警 3_三级告警";
CM_ SG_ 2449797024 ALARM_STATE_ID_102 "告警状态 0_无告警 1_1级告警 2_2级告警 3_三级告警";
CM_ SG_ 2449797024 ALARM_STATE_ID_101 "告警状态 0_无告警 1_1级告警 2_2级告警 3_三级告警";
CM_ SG_ 2449797024 ALARM_STATE_ID_100 "告警状态 0_无告警 1_1级告警 2_2级告警 3_三级告警";
CM_ SG_ 2449797024 ALARM_STATE_ID_099 "告警状态 0_无告警 1_1级告警 2_2级告警 3_三级告警";
CM_ SG_ 2449797024 ALARM_STATE_ID_098 "告警状态 0_无告警 1_1级告警 2_2级告警 3_三级告警";
CM_ SG_ 2449797024 ALARM_STATE_ID_097 "告警状态 0_无告警 1_1级告警 2_2级告警 3_三级告警";
CM_ SG_ 2449797024 ALARM_STATE_ID_096 "告警状态 0_无告警 1_1级告警 2_2级告警 3_三级告警";
CM_ SG_ 2449797024 ALARM_STATE_ID_095 "告警状态 0_无告警 1_1级告警 2_2级告警 3_三级告警";
CM_ SG_ 2449797024 ALARM_STATE_ID_094 "告警状态 0_无告警 1_1级告警 2_2级告警 3_三级告警";
CM_ SG_ 2449797024 ALARM_STATE_ID_093 "告警状态 0_无告警 1_1级告警 2_2级告警 3_三级告警";
CM_ SG_ 2449797024 ALARM_STATE_ID_092 "告警状态 0_无告警 1_1级告警 2_2级告警 3_三级告警";
CM_ SG_ 2449797024 ALARM_STATE_ID_091 "告警状态 0_无告警 1_1级告警 2_2级告警 3_三级告警";
CM_ SG_ 2449797024 ALARM_STATE_ID_090 "告警状态 0_无告警 1_1级告警 2_2级告警 3_三级告警";
CM_ SG_ 2449797024 ALARM_STATE_ID_089 "告警状态 0_无告警 1_1级告警 2_2级告警 3_三级告警";
CM_ SG_ 2449797024 ALARM_STATE_ID_088 "告警状态 0_无告警 1_1级告警 2_2级告警 3_三级告警";
CM_ SG_ 2449797024 ALARM_STATE_ID_087 "告警状态 0_无告警 1_1级告警 2_2级告警 3_三级告警";
CM_ SG_ 2449797024 ALARM_STATE_ID_086 "告警状态 0_无告警 1_1级告警 2_2级告警 3_三级告警";
CM_ SG_ 2449797024 ALARM_STATE_ID_085 "告警状态 0_无告警 1_1级告警 2_2级告警 3_三级告警";
CM_ SG_ 2449797024 ALARM_STATE_ID_084 "告警状态 0_无告警 1_1级告警 2_2级告警 3_三级告警";
CM_ SG_ 2449797024 ALARM_STATE_ID_083 "告警状态 0_无告警 1_1级告警 2_2级告警 3_三级告警";
CM_ SG_ 2449797024 ALARM_STATE_ID_082 "告警状态 0_无告警 1_1级告警 2_2级告警 3_三级告警";
CM_ SG_ 2449797024 ALARM_STATE_ID_081 "告警状态 0_无告警 1_1级告警 2_2级告警 3_三级告警";
CM_ SG_ 2449797024 ALARM_STATE_ID_080 "告警状态 0_无告警 1_1级告警 2_2级告警 3_三级告警";
CM_ SG_ 2449797024 ALARM_STATE_ID_079 "告警状态 0_无告警 1_1级告警 2_2级告警 3_三级告警";
CM_ SG_ 2449797024 ALARM_STATE_ID_078 "告警状态 0_无告警 1_1级告警 2_2级告警 3_三级告警";
CM_ SG_ 2449797024 ALARM_STATE_ID_077 "告警状态 0_无告警 1_1级告警 2_2级告警 3_三级告警";
CM_ SG_ 2449797024 ALARM_STATE_ID_076 "告警状态 0_无告警 1_1级告警 2_2级告警 3_三级告警";
CM_ SG_ 2449797024 ALARM_STATE_ID_075 "告警状态 0_无告警 1_1级告警 2_2级告警 3_三级告警";
CM_ SG_ 2449797024 ALARM_STATE_ID_074 "告警状态 0_无告警 1_1级告警 2_2级告警 3_三级告警";
CM_ SG_ 2449797024 ALARM_STATE_ID_073 "告警状态 0_无告警 1_1级告警 2_2级告警 3_三级告警";
CM_ SG_ 2449797024 ALARM_STATE_ID_072 "告警状态 0_无告警 1_1级告警 2_2级告警 3_三级告警";
CM_ SG_ 2449797024 ALARM_STATE_ID_071 "告警状态 0_无告警 1_1级告警 2_2级告警 3_三级告警";
CM_ SG_ 2449797024 ALARM_STATE_ID_070 "告警状态 0_无告警 1_1级告警 2_2级告警 3_三级告警";
CM_ SG_ 2449797024 ALARM_STATE_ID_069 "告警状态 0_无告警 1_1级告警 2_2级告警 3_三级告警";
CM_ SG_ 2449797024 ALARM_STATE_ID_068 "告警状态 0_无告警 1_1级告警 2_2级告警 3_三级告警";
CM_ SG_ 2449797024 ALARM_STATE_ID_067 "告警状态 0_无告警 1_1级告警 2_2级告警 3_三级告警";
CM_ SG_ 2449797024 ALARM_STATE_ID_066 "告警状态 0_无告警 1_1级告警 2_2级告警 3_三级告警";
CM_ SG_ 2449797024 ALARM_STATE_ID_065 "告警状态 0_无告警 1_1级告警 2_2级告警 3_三级告警";
CM_ SG_ 2449797024 ALARM_STATE_ID_064 "告警状态 0_无告警 1_1级告警 2_2级告警 3_三级告警";
CM_ SG_ 2449797024 ALARM_STATE_ID_063 "告警状态 0_无告警 1_1级告警 2_2级告警 3_三级告警";
CM_ SG_ 2449797024 ALARM_STATE_ID_062 "告警状态 0_无告警 1_1级告警 2_2级告警 3_三级告警";
CM_ SG_ 2449797024 ALARM_STATE_ID_061 "告警状态 0_无告警 1_1级告警 2_2级告警 3_三级告警";
CM_ SG_ 2449797024 ALARM_STATE_ID_060 "告警状态 0_无告警 1_1级告警 2_2级告警 3_三级告警";
CM_ SG_ 2449797024 ALARM_STATE_ID_059 "告警状态 0_无告警 1_1级告警 2_2级告警 3_三级告警";
CM_ SG_ 2449797024 ALARM_STATE_ID_058 "告警状态 0_无告警 1_1级告警 2_2级告警 3_三级告警";
CM_ SG_ 2449797024 ALARM_STATE_ID_057 "告警状态 0_无告警 1_1级告警 2_2级告警 3_三级告警";
CM_ SG_ 2449797024 ALARM_STATE_ID_056 "告警状态 0_无告警 1_1级告警 2_2级告警 3_三级告警";
CM_ SG_ 2449797024 ALARM_STATE_ID_055 "告警状态 0_无告警 1_1级告警 2_2级告警 3_三级告警";
CM_ SG_ 2449797024 ALARM_STATE_ID_054 "告警状态 0_无告警 1_1级告警 2_2级告警 3_三级告警";
CM_ SG_ 2449797024 ALARM_STATE_ID_053 "告警状态 0_无告警 1_1级告警 2_2级告警 3_三级告警";
CM_ SG_ 2449797024 ALARM_STATE_ID_052 "告警状态 0_无告警 1_1级告警 2_2级告警 3_三级告警";
CM_ SG_ 2449797024 ALARM_STATE_ID_051 "告警状态 0_无告警 1_1级告警 2_2级告警 3_三级告警";
CM_ SG_ 2449797024 ALARM_STATE_ID_050 "告警状态 0_无告警 1_1级告警 2_2级告警 3_三级告警";
CM_ SG_ 2449797024 ALARM_STATE_ID_049 "告警状态 0_无告警 1_1级告警 2_2级告警 3_三级告警";
CM_ SG_ 2449797024 ALARM_STATE_ID_048 "告警状态 0_无告警 1_1级告警 2_2级告警 3_三级告警";
CM_ SG_ 2449797024 ALARM_STATE_ID_047 "告警状态 0_无告警 1_1级告警 2_2级告警 3_三级告警";
CM_ SG_ 2449797024 ALARM_STATE_ID_046 "告警状态 0_无告警 1_1级告警 2_2级告警 3_三级告警";
CM_ SG_ 2449797024 ALARM_STATE_ID_045 "【预充故障】告警状态 0_无告警 1_1级告警 2_2级告警 3_三级告警";
CM_ SG_ 2449797024 ALARM_STATE_ID_044 "【簇总压校验差过大】告警状态 0_无告警 1_1级告警 2_2级告警 3_三级告警";
CM_ SG_ 2449797024 ALARM_STATE_ID_043 "【充放电回路异常】告警状态 0_无告警 1_1级告警 2_2级告警 3_三级告警";
CM_ SG_ 2449797024 ALARM_STATE_ID_042 "【BCU自检故障】告警状态 0_无告警 1_1级告警 2_2级告警 3_三级告警";
CM_ SG_ 2449797024 ALARM_STATE_ID_041 "【BMU自检故障】告警状态 0_无告警 1_1级告警 2_2级告警 3_三级告警";
CM_ SG_ 2449797024 ALARM_STATE_ID_040 "【BCU功能安全告警】告警状态 0_无告警 1_1级告警 2_2级告警 3_三级告警";
CM_ SG_ 2449797024 ALARM_STATE_ID_039 "【单体电压故障】告警状态 0_无告警 1_1级告警 2_2级告警 3_三级告警";
CM_ SG_ 2449797024 ALARM_STATE_ID_038 "【单体温度传感器故障】告警状态 0_无告警 1_1级告警 2_2级告警 3_三级告警";
CM_ SG_ 2449797024 ALARM_STATE_ID_037 "【高压箱温度传感器故障】告警状态 0_无告警 1_1级告警 2_2级告警 3_三级告警";
CM_ SG_ 2449797024 ALARM_STATE_ID_036 "【极柱温度传感器故障】告警状态 0_无告警 1_1级告警 2_2级告警 3_三级告警";
CM_ SG_ 2449797024 ALARM_STATE_ID_035 "【NTC故障】告警状态 0_无告警 1_1级告警 2_2级告警 3_三级告警";
CM_ SG_ 2449797024 ALARM_STATE_ID_034 "【断路器断开（隔离空开）】告警状态 0_无告警 1_1级告警 2_2级告警 3_三级告警";
CM_ SG_ 2449797024 ALARM_STATE_ID_033 "【电流传感器故障】告警状态 0_无告警 1_1级告警 2_2级告警 3_三级告警";
CM_ SG_ 2449797024 ALARM_STATE_ID_032 "【熔断器故障】告警状态 0_无告警 1_1级告警 2_2级告警 3_三级告警";
CM_ SG_ 2449797024 ALARM_STATE_ID_031 "【BCU概要故障】告警状态 0_无告警 1_1级告警 2_2级告警 3_三级告警";
CM_ SG_ 2449797024 ALARM_STATE_ID_030 "【接触器粘连故障】告警状态 0_无告警 1_1级告警 2_2级告警 3_三级告警";
CM_ SG_ 2449797024 ALARM_STATE_ID_029 "【BMU概要故障】告警状态 0_无告警 1_1级告警 2_2级告警 3_三级告警";
CM_ SG_ 2449797024 ALARM_STATE_ID_028 "【BMU通讯故障】告警状态 0_无告警 1_1级告警 2_2级告警 3_三级告警";
CM_ SG_ 2449797024 ALARM_STATE_ID_027 "【BAU通信故障】告警状态 0_无告警 1_1级告警 2_2级告警 3_三级告警";
CM_ SG_ 2449797024 ALARM_STATE_ID_026 "【温升过高】告警状态 0_无告警 1_1级告警 2_2级告警 3_三级告警";
CM_ SG_ 2449797024 ALARM_STATE_ID_025 "【极柱过温】告警状态 0_无告警 1_1级告警 2_2级告警 3_三级告警";
CM_ SG_ 2449797024 ALARM_STATE_ID_024 "【电池组SOC过低】告警状态 0_无告警 1_1级告警 2_2级告警 3_三级告警";
CM_ SG_ 2449797024 ALARM_STATE_ID_023 "【高压箱内连接器温度高】告警状态 0_无告警 1_1级告警 2_2级告警 3_三级告警";
CM_ SG_ 2449797024 ALARM_STATE_ID_022 "【绝缘检测故障】告警状态 0_无告警 1_1级告警 2_2级告警 3_三级告警";
CM_ SG_ 2449797024 ALARM_STATE_ID_021 "【绝缘低】告警状态 0_无告警 1_1级告警 2_2级告警 3_三级告警";
CM_ SG_ 2449797024 ALARM_STATE_ID_020 "【电池簇放电电池单体温度极差】告警状态 0_无告警 1_1级告警 2_2级告警 3_三级告警";
CM_ SG_ 2449797024 ALARM_STATE_ID_019 "【电池簇充电电池单体温度极差】告警状态 0_无告警 1_1级告警 2_2级告警 3_三级告警";
CM_ SG_ 2449797024 ALARM_STATE_ID_018 "【放电温度过低】告警状态 0_无告警 1_1级告警 2_2级告警 3_三级告警";
CM_ SG_ 2449797024 ALARM_STATE_ID_017 "【放电温度过高】告警状态 0_无告警 1_1级告警 2_2级告警 3_三级告警";
CM_ SG_ 2449797024 ALARM_STATE_ID_016 "【充电温度过低】告警状态 0_无告警 1_1级告警 2_2级告警 3_三级告警";
CM_ SG_ 2449797024 ALARM_STATE_ID_015 "【充电温度过高】告警状态 0_无告警 1_1级告警 2_2级告警 3_三级告警";
CM_ SG_ 2449797024 ALARM_STATE_ID_014 "【电池单体低温】告警状态 0_无告警 1_1级告警 2_2级告警 3_三级告警";
CM_ SG_ 2449797024 ALARM_STATE_ID_013 "【电池单体高温】告警状态 0_无告警 1_1级告警 2_2级告警 3_三级告警";
CM_ SG_ 2449797024 ALARM_STATE_ID_012 "【放电过流】告警状态 0_无告警 1_1级告警 2_2级告警 3_三级告警";
CM_ SG_ 2449797024 ALARM_STATE_ID_011 "【充电过流】告警状态 0_无告警 1_1级告警 2_2级告警 3_三级告警";
CM_ SG_ 2449797024 ALARM_STATE_ID_010 "【模组压差过大】告警状态 0_无告警 1_1级告警 2_2级告警 3_三级告警";
CM_ SG_ 2449797024 ALARM_STATE_ID_009 "【单体压差过大】告警状态 0_无告警 1_1级告警 2_2级告警 3_三级告警";
CM_ SG_ 2449797024 ALARM_STATE_ID_008 "【电池簇放电电池单体电压极差】告警状态 0_无告警 1_1级告警 2_2级告警 3_三级告警";
CM_ SG_ 2449797024 ALARM_STATE_ID_007 "【电池簇充电电池单体电压极差】告警状态 0_无告警 1_1级告警 2_2级告警 3_三级告警";
CM_ SG_ 2449797024 ALARM_STATE_ID_006 "【模组欠压】告警状态 0_无告警 1_1级告警 2_2级告警 3_三级告警";
CM_ SG_ 2449797024 ALARM_STATE_ID_005 "【模组过压】告警状态 0_无告警 1_1级告警 2_2级告警 3_三级告警";
CM_ SG_ 2449797024 ALARM_STATE_ID_004 "【总电压过低】告警状态 0_无告警 1_1级告警 2_2级告警 3_三级告警";
CM_ SG_ 2449797024 ALARM_STATE_ID_003 "【总电压过高】告警状态 0_无告警 1_1级告警 2_2级告警 3_三级告警";
CM_ SG_ 2449797024 ALARM_STATE_ID_002 "【单体电压过低】告警状态 0_无告警 1_1级告警 2_2级告警 3_三级告警";
CM_ SG_ 2449797024 ALARM_STATE_ID_001 "【单体电压过高】告警状态 0_无告警 1_1级告警 2_2级告警 3_三级告警";
CM_ BO_ 2449665952 "综合信息2";
CM_ SG_ 2449665952 BCU_TERMINAL_TEMP_MIN_POSI "位置 高字节模组位置（1开始），低字节（1-正极柱，2-负极柱）";
CM_ SG_ 2449665952 BCU_TERMINAL_TEMP_MIN "极柱温度最小值";
CM_ SG_ 2449665952 VAR_SYS_ANALOG_PBUS_RES "正对地电阻";
CM_ SG_ 2449665952 VAR_SYS_ANALOG_NBUS_RES "负对地电阻";
CM_ SG_ 2449665952 TOTAL_DSCH_AH "累计放电容量";
CM_ SG_ 2449665952 TOTAL_CHRG_AH "累计充电容量";
CM_ SG_ 2449665952 BCU_TERMINAL_TEMP_MAX_POSI "位置 高字节模组位置（1开始），低字节（1-正极柱，2-负极柱）";
CM_ SG_ 2449665952 BCU_TERMINAL_TEMP_MAX "极柱温度最大值";
CM_ SG_ 2449665952 VAR_SYS_SOE_RADE "可放电电量";
CM_ SG_ 2449665952 VAR_SYS_SOE_ACE "可充电电量";
CM_ SG_ 2449665952 TOTAL_DSCH_KWH "累计放电电量";
CM_ SG_ 2449665952 TOTAL_CHRG_KWH "累计充电电量";
CM_ SG_ 2449665952 VAR_SYS_MINT_POSI "最低温度位置,高字节表示所在从板位置(从1开始算)，低字节表示所在单体位置(从1开始算  不含跳线)";
CM_ SG_ 2449665952 VAR_SYS_CELL_MIN_SOC_TEMP "最小SOC温度修正";
CM_ SG_ 2449665952 VAR_SYS_CELL_MIN_SOC "最小SOC";
CM_ SG_ 2449665952 VAR_SYS_CELL_MAX_SOC_TEMP "最大SOC温度修正";
CM_ SG_ 2449665952 VAR_SYS_CELL_MAX_SOC "最大SOC";
CM_ SG_ 2449665952 VAR_SYS_MINV_POSI "最低电压位置,高字节表示所在从板位置(从1开始算)，低字节表示所在单体位置(从1开始算  不含跳线)最低电压位置,高字节表示所在从板位置(从1开始算)，低字节表示所在单体位置(从1开始算  不含跳线)";
CM_ SG_ 2449665952 VAR_SYS_MAXV_POSI "最高电压位置,高字节表示所在从板位置(从1开始算)，低字节表示所在单体位置(从1开始算  不含跳线)";
CM_ SG_ 2449665952 CELL_VOLT_MIN "最小单体电压";
CM_ SG_ 2449665952 CELL_VOLT_MAX "最大单体电压";
CM_ SG_ 2449665952 CELL_TEMP_MIN "最小单体温度";
CM_ SG_ 2449665952 CELL_TEMP_MAX "最大单体温度";
CM_ SG_ 2449665952 CELL_AVG_TEMP "平均单体温度";
CM_ SG_ 2449665952 CELL_AVG_VOLT "平均单体电压";
CM_ SG_ 2449665952 VAR_SYS_MAXT_POSI "最高温度位置,高字节表示所在从板位置(从1开始算)，低字节表示所在单体位置(从1开始算  不含跳线)";
CM_ BO_ 2465267872 "簇自动寻址响应帧";
CM_ SG_ 2465267872 BCU_CALI_ADDR_STATE "簇标定状态 00_初始 01_启动 02_成功 03_失败
";
CM_ BO_ 2465267951 "簇控自动寻址帧";
CM_ SG_ 2465267951 CALI_BCU_ADDR_STATE "标定状态	00_初始 01_标定 02_成功 03_失败
";
CM_ SG_ 2465267951 CALI_BCU_ADDR "标定地址	1-32";
CM_ BO_ 2453709039 "簇系统设置时间";
CM_ SG_ 2453709039 SET_TIME_NOW "UINT16 Year;UINT8 Month;UINT8 Day;UINT8 Hour; UINT8 Minute;UINT8 Second;UINT8 Week;";
CM_ BO_ 2451959712 "簇簇系统版本信息响应";
CM_ SG_ 2451959712 SD_STATUS "SD卡状态[ bit0-未识别到 bit1-已就绪 bit2-已可以拔出  bit3-读文件中 ，bit4-写文件中，bit5-错误";
CM_ SG_ 2451959712 BMU_SOFTWARE_VERSION "BMU软件版本";
CM_ SG_ 2451959712 BCU_HARDWARE_VERSION "BCU硬件版本";
CM_ SG_ 2451959712 BCU_SOFTWARE_VERSION "BCU软件版本";
CM_ BO_ 2454757615 "BAU SOX数据修正";
CM_ SG_ 2454757615 REV_BAU_SOC_MIN "BAU修正最小SOC";
CM_ SG_ 2454757615 REV_BAU_SOC_MAX "BAU修正最大SOC";
CM_ BO_ 2450911136 "簇系统当前故障信息";
CM_ SG_ 2450911136 ALARM_TIME "告警时间";
CM_ SG_ 2450911136 ALARM_AlmLvValue "告警触发值";
CM_ SG_ 2450911136 ALARM_RealValue "告警实际值";
CM_ SG_ 2450911136 ALARM_INFO1 "//[Bit0-6] 表示模组内单体号  [Bit7-13] 表示模组号 [Bit14-15]预留，Bit16-19: 设备类型 Bit20-23: 告警级别  Bit24-31: 告警ID（具体什么告警）";
CM_ SG_ 2450911136 ALARM_ADD_REMOVE_FLAG "0xFBBF表示ADD告警信息第一帧/0xFAAF表示REMOVE告警信息第一帧    0xBFFB表示ADD告警信息第二帧/0xAFFA表示REMOVE告警信息第二帧";
CM_ BO_ 2465333487 "簇系统控制命令";
CM_ SG_ 2465333487 BAU_CTRL_REQ "BAU控制命令";
CM_ SG_ 2465333487 BCU_ADDR "BCU地址";
CM_ BO_ 2449600416 "综合信息1";
CM_ SG_ 2449600416 VAR_SYS_MOST_SEVERE_LEVEL "系统最严重告警级别  [低字节：0=无告警，1~5=5个级别；高字节：(0=默认正常，1=即将切断，2=故障切断，3=特殊故障立即切断) ";
CM_ SG_ 2449600416 SYS_FULL_CHRG_DCHG "系统满充满放状态";
CM_ SG_ 2449600416 SYS_ACC_VOL "系统累计总压";
CM_ SG_ 2449600416 BCU_HV_BOX_TEMP_BP "高压箱温度B+";
CM_ SG_ 2449600416 BCU_HV_BOX_TEMP_BN "高压箱温度B-";
CM_ SG_ 2449600416 BCU_HV_BOX_TEMP_PP "高压箱温度P+";
CM_ SG_ 2449600416 BCU_HV_BOX_TEMP_PN "高压箱温度P-";
CM_ SG_ 2449600416 DI_STATUS "DI输入状态  ";
CM_ SG_ 2449600416 RELAY_STATUS "继电器输出控制状态";
CM_ SG_ 2449600416 VAR_SYS_ACTV_ALM_NUM "告警数量";
CM_ SG_ 2449600416 ALLOW_DSCH_60S_POWER "最大允许放电功率";
CM_ SG_ 2449600416 ALLOW_DSCH_60S_CURR "最大允许放电电流";
CM_ SG_ 2449600416 ALLOW_CHRG_60S_POWER "最大允许充电功率";
CM_ SG_ 2449600416 ALLOW_CHRG_60S_CURR "最大允许充电电流";
CM_ SG_ 2449600416 VAR_SYS_SOE_RADE "可放电电量";
CM_ SG_ 2449600416 VAR_SYS_SOE_ACE "可充电电量";
CM_ SG_ 2449600416 VAR_SYS_SOH_LT "系统SOH查表值";
CM_ SG_ 2449600416 VAR_SYS_DIS_SOC "显示SOC";
CM_ SG_ 2449600416 VAR_SYS_SOC "系统SOC";
CM_ SG_ 2449600416 VAR_SYS_RUN_STATUS "系统运行状态 [0、初始 1、自测 2、准备 3、预充 4、高压待机 5、放电 6、充电 7、放空 8、充满 9、错误 10、切断 11、休眠]";
CM_ SG_ 2449600416 SAMP_CurrIntgSum "1S的电流积分量";
CM_ SG_ 2449600416 HV_ON_REQ "高压上下电请求";
CM_ SG_ 2449600416 VAR_SYS_CURR "系统电流";
CM_ SG_ 2449600416 VAR_SYS_PACK_VOLT "负载端电压";
CM_ SG_ 2449600416 VAR_SYS_BAT_VOLT "电池端电压";
BA_DEF_ SG_  "SigType" ENUM  "Default","Range","RangeSigned","ASCII","Discrete","Control","ReferencePGN","DTC","StringDelimiter","StringLength","StringLengthControl","MessageCounter","MessageChecksum";
BA_DEF_ SG_  "GenSigEVName" STRING ;
BA_DEF_ SG_  "GenSigILSupport" ENUM  "No","Yes";
BA_DEF_ SG_  "GenSigSendType" ENUM  "Cyclic","OnWrite","OnWriteWithRepetition","OnChange","OnChangeWithRepetition","IfActive","IfActiveWithRepetition","NoSigSendType";
BA_DEF_ SG_  "GenSigStartValue" INT 0 2147483647;
BA_DEF_ BO_  "GenMsgILSupport" ENUM  "No","Yes";
BA_DEF_ BO_  "GenMsgStartDelayTime" INT 0 100000;
BA_DEF_ BU_  "NmStationAddress" INT 0 255;
BA_DEF_ BO_  "GenMsgSendType" ENUM  "cyclic","NotUsed","IfActive","NotUsed","NotUsed","NotUsed","NotUsed","NotUsed","noMsgSendType";
BA_DEF_ BO_  "GenMsgRequestable" INT 0 1;
BA_DEF_ BO_  "GenMsgCycleTime" INT 0 3600000;
BA_DEF_  "DBName" STRING ;
BA_DEF_  "BusType" STRING ;
BA_DEF_  "ProtocolType" STRING ;
BA_DEF_ BO_  "VFrameFormat" ENUM  "StandardCAN","ExtendedCAN","reserved","J1939PG";
BA_DEF_DEF_  "SigType" "Default";
BA_DEF_DEF_  "GenSigEVName" "Env@Nodename_@Signame";
BA_DEF_DEF_  "GenSigILSupport" "Yes";
BA_DEF_DEF_  "GenSigSendType" "NoSigSendType";
BA_DEF_DEF_  "GenSigStartValue" 0;
BA_DEF_DEF_  "GenMsgILSupport" "Yes";
BA_DEF_DEF_  "GenMsgStartDelayTime" 0;
BA_DEF_DEF_  "NmStationAddress" 254;
BA_DEF_DEF_  "GenMsgSendType" "noMsgSendType";
BA_DEF_DEF_  "GenMsgRequestable" 1;
BA_DEF_DEF_  "GenMsgCycleTime" 0;
BA_DEF_DEF_  "DBName" "";
BA_DEF_DEF_  "BusType" "CAN";
BA_DEF_DEF_  "ProtocolType" "J1939";
BA_DEF_DEF_  "VFrameFormat" "J1939PG";
BA_ "DBName" "_";
BA_ "NmStationAddress" BU_ BCU 160;
BA_ "GenMsgSendType" BO_ 2449731488 0;
BA_ "GenMsgCycleTime" BO_ 2449731488 1000;
BA_ "GenMsgSendType" BO_ 2462773152 0;
BA_ "GenMsgCycleTime" BO_ 2462773152 1000;
BA_ "GenMsgSendType" BO_ 2462707616 0;
BA_ "GenMsgCycleTime" BO_ 2462707616 1000;
BA_ "GenMsgSendType" BO_ 2462248864 0;
BA_ "GenMsgCycleTime" BO_ 2462248864 100;
BA_ "GenMsgSendType" BO_ 2462183328 0;
BA_ "GenMsgCycleTime" BO_ 2462183328 100;
BA_ "GenMsgSendType" BO_ 2462117792 0;
BA_ "GenMsgCycleTime" BO_ 2462117792 100;
BA_ "GenMsgSendType" BO_ 2462052256 0;
BA_ "GenMsgCycleTime" BO_ 2462052256 100;
BA_ "GenMsgSendType" BO_ 2461986720 0;
BA_ "GenMsgCycleTime" BO_ 2461986720 100;
BA_ "GenMsgSendType" BO_ 2461921184 0;
BA_ "GenMsgCycleTime" BO_ 2461921184 100;
BA_ "GenMsgSendType" BO_ 2461855648 0;
BA_ "GenMsgCycleTime" BO_ 2461855648 100;
BA_ "GenMsgSendType" BO_ 2461790112 0;
BA_ "GenMsgCycleTime" BO_ 2461790112 100;
BA_ "GenMsgCycleTime" BO_ 2461724576 100;
BA_ "GenMsgSendType" BO_ 2461724576 0;
BA_ "GenMsgSendType" BO_ 2461659040 0;
BA_ "GenMsgCycleTime" BO_ 2461659040 100;
BA_ "GenMsgSendType" BO_ 2461593504 0;
BA_ "GenMsgCycleTime" BO_ 2461593504 100;
BA_ "GenMsgSendType" BO_ 2461527968 0;
BA_ "GenMsgCycleTime" BO_ 2461527968 100;
BA_ "GenMsgSendType" BO_ 2461462432 0;
BA_ "GenMsgCycleTime" BO_ 2461462432 100;
BA_ "GenMsgSendType" BO_ 2461396896 0;
BA_ "GenMsgCycleTime" BO_ 2461396896 100;
BA_ "GenMsgSendType" BO_ 2461331360 0;
BA_ "GenMsgCycleTime" BO_ 2461331360 100;
BA_ "GenMsgCycleTime" BO_ 2461265824 100;
BA_ "GenMsgSendType" BO_ 2461265824 0;
BA_ "GenMsgSendType" BO_ 2461200288 0;
BA_ "GenMsgCycleTime" BO_ 2461200288 100;
BA_ "GenMsgSendType" BO_ 2461134752 0;
BA_ "GenMsgCycleTime" BO_ 2461134752 100;
BA_ "GenMsgSendType" BO_ 2461069216 0;
BA_ "GenMsgCycleTime" BO_ 2461069216 100;
BA_ "GenMsgSendType" BO_ 2461003680 0;
BA_ "GenMsgCycleTime" BO_ 2461003680 100;
BA_ "GenMsgSendType" BO_ 2460938144 0;
BA_ "GenMsgCycleTime" BO_ 2460938144 100;
BA_ "GenMsgSendType" BO_ 2460872608 0;
BA_ "GenMsgCycleTime" BO_ 2460872608 100;
BA_ "GenMsgSendType" BO_ 2460807072 0;
BA_ "GenMsgCycleTime" BO_ 2460807072 100;
BA_ "GenMsgSendType" BO_ 2460741536 0;
BA_ "GenMsgCycleTime" BO_ 2460741536 100;
BA_ "GenMsgSendType" BO_ 2460676000 0;
BA_ "GenMsgCycleTime" BO_ 2460676000 100;
BA_ "GenMsgSendType" BO_ 2460610464 0;
BA_ "GenMsgCycleTime" BO_ 2460610464 100;
BA_ "GenMsgSendType" BO_ 2460544928 0;
BA_ "GenMsgCycleTime" BO_ 2460544928 100;
BA_ "GenMsgSendType" BO_ 2460479392 0;
BA_ "GenMsgCycleTime" BO_ 2460479392 100;
BA_ "GenMsgSendType" BO_ 2460413856 0;
BA_ "GenMsgCycleTime" BO_ 2460413856 100;
BA_ "GenMsgSendType" BO_ 2460348320 0;
BA_ "GenMsgCycleTime" BO_ 2460348320 100;
BA_ "GenMsgSendType" BO_ 2460282784 0;
BA_ "GenMsgCycleTime" BO_ 2460282784 100;
BA_ "GenMsgSendType" BO_ 2460217248 0;
BA_ "GenMsgCycleTime" BO_ 2460217248 100;
BA_ "GenMsgSendType" BO_ 2460151712 0;
BA_ "GenMsgCycleTime" BO_ 2460151712 100;
BA_ "GenMsgSendType" BO_ 2460086176 0;
BA_ "GenMsgCycleTime" BO_ 2460086176 100;
BA_ "GenMsgSendType" BO_ 2449797024 0;
BA_ "GenMsgRequestable" BO_ 2449797024 0;
BA_ "GenMsgCycleTime" BO_ 2449797024 1000;
BA_ "GenMsgCycleTime" BO_ 2449665952 1000;
BA_ "GenMsgRequestable" BO_ 2449665952 0;
BA_ "GenMsgSendType" BO_ 2449665952 0;
BA_ "GenMsgSendType" BO_ 2465267951 2;
BA_ "GenMsgSendType" BO_ 2453709039 2;
BA_ "GenMsgSendType" BO_ 2451959712 2;
BA_ "GenMsgRequestable" BO_ 2454757615 0;
BA_ "GenMsgSendType" BO_ 2454757615 0;
BA_ "GenMsgCycleTime" BO_ 2454757615 1000;
BA_ "GenMsgSendType" BO_ 2450911136 2;
BA_ "GenMsgSendType" BO_ 2465333487 2;
BA_ "GenMsgSendType" BO_ 2449600416 0;
BA_ "GenMsgCycleTime" BO_ 2449600416 100;
BA_ "GenMsgRequestable" BO_ 2449600416 0;
